VERSION "created by canmatrix"

NS_ :

BS_:

BU_: IBCM ADCU USS SRRL SRRR FRR PBOX DA Meter CCM Sonar BLE ACU CDC None METER Tester

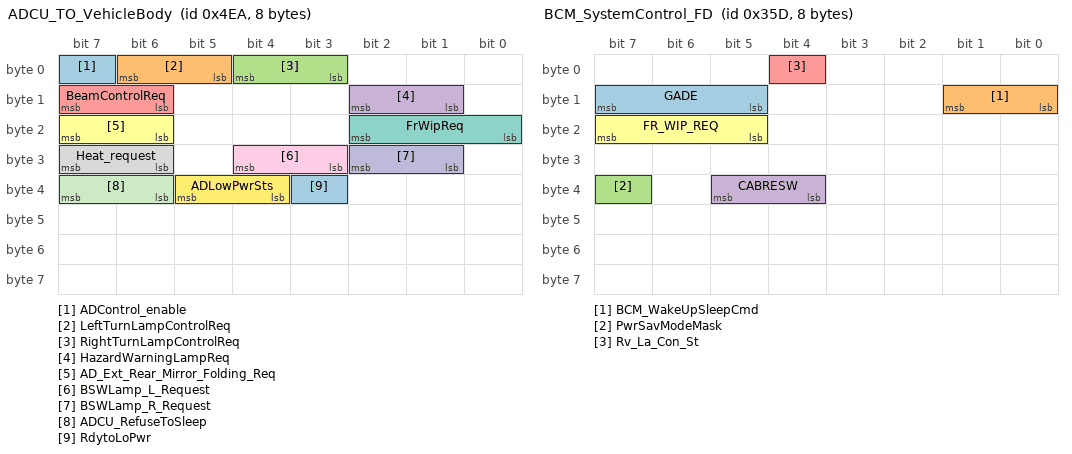
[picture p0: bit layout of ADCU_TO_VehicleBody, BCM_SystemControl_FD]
BO_ 1258 ADCU_TO_VehicleBody: 8 ADCU
 SG_ ADControl_enable : 7|1@0+ (1,0) [0|1] "_" IBCM
 SG_ LeftTurnLampControlReq : 6|2@0+ (1,0) [0|3] "" IBCM
 SG_ RightTurnLampControlReq : 4|2@0+ (1,0) [0|3] "" IBCM
 SG_ HazardWarningLampReq : 10|2@0+ (1,0) [0|3] "" IBCM
 SG_ BeamControlReq : 15|2@0+ (1,0) [0|3] "" IBCM
 SG_ AD_Ext_Rear_Mirror_Folding_Req : 23|2@0+ (1,0) [0|3] "" IBCM
 SG_ FrWipReq : 18|3@0+ (1,0) [0|7] "" IBCM
 SG_ Heat_request : 31|2@0+ (1,0) [0|3] "" IBCM
 SG_ BSWLamp_L_Request : 28|2@0+ (1,0) [0|3] "" IBCM
 SG_ BSWLamp_R_Request : 26|2@0+ (1,0) [0|3] "" IBCM
 SG_ ADCU_RefuseToSleep : 39|2@0+ (1,0) [0|3] "" IBCM
 SG_ ADLowPwrSts : 37|2@0+ (1,0) [0|3] "" IBCM
 SG_ RdytoLoPwr : 35|1@0+ (1,0) [0|1] "" IBCM

BO_ 1293 VCM_HMI_GeneralData1: 8 VCM
 SG_ BAT_RQ : 47|2@0+ (1,0) [0|3] "" ADCU

BO_ 861 BCM_SystemControl_FD: 8 IBCM
 SG_ GADE : 15|3@0+ (1,0) [0|7] "" ADCU,USS,SRRL,SRRR,FRR,PBOX
 SG_ BCM_WakeUpSleepCmd : 9|2@0+ (1,0) [0|3] "" ADCU,USS
 SG_ PwrSavModeMask : 39|1@0+ (1,0) [0|1] "" ADCU
 SG_ CABRESW : 37|2@0+ (1,0) [0|3] "" ADCU
 SG_ Rv_La_Con_St : 4|1@0+ (1,0) [0|1] "" ADCU
 SG_ FR_WIP_REQ : 23|3@0+ (1,0) [0|7] "" ADCU,USS

BO_ 536 PEPS_Message_Sts: 3 IBCM
 SG_ PEPS_POWER_MODE : 7|3@0+ (1,0) [0|7] "" ADCU

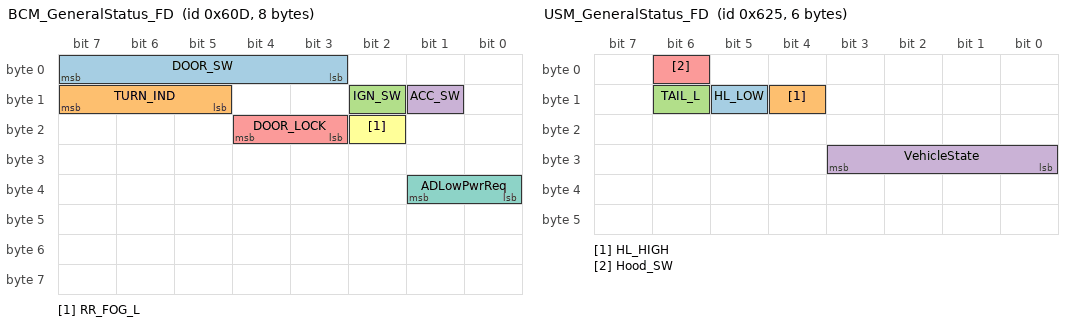
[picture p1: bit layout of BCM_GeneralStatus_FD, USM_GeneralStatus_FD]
BO_ 1549 BCM_GeneralStatus_FD: 8 IBCM_BCM
 SG_ DOOR_SW : 7|5@0+ (1,0) [0|31] "" ADCU,USS
 SG_ TURN_IND : 15|3@0+ (1,0) [0|7] "" ADCU,USS
 SG_ IGN_SW : 10|1@0+ (1,0) [0|1] "" ADCU,USS
 SG_ ACC_SW : 9|1@0+ (1,0) [0|1] "" ADCU,USS
 SG_ DOOR_LOCK : 20|2@0+ (1,0) [0|3] "" ADCU
 SG_ RR_FOG_L : 18|1@0+ (1,0) [0|1] "" ADCU
 SG_ ADLowPwrReq : 33|2@0+ (1,0) [0|3] "" ADCU

BO_ 1573 USM_GeneralStatus_FD: 6 IBCM_USM
 SG_ HL_LOW : 13|1@0+ (1,0) [0|1] "" ADCU,USS
 SG_ HL_HIGH : 12|1@0+ (1,0) [0|1] "" ADCU,USS
 SG_ TAIL_L : 14|1@0+ (1,0) [0|1] "" ADCU,USS
 SG_ VehicleState : 27|4@0+ (1,0) [0|15] "" ADCU,USS
 SG_ Hood_SW : 6|1@0+ (1,0) [0|1] "" ADCU,USS

BO_ 1532 ICOMB_Sw_Msg: 8 COMBI_SW
 SG_ HighLampChangeSWSts : 21|2@0+ (1,0) [0|3] "" ADCU
 SG_ TurnLampSWSts : 31|3@0+ (1,0) [0|7] "" ADCU

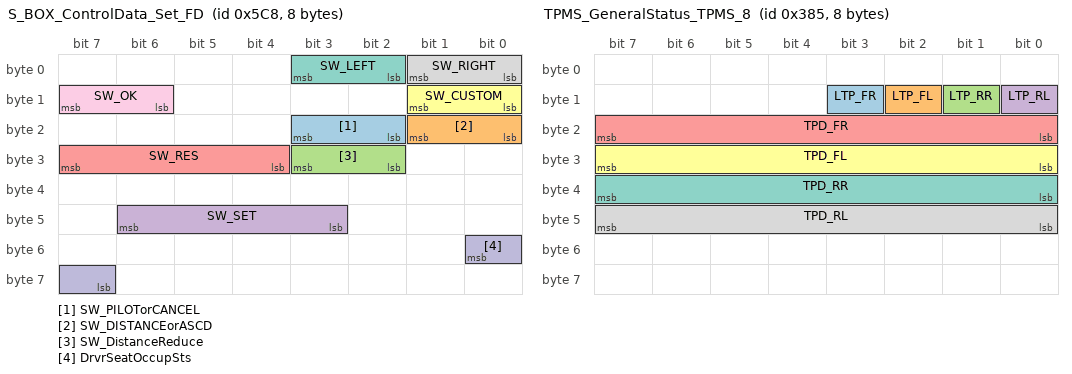
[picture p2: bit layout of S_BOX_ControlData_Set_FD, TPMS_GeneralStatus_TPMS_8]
BO_ 1480 S_BOX_ControlData_Set_FD: 8 IBCM_SBOX
 SG_ SW_PILOTorCANCEL : 19|2@0+ (1,0) [0|3] "" ADCU
 SG_ SW_DISTANCEorASCD : 17|2@0+ (1,0) [0|3] "" ADCU
 SG_ SW_DistanceReduce : 27|2@0+ (1,0) [0|3] "" ADCU
 SG_ SW_SET : 46|4@0+ (1,0) [0|15] "" ADCU
 SG_ SW_RES : 31|4@0+ (1,0) [0|15] "" ADCU
 SG_ SW_CUSTOM : 9|2@0+ (1,0) [0|3] "" ADCU
 SG_ SW_LEFT : 3|2@0+ (1,0) [0|3] "" ADCU,USS
 SG_ SW_RIGHT : 1|2@0+ (1,0) [0|3] "" ADCU,USS
 SG_ SW_OK : 15|2@0+ (1,0) [0|3] "" ADCU,USS
 SG_ DrvrSeatOccupSts : 48|2@0+ (1,0) [0|3] "" ADCU

BO_ 901 TPMS_GeneralStatus_TPMS_8: 8 IBCM_TPMS
 SG_ LTP_FR : 11|1@0+ (1,0) [0|1] "" ADCU,USS
 SG_ LTP_FL : 10|1@0+ (1,0) [0|1] "" ADCU,USS
 SG_ LTP_RR : 9|1@0+ (1,0) [0|1] "" ADCU,USS
 SG_ LTP_RL : 8|1@0+ (1,0) [0|1] "" ADCU,USS
 SG_ TPD_FR : 23|8@0+ (1.7199999999999999733546474089962430298328399658203125,0) [0|438.6] "KPA" ADCU
 SG_ TPD_FL : 31|8@0+ (1.7199999999999999733546474089962430298328399658203125,0) [0|438.6] "KPA" ADCU
 SG_ TPD_RR : 39|8@0+ (1.7199999999999999733546474089962430298328399658203125,0) [0|438.6] "KPA" ADCU
 SG_ TPD_RL : 47|8@0+ (1.7199999999999999733546474089962430298328399658203125,0) [0|438.6] "KPA" ADCU

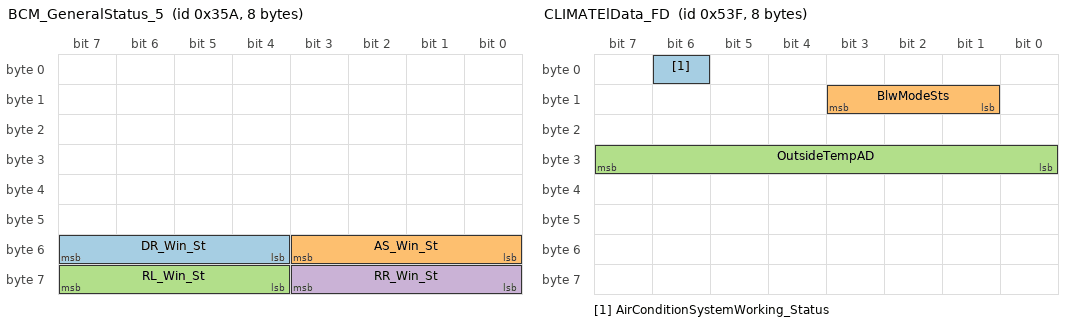
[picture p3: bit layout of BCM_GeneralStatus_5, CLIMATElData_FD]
BO_ 858 BCM_GeneralStatus_5: 8 IBCM_BCM
 SG_ DR_Win_St : 55|4@0+ (1,0) [0|15] "" ADCU
 SG_ AS_Win_St : 51|4@0+ (1,0) [0|15] "" ADCU
 SG_ RL_Win_St : 63|4@0+ (1,0) [0|15] "" ADCU
 SG_ RR_Win_St : 59|4@0+ (1,0) [0|15] "" ADCU

BO_ 1338 FrontRoomLoad_1_FD: 8 IBCM_BCM
 SG_ FrWipSts : 6|2@0+ (1,0) [0|3] "" ADCU,USS
 SG_ LowBatVFb : 15|14@0+ (0.0009765625,3) [3|18] "V" ADCU,SRRL,SRRR

BO_ 1339 LeftBodyLoad_1_FD: 64 IBCM
 SG_ LeftBswLedSts : 18|2@0+ (1,0) [0|3] "" ADCU,SRRL,SRRR
 SG_ RightBswLedSts : 31|2@0+ (1,0) [0|3] "" ADCU,SRRL,SRRR

BO_ 1340 RightBodyLoad_1_FD: 64 IBCM_SBOX
 SG_ PassSeatOccupSts : 23|2@0+ (1,0) [0|3] "" ADCU
 SG_ ExtRMirFldSts : 53|2@0+ (1,0) [0|3] "" ADCU,USS

BO_ 1342 CabinBodyLoad_1: 8 IBCM
 SG_ BcmRainSizeSts : 63|3@0+ (1,0) [0|7] "" ADCU,USS

BO_ 1343 CLIMATElData_FD: 8 IBCM_HVAC
 SG_ AirConditionSystemWorking_Status : 6|1@0+ (1,0) [0|1] "" ADCU
 SG_ BlwModeSts : 11|3@0+ (1,0) [0|7] "" ADCU
 SG_ OutsideTempAD : 31|8@0+ (0.5,-40) [-40|80] "C" ADCU

BO_ 1351 IBCM_HVAC_Info1_FD: 8 IBCM_HVAC
 SG_ Ambient_Temp_Value : 15|8@0+ (0.5,-40) [-40|87] "C" ADCU,USS
 SG_ Inner_Temp_Value : 23|8@0+ (0.5,-40) [-40|87] "C" ADCU

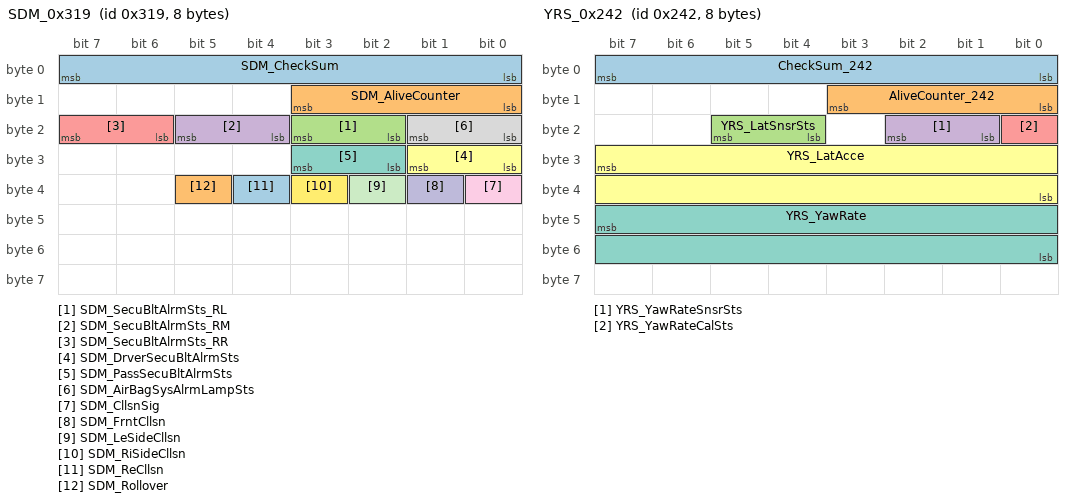
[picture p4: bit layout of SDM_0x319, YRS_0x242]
BO_ 793 SDM_0x319: 8 ACU
 SG_ SDM_CheckSum : 7|8@0+ (1,0) [0|255] "" ADCU,USS
 SG_ SDM_AliveCounter : 11|4@0+ (1,0) [0|15] "" ADCU,USS
 SG_ SDM_SecuBltAlrmSts_RL : 19|2@0+ (1,0) [0|3] "" ADCU,USS
 SG_ SDM_SecuBltAlrmSts_RM : 21|2@0+ (1,0) [0|3] "" ADCU,USS
 SG_ SDM_SecuBltAlrmSts_RR : 23|2@0+ (1,0) [0|3] "" ADCU,USS
 SG_ SDM_DrverSecuBltAlrmSts : 25|2@0+ (1,0) [0|3] "" ADCU,USS
 SG_ SDM_PassSecuBltAlrmSts : 27|2@0+ (1,0) [0|3] "" ADCU,USS
 SG_ SDM_AirBagSysAlrmLampSts : 17|2@0+ (1,0) [0|3] "" ADCU,USS
 SG_ SDM_CllsnSig : 32|1@0+ (1,0) [0|1] "" ADCU,USS
 SG_ SDM_FrntCllsn : 33|1@0+ (1,0) [0|1] "" ADCU,USS
 SG_ SDM_LeSideCllsn : 34|1@0+ (1,0) [0|1] "" ADCU,USS
 SG_ SDM_RiSideCllsn : 35|1@0+ (1,0) [0|1] "" ADCU,USS
 SG_ SDM_ReCllsn : 36|1@0+ (1,0) [0|1] "" ADCU,USS
 SG_ SDM_Rollover : 37|1@0+ (1,0) [0|1] "" ADCU,USS

BO_ 578 YRS_0x242: 8 ACU
 SG_ CheckSum_242 : 7|8@0+ (1,0) [0|255] "" ADCU,USS,SRRL,SRRR,FRR
 SG_ AliveCounter_242 : 11|4@0+ (1,0) [0|15] "" ADCU,USS,SRRL,SRRR,FRR
 SG_ YRS_LatSnsrSts : 21|2@0+ (1,0) [0|3] "" ADCU,USS
 SG_ YRS_YawRateSnsrSts : 18|2@0+ (1,0) [0|3] "" ADCU,USS
 SG_ YRS_YawRateCalSts : 16|1@0+ (1,0) [0|1] "" ADCU,USS
 SG_ YRS_LatAcce : 31|16@0+ (0.001,-2) [-2|2] "g" ADCU,USS,SRRL,SRRR,FRR
 SG_ YRS_YawRate : 47|16@0+ (0.01,-180) [-180|180] "deg_s" ADCU,USS,SRRL,SRRR,FRR

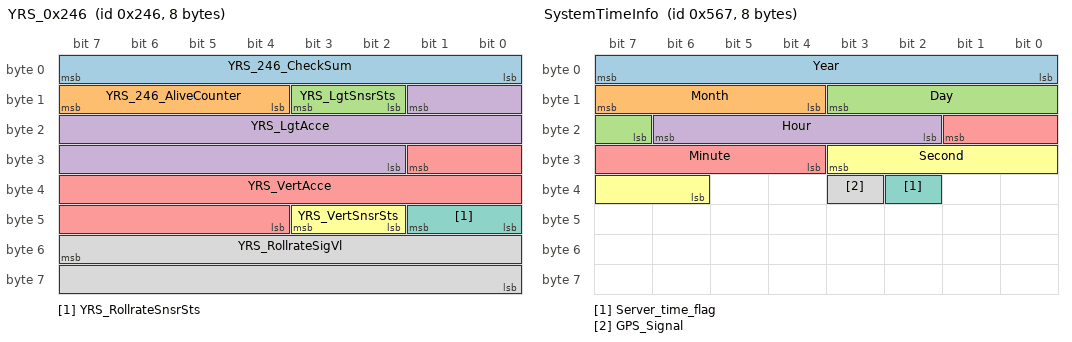
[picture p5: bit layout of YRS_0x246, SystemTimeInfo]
BO_ 582 YRS_0x246: 8 ACU
 SG_ YRS_246_CheckSum : 7|8@0+ (1,0) [0|255] "" ADCU,USS,SRRL,SRRR,FRR
 SG_ YRS_246_AliveCounter : 15|4@0+ (1,0) [0|15] "" ADCU,USS,SRRL,SRRR,FRR
 SG_ YRS_LgtSnsrSts : 11|2@0+ (1,0) [0|3] "" ADCU,USS
 SG_ YRS_LgtAcce : 9|16@0+ (0.001,-2) [-2|2] "g" ADCU,USS,SRRL,SRRR,FRR
 SG_ YRS_VertAcce : 25|14@0+ (0.001,-5) [-5|5] "g" ADCU
 SG_ YRS_VertSnsrSts : 43|2@0+ (1,0) [0|3] "" ADCU
 SG_ YRS_RollrateSnsrSts : 41|2@0+ (1,0) [0|3] "" ADCU
 SG_ YRS_RollrateSigVl : 55|16@0+ (0.01,-300) [-300|300] "deg_s" ADCU

BO_ 1383 SystemTimeInfo: 8 DA
 SG_ Year : 7|8@0+ (1,2000) [2000|2255] "" ADCU,USS
 SG_ Month : 15|4@0+ (1,0) [0|15] "" ADCU,USS
 SG_ Day : 11|5@0+ (1,0) [0|31] "" ADCU,USS
 SG_ Hour : 22|5@0+ (1,0) [0|31] "" ADCU,USS
 SG_ Minute : 17|6@0+ (1,0) [0|63] "" ADCU,USS
 SG_ Second : 27|6@0+ (1,0) [0|63] "" ADCU,USS
 SG_ Server_time_flag : 34|1@0+ (1,0) [0|1] "" ADCU,USS
 SG_ GPS_Signal : 35|1@0+ (1,0) [0|1] "" ADCU,USS

BO_ 1477 CLUSTER_GeneralStatus: 8 Meter
 SG_ DIS_TOTAL : 15|24@0+ (0.1000000000000000055511151231257827021181583404541015625,0) [0|1600000] "km" ADCU,USS

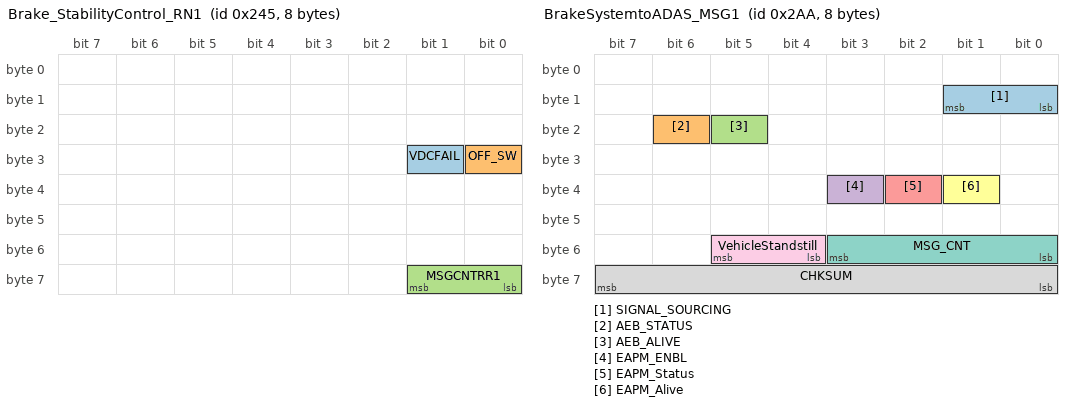
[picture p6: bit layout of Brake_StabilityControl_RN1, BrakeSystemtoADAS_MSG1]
BO_ 581 Brake_StabilityControl_RN1: 8 IBC
 SG_ VDCFAIL : 25|1@0+ (1,0) [0|1] "" USS
 SG_ OFF_SW : 24|1@0+ (1,0) [0|1] "" USS
 SG_ MSGCNTRR1 : 57|2@0+ (1,0) [0|3] "" USS

BO_ 682 BrakeSystemtoADAS_MSG1: 8 IBC
 SG_ SIGNAL_SOURCING : 9|2@0+ (1,0) [0|3] "" USS
 SG_ AEB_STATUS : 22|1@0+ (1,0) [0|1] "" USS
 SG_ AEB_ALIVE : 21|1@0+ (1,0) [0|1] "" USS
 SG_ EAPM_ENBL : 35|1@0+ (1,0) [0|1] "" USS
 SG_ EAPM_Status : 34|1@0+ (1,0) [0|1] "" USS
 SG_ EAPM_Alive : 33|1@0+ (1,0) [0|1] "" USS
 SG_ MSG_CNT : 51|4@0+ (1,0) [0|15] "" USS
 SG_ CHKSUM : 63|8@0+ (1,0) [0|255] "" USS
 SG_ VehicleStandstill : 53|2@0+ (1,0) [0|3] "" USS

BO_ 852 Brake_GeneralData: 8 IBC
 SG_ MSGCNTR : 44|2@0+ (1,0) [0|3] "" USS
 SG_ STPLMSW : 53|2@0+ (1,0) [0|3] "" USS

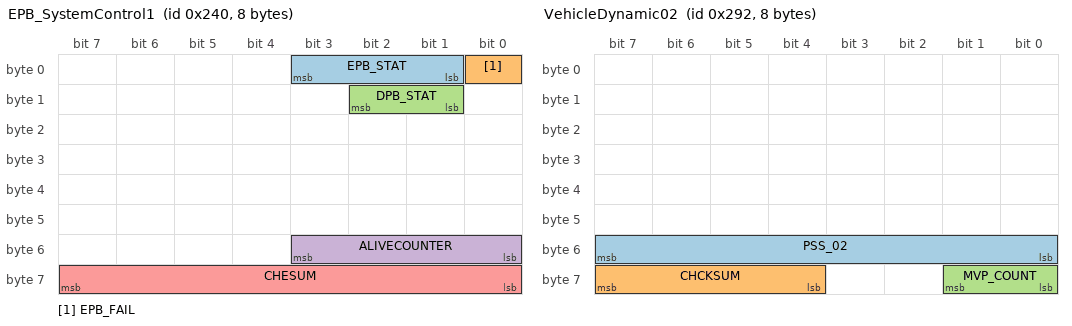
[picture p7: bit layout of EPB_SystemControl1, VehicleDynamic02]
BO_ 576 EPB_SystemControl1: 8 IBC
 SG_ EPB_STAT : 3|3@0+ (1,0) [0|7] "" USS
 SG_ EPB_FAIL : 0|1@0+ (1,0) [0|1] "" USS
 SG_ DPB_STAT : 10|2@0+ (1,0) [0|3] "" USS
 SG_ ALIVECOUNTER : 51|4@0+ (1,0) [0|15] "" USS
 SG_ CHESUM : 63|8@0+ (1,0) [0|255] "" USS

BO_ 658 VehicleDynamic02: 8 IBC
 SG_ PSS_02 : 55|8@0+ (1,0) [0|254] "bar" USS
 SG_ CHCKSUM : 63|4@0+ (1,0) [0|15] "" USS
 SG_ MVP_COUNT : 57|2@0+ (1,0) [0|3] "" USS

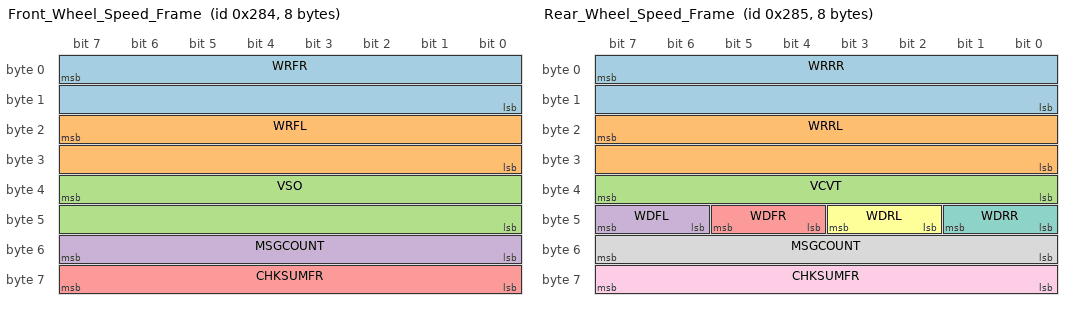
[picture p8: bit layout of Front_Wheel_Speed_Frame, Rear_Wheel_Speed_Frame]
BO_ 644 Front_Wheel_Speed_Frame: 8 IBC
 SG_ WRFR : 7|16@0+ (0.04166666666666669904817155156706576235592365264892578125,0) [0|2730.58333333333] "rpm" USS
 SG_ WRFL : 23|16@0+ (0.04166666666666669904817155156706576235592365264892578125,0) [0|2730.58333333333] "rpm" USS
 SG_ VSO : 39|16@0+ (0.01000000000000000020816681711721685132943093776702880859375,0) [0|655.34] "km_h" USS
 SG_ MSGCOUNT : 55|8@0+ (1,0) [0|255] "" USS
 SG_ CHKSUMFR : 63|8@0+ (1,0) [0|255] "" USS

BO_ 645 Rear_Wheel_Speed_Frame: 8 IBC
 SG_ WRRR : 7|16@0+ (0.04166666666666669904817155156706576235592365264892578125,0) [0|2730.58333333333] "rpm" USS
 SG_ WRRL : 23|16@0+ (0.04166666666666669904817155156706576235592365264892578125,0) [0|2730.58333333333] "rpm" USS
 SG_ VCVT : 39|8@0+ (1,0) [0|255] "km_h" USS
 SG_ WDFL : 47|2@0+ (1,0) [0|3] "" USS
 SG_ WDFR : 45|2@0+ (1,0) [0|3] "" USS
 SG_ WDRL : 43|2@0+ (1,0) [0|3] "" USS
 SG_ WDRR : 41|2@0+ (1,0) [0|3] "" USS
 SG_ MSGCOUNT : 55|8@0+ (1,0) [0|255] "" USS
 SG_ CHKSUMFR : 63|8@0+ (1,0) [0|255] "" USS

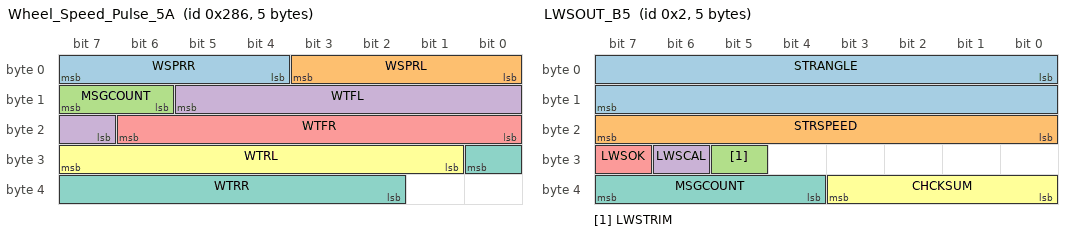
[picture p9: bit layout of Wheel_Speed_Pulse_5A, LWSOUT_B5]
BO_ 646 Wheel_Speed_Pulse_5A: 5 IBC
 SG_ WSPRR : 7|4@0+ (1,0) [0|14] "" USS
 SG_ WSPRL : 3|4@0+ (1,0) [0|14] "" USS
 SG_ MSGCOUNT : 15|2@0+ (1,0) [0|3] "" USS
 SG_ WTFL : 13|7@0+ (1,0) [1|96] "top" USS
 SG_ WTFR : 22|7@0+ (1,0) [1|96] "top" USS
 SG_ WTRL : 31|7@0+ (1,0) [1|96] "top" USS
 SG_ WTRR : 24|7@0+ (1,0) [1|96] "top" USS

BO_ 2 LWSOUT_B5: 5 EPS
 SG_ STRANGLE : 0|16@1- (0.1000000000000000055511151231257827021181583404541015625,0) [-780|780] "deg" USS
 SG_ STRSPEED : 16|8@1+ (4,0) [0|1016] "deg_s" USS
 SG_ LWSTRIM : 29|1@1+ (1,0) [0|1] "" USS
 SG_ LWSCAL : 30|1@1+ (1,0) [0|1] "" USS
 SG_ LWSOK : 31|1@1+ (1,0) [0|1] "" USS
 SG_ CHCKSUM : 32|4@1+ (1,0) [0|15] "" USS
 SG_ MSGCOUNT : 36|4@1+ (1,0) [0|15] "" USS

BO_ 500 VCM_ADCU_01: 8 VCM
 SG_ PT_MotoSpd : 7|16@0- (1,0) [-32768|32767] "rpm" USS
 SG_ PT_MotoSpdV : 41|1@0+ (1,0) [0|1] "" USS

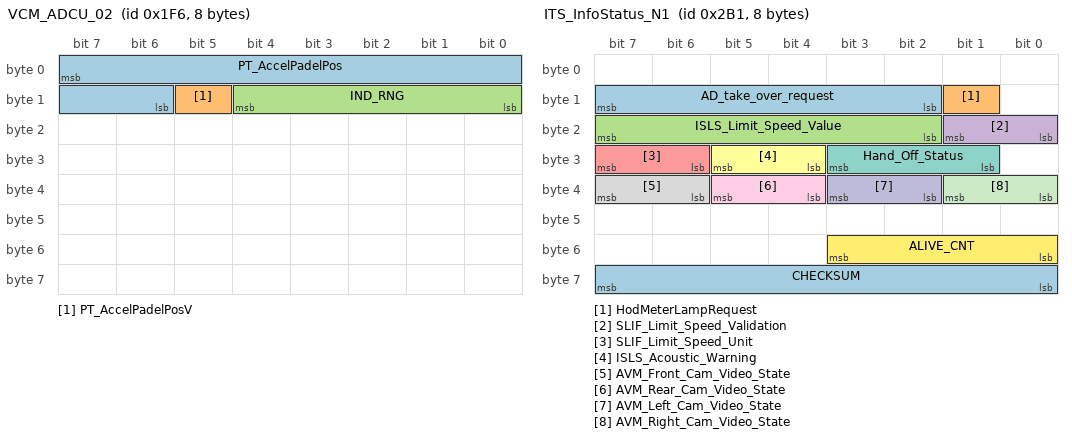
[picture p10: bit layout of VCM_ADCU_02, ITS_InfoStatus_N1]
BO_ 502 VCM_ADCU_02: 8 VCM
 SG_ PT_AccelPadelPos : 7|10@0+ (0.1000000000000000055511151231257827021181583404541015625,0) [0|102.3] "pct" USS
 SG_ PT_AccelPadelPosV : 13|1@0+ (1,0) [0|1] "" USS
 SG_ IND_RNG : 12|5@0+ (1,0) [0|31] "" USS

BO_ 384 ECM_TorqueControl_RN1: 8 VCM
 SG_ P_RUN : 51|4@0+ (1,0) [0|15] "" USS
 SG_ ETCFAIL : 63|3@0+ (1,0) [0|7] "" USS

BO_ 1361 ECM_GeneralStatus: 8 VCM
 SG_ ENG_STA : 41|2@0+ (1,0) [0|3] "" USS

BO_ 1449 VCM_HMI_GeneralData5_Quk: 8 VCM
 SG_ DTE_VCM : 15|13@0+ (0.1000000000000000055511151231257827021181583404541015625,0) [0|819] "km" ADCU

BO_ 689 ITS_InfoStatus_N1: 8 ADCU
 SG_ AD_take_over_request : 15|6@0+ (1,0) [0|63] "" DA,Meter
 SG_ HodMeterLampRequest : 9|1@0+ (1,0) [0|1] "" DA,Meter
 SG_ ISLS_Limit_Speed_Value : 23|6@0+ (1,0) [0|63] "" DA,Meter
 SG_ SLIF_Limit_Speed_Validation : 17|2@0+ (1,0) [0|3] "" DA,Meter
 SG_ SLIF_Limit_Speed_Unit : 31|2@0+ (1,0) [0|3] "" DA,Meter
 SG_ ISLS_Acoustic_Warning : 29|2@0+ (1,0) [0|3] "" DA,Meter
 SG_ Hand_Off_Status : 27|3@0+ (1,0) [0|7] "" DA,Meter,CCM
 SG_ AVM_Front_Cam_Video_State : 39|2@0+ (1,0) [0|3] "" DA,Meter
 SG_ AVM_Rear_Cam_Video_State : 37|2@0+ (1,0) [0|3] "" DA,Meter
 SG_ AVM_Left_Cam_Video_State : 35|2@0+ (1,0) [0|3] "" DA,Meter
 SG_ AVM_Right_Cam_Video_State : 33|2@0+ (1,0) [0|3] "" DA,Meter
 SG_ ALIVE_CNT : 51|4@0+ (1,0) [0|15] "" DA,Meter
 SG_ CHECKSUM : 63|8@0+ (1,0) [0|255] "" DA,Meter

BO_ 695 ITS_InfoStatus_N2: 8 ADCU
 SG_ PCW_PreWarning : 6|1@0+ (1,0) [0|1] "" DA,Meter
 SG_ AEB_Active : 5|1@0+ (1,0) [0|1] "" DA,Meter
 SG_ CDW_Active : 0|1@0+ (1,0) [0|1] "" DA,Meter
 SG_ ESS_Active : 15|2@0+ (1,0) [0|3] "" DA,Meter
 SG_ fcta_left_warning : 13|1@0+ (1,0) [0|1] "" DA,Meter
 SG_ fcta_front_warning : 12|1@0+ (1,0) [0|1] "" DA,Meter
 SG_ fcta_right_warning : 11|1@0+ (1,0) [0|1] "" DA,Meter
 SG_ fctb_left_warning : 23|1@0+ (1,0) [0|1] "" DA,Meter
 SG_ fctb_front_warning : 22|1@0+ (1,0) [0|1] "" DA,Meter
 SG_ fctb_right_warning : 21|1@0+ (1,0) [0|1] "" DA,Meter
 SG_ rctb_left_warning : 20|1@0+ (1,0) [0|1] "" DA,Meter
 SG_ rctb_rear_warning : 19|1@0+ (1,0) [0|1] "" DA,Meter
 SG_ rctb_right_warning : 18|1@0+ (1,0) [0|1] "" DA,Meter
 SG_ ELK_active : 31|3@0+ (1,0) [0|7] "" DA,Meter
 SG_ rcta_left_warning : 10|1@0+ (1,0) [0|1] "" DA,Meter
 SG_ rcta_rear_warning : 9|1@0+ (1,0) [0|1] "" DA,Meter
 SG_ rcta_right_warning : 8|1@0+ (1,0) [0|1] "" DA,Meter
 SG_ rcw_warning : 28|1@0+ (1,0) [0|1] "" DA,Meter
 SG_ left_bsw_warning : 27|2@0+ (1,0) [0|3] "" DA,Meter
 SG_ right_bsw_warning : 25|2@0+ (1,0) [0|3] "" DA,Meter
 SG_ left_dow_warning : 39|2@0+ (1,0) [0|3] "" DA,Meter,CCM
 SG_ right_dow_warning : 37|2@0+ (1,0) [0|3] "" DA,Meter,CCM
 SG_ LDW_Warning : 35|2@0+ (1,0) [0|3] "" DA,Meter
 SG_ LDP_Active : 33|2@0+ (1,0) [0|3] "" DA,Meter
 SG_ STS_D_MEB : 47|3@0+ (1,0) [0|7] "" DA,Meter
 SG_ SET_MEB : 44|2@0+ (1,0) [0|3] "" DA,Meter
 SG_ STS_W_MEB : 42|2@0+ (1,0) [0|3] "" DA,Meter
 SG_ SOUND_MEB : 40|1@0+ (1,0) [0|1] "" DA,Meter
 SG_ ALIVE_CNT : 51|4@0+ (1,0) [0|15] "" DA,Meter
 SG_ CHECKSUM : 63|8@0+ (1,0) [0|255] "" DA,Meter

BO_ 1260 ITS_InfoStatus_N2_2: 64 ADCU
 SG_ ACC_HEADW_SET : 7|3@0+ (1,0) [0|7] "" DA,Meter
 SG_ VDC_NOT_ACTIVATED : 4|1@0+ (1,0) [0|1] "" DA,Meter
 SG_ ACC_DrSeSp : 15|8@0+ (1,0) [0|255] "km_h" DA,Meter
 SG_ ACC_DisToTgt : 23|8@0+ (1,0) [0|255] "m" DA,Meter
 SG_ ACC_TgtDet : 31|1@0+ (1,0) [0|1] "" DA,Meter
 SG_ ACC_GoNoti : 30|1@0+ (1,0) [0|1] "" DA,Meter
 SG_ CP_Status : 29|4@0+ (1,0) [0|15] "" DA,Meter
 SG_ MSG_ILC_Opera : 25|2@0+ (1,0) [0|3] "" DA,Meter
 SG_ CP_PLC_Status : 39|4@0+ (1,0) [0|15] "" DA,Meter
 SG_ CP_PLC_Direction : 35|2@0+ (1,0) [0|3] "" DA,Meter
 SG_ Message_AD_unActive_Reason : 47|4@0+ (1,0) [0|15] "" DA,Meter
 SG_ ACC_Status : 43|4@0+ (1,0) [0|15] "" DA,Meter
 SG_ AD_Notice_Information : 55|8@0+ (1,0) [0|255] "" DA,Meter
 SG_ ISLC_Comfirm_Request : 57|1@0+ (1,0) [0|1] "" DA,Meter
 SG_ STATUS_CHANGE_ALERT : 56|1@0+ (1,0) [0|1] "" DA,Meter
 SG_ HnpLastDistance : 67|4@0+ (1,0) [0|15] "" DA,Meter
 SG_ AD_ICON : 79|5@0+ (1,0) [0|31] "" DA,Meter
 SG_ HNP_Status : 87|6@0+ (1,0) [0|63] "" DA,Meter
 SG_ HNP_Lane_Change_Status : 91|4@0+ (1,0) [0|15] "" DA,Meter
 SG_ Message_AD_Error : 103|1@0+ (1,0) [0|1] "" DA,Meter
 SG_ Message_Inclement_weather : 102|2@0+ (1,0) [0|3] "" DA,Meter
 SG_ Message_FR_Camera_block : 100|1@0+ (1,0) [0|1] "" DA,Meter
 SG_ Message_FR_Radar_block : 99|1@0+ (1,0) [0|1] "" DA,Meter
 SG_ Msg_Side_Fisheye_Camera_block : 98|1@0+ (1,0) [0|1] "" DA,Meter
 SG_ Message_Rear_Camera_block : 97|1@0+ (1,0) [0|1] "" DA,Meter
 SG_ Message_Side_Rear_Radar_block : 96|1@0+ (1,0) [0|1] "" DA,Meter
 SG_ SETTING_LDW_LDP_Status : 111|2@0+ (1,0) [0|3] "" DA,Meter
 SG_ LDW__INFO : 109|3@0+ (1,0) [0|7] "" DA,Meter
 SG_ SET_LDW_SENS_Status : 106|3@0+ (1,0) [0|7] "" DA,Meter
 SG_ AEBS_INFO : 117|3@0+ (1,0) [0|7] "" DA,Meter
 SG_ SET_FCW_SENS_Status : 114|3@0+ (1,0) [0|7] "" DA,Meter
 SG_ SETTING_AEBS_Status : 127|2@0+ (1,0) [0|3] "" DA,Meter
 SG_ LDP_INFO : 123|3@0+ (1,0) [0|7] "" DA,Meter
 SG_ SETTING_ELK_Status : 135|2@0+ (1,0) [0|3] "" DA,Meter
 SG_ ELK_INFO : 133|3@0+ (1,0) [0|7] "" DA,Meter
 SG_ SETTING_ESS_Status : 130|2@0+ (1,0) [0|3] "" DA,Meter
 SG_ ESS_INFO : 143|3@0+ (1,0) [0|7] "" DA,Meter
 SG_ SET_PILOT_STA : 140|3@0+ (1,0) [0|7] "" DA,Meter
 SG_ SET_ILC_STA : 151|2@0+ (1,0) [0|3] "" DA,Meter
 SG_ SET_IHC_STA : 149|2@0+ (1,0) [0|3] "" DA,Meter
 SG_ SET_PLC_STA : 147|2@0+ (1,0) [0|3] "" DA,Meter
 SG_ ISLS_INFO : 157|3@0+ (1,0) [0|7] "" DA,Meter
 SG_ SET_TSR_status : 154|2@0+ (1,0) [0|3] "" DA,Meter
 SG_ TSR_INFO : 167|3@0+ (1,0) [0|7] "" DA,Meter
 SG_ SET_TLA_status : 164|2@0+ (1,0) [0|3] "" DA,Meter
 SG_ SET_TLAS_status : 162|3@0+ (1,0) [0|3] "None" DA
 SG_ TLA__INFO : 175|3@0+ (1,0) [0|7] "" DA,Meter
 SG_ SET_RCTA_RCTB_status : 172|2@0+ (1,0) [0|3] "" DA,Meter
 SG_ RCTA_INFO : 170|3@0+ (1,0) [0|7] "" DA,Meter
 SG_ RCTB_INFO : 181|3@0+ (1,0) [0|7] "" DA,Meter
 SG_ SET_FCTA_FCTB_status : 178|2@0+ (1,0) [0|3] "" DA,Meter
 SG_ FCTA_INFO : 191|3@0+ (1,0) [0|7] "" DA,Meter
 SG_ FCTB_INFO : 186|3@0+ (1,0) [0|7] "" DA,Meter
 SG_ SET_BSW_status : 199|2@0+ (1,0) [0|3] "" DA,Meter
 SG_ BSW_INFO : 197|3@0+ (1,0) [0|7] "" DA,Meter
 SG_ SET_DOW_status : 194|2@0+ (1,0) [0|3] "" DA,Meter
 SG_ DOW_INFO : 207|3@0+ (1,0) [0|7] "" DA,Meter
 SG_ SET_RCW_status : 204|2@0+ (1,0) [0|3] "" DA,Meter
 SG_ RCW_INFO : 202|3@0+ (1,0) [0|7] "" DA,Meter
 SG_ SET_VOL_STA : 213|2@0+ (1,0) [0|3] "" DA,Meter
 SG_ SET_CDW_SENS_Status : 211|3@0+ (1,0) [0|7] "" DA,Meter
 SG_ SET_ISLC_OFT_STA : 223|5@0+ (1,-16) [-16|15] "pct" DA,Meter
 SG_ SETTING_CDW_Status : 218|2@0+ (1,0) [0|3] "" DA,Meter
 SG_ MSG_FR_Camera_H_Temp : 231|1@0+ (1,0) [0|1] "" DA,Meter
 SG_ MSG_RR_Camera_H_Temp : 230|1@0+ (1,0) [0|1] "" DA,Meter
 SG_ MSG_ADCU_H_Temp : 229|1@0+ (1,0) [0|1] "" DA,Meter
 SG_ MSG_fisheye_Camera_H_Temp : 228|1@0+ (1,0) [0|1] "" DA,Meter
 SG_ MSG_VDC_NO_Actived : 227|1@0+ (1,0) [0|1] "" DA,Meter
 SG_ SET_ISLS_STA : 239|3@0+ (1,0) [0|7] "" DA,Meter
 SG_ SALC_INFO : 236|3@0+ (1,0) [0|7] "" DA,Meter
 SG_ HNPDowngradeStatus : 247|3@0+ (1,0) [0|7] "" DA,Meter
 SG_ CPUpgradeStatus : 244|3@0+ (1,0) [0|7] "" DA,Meter
 SG_ HNPLaneChangeStyleStatus : 241|2@0+ (1,0) [0|3] "" DA,Meter
 SG_ HNPLanePreferenceStatus : 255|3@0+ (1,0) [0|7] "" DA,Meter
 SG_ TSR_DISP : 263|5@0+ (1,0) [0|31] "" DA,Meter
 SG_ TLA_Pattern : 258|3@0+ (1,0) [0|7] "" DA,Meter
 SG_ Left_Uturn_Indication : 271|3@0+ (1,0) [0|7] "" DA,Meter
 SG_ Turn_Left_Indication : 268|3@0+ (1,0) [0|7] "" DA,Meter
 SG_ Go_Stright_Indication : 279|3@0+ (1,0) [0|7] "" DA,Meter
 SG_ Trun_Right_Indication : 276|3@0+ (1,0) [0|7] "" DA,Meter
 SG_ TLA_Number : 287|4@0+ (1,0) [0|15] "" DA,Meter
 SG_ ALC_Confirm : 283|2@0+ (1,0) [0|3] "" DA,Meter
 SG_ DVR_InfoStatus : 281|2@0+ (1,0) [0|3] "" DA,Meter
 SG_ MESSAGE_DVR_WARN : 295|1@0+ (1,0) [0|1] "" DA,Meter
 SG_ CDW_INFO : 294|3@0+ (1,0) [0|7] "" DA,Meter
 SG_ AD_Safety_Event : 335|8@0+ (1,0) [0|1] "None" CCM
 SG_ CFDI_ALL_Sts : 495|2@0+ (1,0) [0|3] "" DA
 SG_ CFDI_DeletePDDATA_Sts : 493|2@0+ (1,0) [0|3] "" DA
 SG_ AliveCounter : 499|4@0+ (1,0) [0|15] "" DA,Meter
 SG_ CHECKSUM : 511|8@0+ (1,0) [0|255] "" DA,Meter

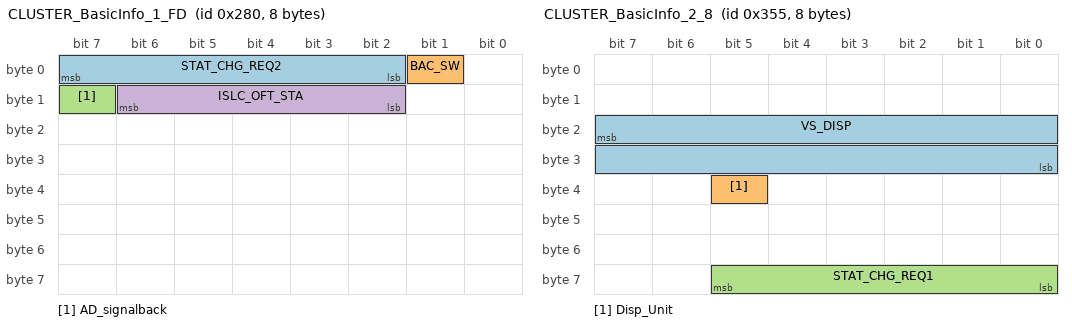
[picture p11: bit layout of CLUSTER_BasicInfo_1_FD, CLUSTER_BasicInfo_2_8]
BO_ 640 CLUSTER_BasicInfo_1_FD: 8 Meter
 SG_ STAT_CHG_REQ2 : 7|6@0+ (1,0) [0|63] "" ADCU
 SG_ BAC_SW : 1|1@0+ (1,0) [0|1] "" ADCU
 SG_ AD_signalback : 15|1@0+ (1,0) [0|1] "" ADCU
 SG_ ISLC_OFT_STA : 14|5@0+ (1,-16) [-16|15] "pct" ADCU

BO_ 853 CLUSTER_BasicInfo_2_8: 8 Meter
 SG_ VS_DISP : 23|16@0+ (0.01000000000000000020816681711721685132943093776702880859375,0) [0|655.34] "km_h" ADCU,Sonar
 SG_ Disp_Unit : 37|1@0+ (1,0) [0|1] "" ADCU,Sonar
 SG_ STAT_CHG_REQ1 : 61|6@0+ (1,0) [0|63] "" ADCU,Sonar

BO_ 1402 SONAR_GeneralStatus_8: 16 ADCU
 SG_ REQ_DISP_MET : 7|1@0+ (1,0) [0|1] "" Meter,DA
 SG_ REQ_DISP_CEN : 6|1@0+ (1,0) [0|1] "" Meter,DA
 SG_ SONAR_S_REQ : 39|3@0+ (1,0) [0|7] "" Meter,DA
 SG_ STS_SETTING : 3|1@0+ (1,0) [0|1] "" Meter,DA
 SG_ RR_CEN : 15|3@0+ (1,0) [0|7] "" Meter,DA,BLE
 SG_ A_RR_CEN : 12|1@0+ (1,0) [0|1] "" Meter,DA,BLE
 SG_ FR_CEN : 11|3@0+ (1,0) [0|7] "" Meter,DA,BLE
 SG_ A_FR_CEN : 8|1@0+ (1,0) [0|1] "" Meter,DA,BLE
 SG_ RR_L : 23|3@0+ (1,0) [0|7] "" Meter,DA,BLE
 SG_ A_RR_L : 20|1@0+ (1,0) [0|1] "" Meter,DA,BLE
 SG_ RR_R : 19|3@0+ (1,0) [0|7] "" Meter,DA,BLE
 SG_ A_RR_R : 16|1@0+ (1,0) [0|1] "" Meter,DA,BLE
 SG_ FR_L : 31|3@0+ (1,0) [0|7] "" Meter,DA,BLE
 SG_ A_FR_L : 28|1@0+ (1,0) [0|1] "" Meter,DA,BLE
 SG_ FR_R : 27|3@0+ (1,0) [0|7] "" Meter,DA,BLE
 SG_ A_FR_R : 24|1@0+ (1,0) [0|1] "" Meter,DA,BLE
 SG_ STS_DISTANCE : 62|5@0+ (1,0) [0|31] "" Meter,DA,BLE
 SG_ STS_AUTO_DISP : 43|1@0+ (1,0) [0|1] "" Meter,DA
 SG_ STS_SYS_MODE : 42|3@0+ (1,0) [0|7] "" Meter,DA
 SG_ SOUND_ZONE : 50|3@0+ (1,0) [0|7] "" Meter,DA
 SG_ SOUND_CONT : 63|1@0+ (1,0) [0|1] "" Meter,DA
 SG_ SOUND_LEVEL : 55|3@0+ (1,0) [0|7] "" Meter,DA
 SG_ SONAR_Detect_Distance_F : 108|5@0+ (1,0) [0|31] "" Meter,DA,BLE
 SG_ RangeStatus_RR_Right_side : 127|3@0+ (1,0) [0|7] "" Meter,DA,BLE
 SG_ Availavility_RR_CornerRight_side : 124|1@0+ (1,0) [0|1] "" Meter,DA,BLE
 SG_ RangeStatus_RR_left_side : 123|3@0+ (1,0) [0|7] "" Meter,DA,BLE
 SG_ Availavility_RR_Cornerleft_side : 120|1@0+ (1,0) [0|1] "" Meter,DA,BLE
 SG_ RangeStatus_FR_Right_side : 119|3@0+ (1,0) [0|7] "" Meter,DA,BLE
 SG_ Availavility_FR_CornerRight_side : 116|1@0+ (1,0) [0|1] "" Meter,DA,BLE
 SG_ RangeStatus_FR_Left_side : 115|3@0+ (1,0) [0|7] "" Meter,DA,BLE
 SG_ Availavility_FR_CornerLeft_side : 112|1@0+ (1,0) [0|1] "" Meter,DA,BLE
 SG_ SoundObstacleZone_Request : 111|3@0+ (1,0) [0|7] "" Meter,DA

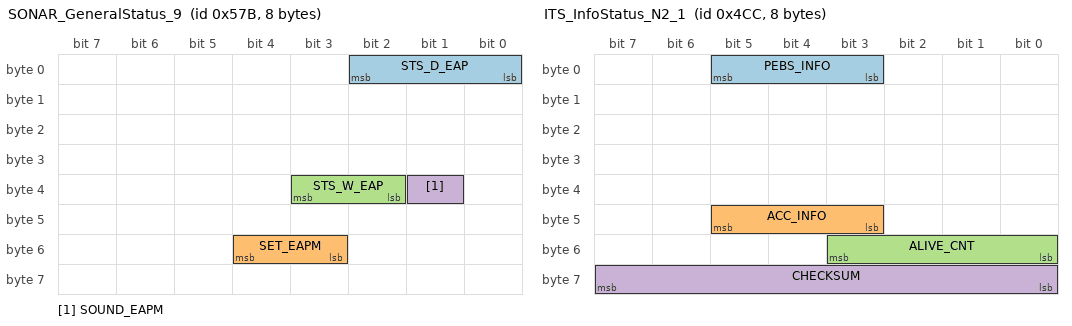
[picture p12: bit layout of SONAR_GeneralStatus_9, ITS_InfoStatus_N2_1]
BO_ 1403 SONAR_GeneralStatus_9: 8 ADCU
 SG_ STS_D_EAP : 2|3@0+ (1,0) [0|7] "" Meter,DA
 SG_ SET_EAPM : 52|2@0+ (1,0) [0|3] "" Meter,DA
 SG_ STS_W_EAP : 35|2@0+ (1,0) [0|3] "" Meter,DA
 SG_ SOUND_EAPM : 33|1@0+ (1,0) [0|1] "" Meter,DA

BO_ 1405 AP_HMI_System: 64 ADCU
 SG_ APA_Function_Status : 7|3@0+ (1,0) [0|7] "" DA,BLE,Meter,USS
 SG_ APA_Park_Mode : 4|2@0+ (1,0) [0|3] "" DA,BLE,Meter
 SG_ APA_Control_Mode : 2|2@0+ (1,0) [0|3] "" DA,BLE,IBCM,Meter
 SG_ APA_Page_Type : 15|4@0+ (1,0) [0|15] "" DA,Meter
 SG_ HPA_Try_Guidance : 23|3@0+ (1,0) [0|7] "" DA,Meter
 SG_ HPA_Function_Status : 20|4@0+ (1,0) [0|15] "" DA,Meter,USS
 SG_ APA_Enter_Switch_Status : 31|2@0+ (1,0) [0|3] "" DA,Meter
 SG_ APA_Exit_Switch_Status : 29|2@0+ (1,0) [0|3] "" DA,Meter
 SG_ APA_Button0_Status : 27|2@0+ (1,0) [0|3] "" DA,Meter
 SG_ APA_Button1_Status : 25|2@0+ (1,0) [0|3] "" DA,Meter
 SG_ APA_Button2_Status : 39|3@0+ (1,0) [0|7] "" DA,Meter
 SG_ APA_Button3_Status : 36|2@0+ (1,0) [0|3] "" DA,Meter
 SG_ APA_Button4_Status : 34|2@0+ (1,0) [0|3] "" DA,Meter
 SG_ APA_Button5_Status : 47|2@0+ (1,0) [0|3] "" DA,Meter
 SG_ APA_Button6_Status : 45|2@0+ (1,0) [0|3] "" DA,Meter
 SG_ HPA_Button1_Status : 43|2@0+ (1,0) [0|3] "" DA,Meter
 SG_ HPA_Button2_Status : 41|2@0+ (1,0) [0|3] "" DA,Meter
 SG_ APA_PrakOut_Form : 55|4@0+ (1,0) [0|15] "" DA,BLE,Meter
 SG_ APA_parkinDir_SelectStatus : 51|1@0+ (1,0) [0|1] "" DA,Meter
 SG_ APA_parkinDir_Select_Result : 50|2@0+ (1,0) [0|3] "" DA,BLE,Meter
 SG_ APA_parkoutDir_FLStatus : 63|2@0+ (1,0) [0|3] "" DA,BLE,Meter
 SG_ APA_parkoutDir_FCStatus : 61|2@0+ (1,0) [0|3] "" DA,BLE,Meter
 SG_ APA_parkoutDir_FRStatus : 59|2@0+ (1,0) [0|3] "" DA,BLE,Meter
 SG_ APA_parkoutDir_RLStatus : 57|2@0+ (1,0) [0|3] "" DA,BLE,Meter
 SG_ APA_parkoutDir_RCStatus : 71|2@0+ (1,0) [0|3] "" DA,BLE,Meter
 SG_ APA_parkoutDir_RRStatus : 69|2@0+ (1,0) [0|3] "" DA,BLE,Meter
 SG_ APA_SuggestOnOff_Status : 67|2@0+ (1,0) [0|3] "" DA,Meter
 SG_ APA_USSDispOnOff_Status : 65|2@0+ (1,0) [0|3] "" DA,Meter
 SG_ APA_SpeedSet_Status : 79|2@0+ (1,0) [0|3] "" DA,Meter
 SG_ APA_TTSOnOff_Status : 77|2@0+ (1,0) [0|3] "" DA,Meter
 SG_ RPA_OnOff_Status : 75|2@0+ (1,0) [0|3] "" BLE,DA,Meter
 SG_ HPA_OnOff_Status : 73|2@0+ (1,0) [0|3] "" DA,Meter
 SG_ HPA_SuggestOnOff_Status : 87|2@0+ (1,0) [0|3] "" DA,Meter
 SG_ HPA_SpeedSet_Status : 85|2@0+ (1,0) [0|3] "" DA,Meter
 SG_ HPA_Route1_Status : 83|1@0+ (1,0) [0|1] "" DA,Meter
 SG_ HPA_Route2_Status : 82|1@0+ (1,0) [0|1] "" DA,Meter
 SG_ HPA_Route3_Status : 81|1@0+ (1,0) [0|1] "" DA,Meter
 SG_ HPA_Route4_Status : 80|1@0+ (1,0) [0|1] "" DA,Meter
 SG_ HPA_Route5_Status : 95|1@0+ (1,0) [0|1] "" DA,Meter
 SG_ HPA_Route6_Status : 94|1@0+ (1,0) [0|1] "" DA,Meter
 SG_ HPA_Route7_Status : 93|1@0+ (1,0) [0|1] "" DA,Meter
 SG_ HPA_Route8_Status : 92|1@0+ (1,0) [0|1] "" DA,Meter
 SG_ HPA_Route9_Status : 91|1@0+ (1,0) [0|1] "" DA,Meter
 SG_ HPA_Route10_Status : 90|1@0+ (1,0) [0|1] "" DA,Meter
 SG_ HPA_Route11_Status : 89|1@0+ (1,0) [0|1] "" DA,Meter
 SG_ HPA_Route12_Status : 88|1@0+ (1,0) [0|1] "" DA,Meter
 SG_ HPA_Route13_Status : 103|1@0+ (1,0) [0|1] "" DA,Meter
 SG_ HPA_Route14_Status : 102|1@0+ (1,0) [0|1] "" DA,Meter
 SG_ HPA_Route15_Status : 101|1@0+ (1,0) [0|1] "" DA,Meter
 SG_ HPA_Route16_Status : 100|1@0+ (1,0) [0|1] "" DA,Meter
 SG_ HPA_Route17_Status : 99|1@0+ (1,0) [0|1] "" DA,Meter
 SG_ HPA_Route18_Status : 98|1@0+ (1,0) [0|1] "" DA,Meter
 SG_ HPA_Route19_Status : 97|1@0+ (1,0) [0|1] "" DA,Meter
 SG_ HPA_Route20_Status : 96|1@0+ (1,0) [0|1] "" DA,Meter
 SG_ HPA_Route_DeleteResp : 111|2@0+ (1,0) [0|3] "" DA,Meter
 SG_ APA_TextGuidance : 109|6@0+ (1,0) [0|63] "" DA,BLE,Meter
 SG_ APA_Spot_Distance : 119|7@0+ (0.1000000000000000055511151231257827021181583404541015625,0) [0|10] "m" DA,BLE,Meter
 SG_ APA_AutoSuggest_Request : 127|2@0+ (1,0) [0|3] "" DA,Meter
 SG_ APA_EnterFail_Notify : 125|5@0+ (1,0) [0|31] "" DA,Meter
 SG_ APA_Park_Pause_Notify : 151|6@0+ (1,0) [0|63] "" DA,BLE,Meter
 SG_ APA_Park_Quit_Notify : 159|6@0+ (1,0) [0|63] "" DA,BLE,Meter
 SG_ RPA_Start_Notify : 167|6@0+ (1,0) [0|63] "" BLE
 SG_ HPA_Learn_StartFail_Notify : 175|6@0+ (1,0) [0|63] "" DA,Meter
 SG_ HPA_Learn_Pause_Notify : 183|6@0+ (1,0) [0|63] "" DA,Meter
 SG_ HPA_Learn_Quit_Notify : 191|6@0+ (1,0) [0|63] "" DA,Meter
 SG_ HPA_Cuise_StartFail_Notify : 199|6@0+ (1,0) [0|63] "" DA,Meter
 SG_ HPA_Cuise_Pause_Notify : 207|6@0+ (1,0) [0|63] "" DA,Meter
 SG_ HPA_Cuise_Quit_Notify : 215|6@0+ (1,0) [0|63] "" DA,Meter
 SG_ RPA_Enter_Switch_Status : 223|2@0+ (1,0) [0|3] "" BLE
 SG_ RPA_Exit_Switch_Status : 221|2@0+ (1,0) [0|3] "" BLE
 SG_ RPA_Button1_Status : 219|2@0+ (1,0) [0|3] "" BLE
 SG_ RPA_Button2_Status : 231|3@0+ (1,0) [0|7] "" BLE
 SG_ RPA_Button3_Status : 228|2@0+ (1,0) [0|3] "" BLE
 SG_ RPA_Park_StartFail_Notify : 239|6@0+ (1,0) [0|63] "" BLE
 SG_ RPA_Park_Pause_Notify : 247|6@0+ (1,0) [0|63] "" BLE
 SG_ RPA_Park_Quit_Notify : 255|6@0+ (1,0) [0|63] "" BLE,IBCM
 SG_ RPA_ModeValid : 263|1@0+ (1,0) [0|1] "" BLE,IBCM
 SG_ RPA_BLEfeedbackReq : 262|2@0+ (1,0) [0|3] "" BLE
 SG_ RPAparkinSelectResult : 260|4@0+ (1,0) [0|15] "" BLE
 SG_ Counter_ADCU_RPA : 479|4@0+ (1,0) [0|15] "" BLE
 SG_ CRC_ADCU_RPA : 487|32@0+ (1,0) [0|4294967295] "" BLE

BO_ 1445 APA_OperationCommand: 64 DA
 SG_ APASwitchReq : 7|2@0+ (1,0) [0|3] "" ADCU
 SG_ APAButtonReq : 5|5@0+ (1,0) [0|31] "" ADCU
 SG_ APA_ParkSpot_Select : 15|8@0+ (1,0) [0|255] "" ADCU
 SG_ APA_ParkinDir_Select : 23|2@0+ (1,0) [0|3] "" ADCU
 SG_ APA_parkoutDir_Select : 21|4@0+ (1,0) [0|15] "" ADCU
 SG_ APA_Setting_Request : 31|5@0+ (1,0) [0|31] "" ADCU
 SG_ APA_PopUp_Response : 26|2@0+ (1,0) [0|3] "" ADCU
 SG_ HPA_Route_Select : 39|5@0+ (1,0) [0|31] "" ADCU
 SG_ HPA_Route_Delete : 34|1@0+ (1,0) [0|1] "" ADCU
 SG_ CFDI_ALL_SW : 471|2@0+ (1,0) [0|3] "" ADCU
 SG_ CFDI_PD_SW : 469|2@0+ (1,0) [0|3] "" ADCU
 SG_ Counter_CDC_APA : 479|4@0+ (1,0) [0|15] "" ADCU
 SG_ CRC_CDC_APA : 487|32@0+ (1,0) [0|4294967295] "" ADCU

BO_ 1393 RPA_OperationCommand: 64 BLE
 SG_ RPA_Switch_Request : 7|2@0+ (1,0) [0|3] "" ADCU
 SG_ RPA_Button_Request : 5|4@0+ (1,0) [0|15] "" ADCU
 SG_ RPA_ControlButton_Valid : 1|1@0+ (1,0) [0|1] "" ADCU
 SG_ RPA_parkoutDir_Select : 15|4@0+ (1,0) [0|15] "" ADCU
 SG_ RPA_PopUP_Response : 11|2@0+ (1,0) [0|3] "" ADCU
 SG_ RPA_BLE_Status : 9|1@0+ (1,0) [0|1] "" ADCU
 SG_ RPA_BLE_Connect_Status : 23|2@0+ (1,0) [0|3] "" ADCU
 SG_ RPA_BLE_Control_Active : 21|1@0+ (1,0) [0|1] "" ADCU
 SG_ RPA_BLE_Mode_Valid : 20|1@0+ (1,0) [0|1] "" ADCU
 SG_ RPA_BLE_Control_Request : 19|2@0+ (1,0) [0|3] "" ADCU
 SG_ Counter_BLE_RPA : 479|4@0+ (1,0) [0|15] "" ADCU
 SG_ CRC_BLE_RPA : 487|32@0+ (1,0) [0|4294967295] "" ADCU

BO_ 1228 ITS_InfoStatus_N2_1: 8 ADCU
 SG_ PEBS_INFO : 5|3@0+ (1,0) [0|7] "" ACU
 SG_ ACC_INFO : 45|3@0+ (1,0) [0|7] "" ACU
 SG_ ALIVE_CNT : 51|4@0+ (1,0) [0|15] "" ACU
 SG_ CHECKSUM : 63|8@0+ (1,0) [0|255] "" ACU

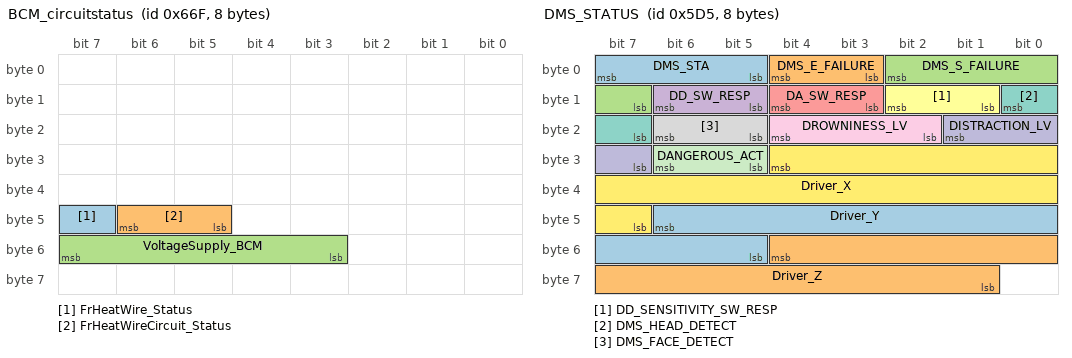
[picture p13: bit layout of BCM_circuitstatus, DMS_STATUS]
BO_ 1647 BCM_circuitstatus: 8 IBCM
 SG_ FrHeatWire_Status : 47|1@0+ (1,0) [0|1] "" ADCU
 SG_ FrHeatWireCircuit_Status : 46|2@0+ (1,0) [0|3] "" ADCU
 SG_ VoltageSupply_BCM : 55|5@0+ (1,0) [0|30] "" ADCU

BO_ 1031 GNSS_GSV: 64 PBOX
 SG_ GNSS_GSV_total_len : 7|16@0+ (1,0) [0|65535] "Bytes" ADCU
 SG_ GNSS_GSV_pack_total_num : 23|8@0+ (1,0) [0|255] "" ADCU
 SG_ GNSS_GSV_pack_id : 31|8@0+ (1,0) [0|255] "" ADCU
 SG_ GNSS_GSV_frame_len : 39|8@0+ (1,0) [0|255] "" ADCU
 SG_ GNSS_GSV_num : 47|8@0+ (1,0) [0|255] "" ADCU
 SG_ GNSS_GSV_type_1 : 55|4@0+ (1,0) [0|15] "" ADCU
 SG_ GNSS_GSV_id_1 : 51|4@0+ (1,0) [0|15] "" ADCU
 SG_ GNSS_GSV_prn_1 : 63|8@0+ (1,0) [0|255] "" ADCU
 SG_ GNSS_GSV_elv_1 : 71|8@0+ (1,0) [0|255] "deg" ADCU
 SG_ GNSS_GSV_CNR_1 : 79|8@0+ (1,0) [0|255] "dB" ADCU
 SG_ GNSS_GSV_az_1 : 87|16@0+ (1,0) [0|65535] "deg" ADCU
 SG_ GNSS_GSV_type_2 : 103|4@0+ (1,0) [0|15] "" ADCU
 SG_ GNSS_GSV_id_2 : 99|4@0+ (1,0) [0|15] "" ADCU
 SG_ GNSS_GSV_prn_2 : 111|8@0+ (1,0) [0|255] "" ADCU
 SG_ GNSS_GSV_elv_2 : 119|8@0+ (1,0) [0|255] "deg" ADCU
 SG_ GNSS_GSV_CNR_2 : 127|8@0+ (1,0) [0|255] "dB" ADCU
 SG_ GNSS_GSV_az_2 : 135|16@0+ (1,0) [0|65535] "deg" ADCU
 SG_ GNSS_GSV_type_3 : 151|4@0+ (1,0) [0|15] "" ADCU
 SG_ GNSS_GSV_id_3 : 147|4@0+ (1,0) [0|15] "" ADCU
 SG_ GNSS_GSV_prn_3 : 159|8@0+ (1,0) [0|255] "" ADCU
 SG_ GNSS_GSV_elv_3 : 167|8@0+ (1,0) [0|255] "deg" ADCU
 SG_ GNSS_GSV_CNR_3 : 175|8@0+ (1,0) [0|255] "dB" ADCU
 SG_ GNSS_GSV_az_3 : 183|16@0+ (1,0) [0|65535] "deg" ADCU
 SG_ GNSS_GSV_type_4 : 199|4@0+ (1,0) [0|15] "" ADCU
 SG_ GNSS_GSV_id_4 : 195|4@0+ (1,0) [0|15] "" ADCU
 SG_ GNSS_GSV_prn_4 : 207|8@0+ (1,0) [0|255] "" ADCU
 SG_ GNSS_GSV_elv_4 : 215|8@0+ (1,0) [0|255] "deg" ADCU
 SG_ GNSS_GSV_CNR_4 : 223|8@0+ (1,0) [0|255] "dB" ADCU
 SG_ GNSS_GSV_az_4 : 231|16@0+ (1,0) [0|65535] "deg" ADCU
 SG_ GNSS_GSV_type_5 : 247|4@0+ (1,0) [0|15] "" ADCU
 SG_ GNSS_GSV_id_5 : 243|4@0+ (1,0) [0|15] "" ADCU
 SG_ GNSS_GSV_prn_5 : 255|8@0+ (1,0) [0|255] "" ADCU
 SG_ GNSS_GSV_elv_5 : 263|8@0+ (1,0) [0|255] "deg" ADCU
 SG_ GNSS_GSV_CNR_5 : 271|8@0+ (1,0) [0|255] "dB" ADCU
 SG_ GNSS_GSV_az_5 : 279|16@0+ (1,0) [0|65535] "deg" ADCU
 SG_ GNSS_GSV_type_6 : 295|4@0+ (1,0) [0|15] "" ADCU
 SG_ GNSS_GSV_id_6 : 291|4@0+ (1,0) [0|15] "" ADCU
 SG_ GNSS_GSV_prn_6 : 303|8@0+ (1,0) [0|255] "" ADCU
 SG_ GNSS_GSV_elv_6 : 311|8@0+ (1,0) [0|255] "deg" ADCU
 SG_ GNSS_GSV_CNR_6 : 319|8@0+ (1,0) [0|255] "dB" ADCU
 SG_ GNSS_GSV_az_6 : 327|16@0+ (1,0) [0|65535] "deg" ADCU
 SG_ GNSS_GSV_type_7 : 343|4@0+ (1,0) [0|15] "" ADCU
 SG_ GNSS_GSV_id_7 : 339|4@0+ (1,0) [0|15] "" ADCU
 SG_ GNSS_GSV_prn_7 : 351|8@0+ (1,0) [0|255] "" ADCU
 SG_ GNSS_GSV_elv_7 : 359|8@0+ (1,0) [0|255] "deg" ADCU
 SG_ GNSS_GSV_CNR_7 : 367|8@0+ (1,0) [0|255] "dB" ADCU
 SG_ GNSS_GSV_az_7 : 375|16@0+ (1,0) [0|65535] "deg" ADCU
 SG_ GNSS_GSV_type_8 : 391|4@0+ (1,0) [0|15] "" ADCU
 SG_ GNSS_GSV_id_8 : 387|4@0+ (1,0) [0|15] "" ADCU
 SG_ GNSS_GSV_prn_8 : 399|8@0+ (1,0) [0|255] "" ADCU
 SG_ GNSS_GSV_elv_8 : 407|8@0+ (1,0) [0|255] "deg" ADCU
 SG_ GNSS_GSV_CNR_8 : 415|8@0+ (1,0) [0|255] "dB" ADCU
 SG_ GNSS_GSV_az_8 : 423|16@0+ (1,0) [0|65535] "deg" ADCU
 SG_ GNSS_GSV_type_9 : 439|4@0+ (1,0) [0|15] "" ADCU
 SG_ GNSS_GSV_id_9 : 435|4@0+ (1,0) [0|15] "" ADCU
 SG_ GNSS_GSV_prn_9 : 447|8@0+ (1,0) [0|255] "" ADCU
 SG_ GNSS_GSV_elv_9 : 455|8@0+ (1,0) [0|255] "deg" ADCU
 SG_ GNSS_GSV_CNR_9 : 463|8@0+ (1,0) [0|255] "dB" ADCU
 SG_ GNSS_GSV_az_9 : 471|16@0+ (1,0) [0|65535] "deg" ADCU

BO_ 1032 GNSS_SOL_RESULT: 64 ADCU
 SG_ GNSS_utc_time : 7|64@0+ (0.001000000000000000020816681711721685132943093776702880859375,0) [0|1.844674407370955E+016] "sec" CDC
 SG_ GNSS_timestamp_us : 71|64@0+ (1,0) [0|1.8446744073709552E+019] "" None
 SG_ GNSS_Seq : 135|32@0+ (1,0) [0|4294967295] "" None
 SG_ GNSS_latitude : 167|32@0+ (9.99999999999999954748111825886258685613938723690807819366455078125E-008,-90) [-90|90] "deg" None
 SG_ GNSS_longitude : 199|32@0+ (9.99999999999999954748111825886258685613938723690807819366455078125E-008,-180) [-180|180] "deg" None
 SG_ GNSS_altitude : 231|32@0+ (0.01000000000000000020816681711721685132943093776702880859375,-10000) [-10000|10000] "m" None
 SG_ GNSS_status : 263|8@0+ (1,0) [0|255] "" None
 SG_ GNSS_numSats : 271|8@0+ (1,0) [0|255] "" None
 SG_ GNSS_numSatsUsed : 279|8@0+ (1,0) [0|255] "" None
 SG_ GNSS_azi_track : 287|16@0+ (0.01000000000000000020816681711721685132943093776702880859375,-180) [0|360] "deg" None
 SG_ GNSS_position_type : 303|4@0+ (1,0) [0|15] "" None
 SG_ GNSS_hdop : 311|16@0+ (0.01000000000000000020816681711721685132943093776702880859375,-327) [-327|327] "" None
 SG_ GNSS_pdop : 327|16@0+ (0.01000000000000000020816681711721685132943093776702880859375,-327) [-327|327] "" None
 SG_ GNSS_vdop : 343|16@0+ (0.01000000000000000020816681711721685132943093776702880859375,-327) [-327|327] "" None
 SG_ GNSS_gpsSow : 359|32@0+ (1,0) [0|604800000] "ms" None
 SG_ GNSS_gpsWeek : 391|16@0+ (1,0) [0|65535] "" None
 SG_ GNSS_tSync_status : 407|8@0+ (1,0) [0|255] "" None
 SG_ GNSS_longitude_std : 415|16@0+ (0.01000000000000000020816681711721685132943093776702880859375,0) [0|655.35] "m" None
 SG_ GNSS_latitude_std : 431|16@0+ (0.01000000000000000020816681711721685132943093776702880859375,0) [0|655.35] "m" None
 SG_ GNSS_altitude_std : 447|16@0+ (0.01000000000000000020816681711721685132943093776702880859375,0) [0|655.35] "m" None
 SG_ counter : 503|8@0+ (1,0) [0|255] "" None
 SG_ checksum : 511|8@0+ (1,0) [0|255] "" None

BO_ 1033 GNSS_SOL_RESULT_2: 64 ADCU
 SG_ GNSS_utc_time : 7|64@0+ (0.001000000000000000020816681711721685132943093776702880859375,0) [0|1.844674407370955E+016] "sec" CDC
 SG_ GNSS_timestamp_us : 71|64@0+ (1,0) [0|1.8446744073709552E+019] "" None
 SG_ GNSS_Seq : 135|32@0+ (1,0) [0|4294967295] "" None
 SG_ GNSS_vel_e : 167|24@0+ (0.001000000000000000020816681711721685132943093776702880859375,-8388.6080000000001746229827404022216796875) [-8388.608|8388.607] "m_s" None
 SG_ GNSS_vel_n : 191|24@0+ (0.001000000000000000020816681711721685132943093776702880859375,-8388.6080000000001746229827404022216796875) [-8388.608|8388.607] "m_s" None
 SG_ GNSS_vel_u : 215|24@0+ (0.001000000000000000020816681711721685132943093776702880859375,-8388.6080000000001746229827404022216796875) [-8388.608|8388.607] "m_s" None
 SG_ GNSS_speed : 239|24@0+ (0.001000000000000000020816681711721685132943093776702880859375,0) [0|16777.215] "m_s" None
 SG_ GNSS_speed_std : 263|16@0+ (0.01000000000000000020816681711721685132943093776702880859375,0) [0|655.35] "" None
 SG_ GNSS_velocity_type : 279|4@0+ (1,0) [0|15] "" None
 SG_ GNSS_gpsSow : 287|32@0+ (1,0) [0|604800000] "ms" None
 SG_ GNSS_gpsWeek : 319|16@0+ (1,0) [0|65535] "" None
 SG_ counter : 503|8@0+ (1,0) [0|255] "" None
 SG_ checksum : 511|8@0+ (1,0) [0|255] "" None

BO_ 1493 DMS_STATUS: 8 ADCU
 SG_ DMS_STA : 7|3@0+ (1,0) [0|7] "" METER,DA
 SG_ DMS_E_FAILURE : 4|2@0+ (1,0) [0|3] "" METER,DA
 SG_ DMS_S_FAILURE : 2|4@0+ (1,0) [0|15] "" METER,DA
 SG_ DD_SW_RESP : 14|2@0+ (1,0) [0|3] "" DA
 SG_ DA_SW_RESP : 12|2@0+ (1,0) [0|3] "" DA
 SG_ DD_SENSITIVITY_SW_RESP : 10|2@0+ (1,0) [0|3] "" DA
 SG_ DMS_HEAD_DETECT : 8|2@0+ (1,0) [0|3] "" METER,DA
 SG_ DMS_FACE_DETECT : 22|2@0+ (1,0) [0|3] "" METER,DA
 SG_ DROWNINESS_LV : 20|3@0+ (1,0) [0|7] "" METER,DA
 SG_ DISTRACTION_LV : 17|3@0+ (1,0) [0|7] "" METER,DA
 SG_ DANGEROUS_ACT : 30|2@0+ (1,0) [0|3] "" METER,DA
 SG_ Driver_X : 28|14@0+ (1,0) [0|4850] "mm" METER
 SG_ Driver_Y : 46|10@0+ (1,0) [0|1000] "mm" METER
 SG_ Driver_Z : 52|12@0+ (1,0) [0|1680] "mm" METER

BO_ 2563508093 ADCU_Rem_Diag_Tx: 8 ADCU
 SG_ ADCU_Rem_Diag_Tx : 7|64@0+ (1,0) [0|18446744073709551615] "" Tester

BO_ 1885 ADCU_Diag_Rx: 8 Tester
 SG_ ADCU_Diag_Rx : 7|64@0+ (1,0) [0|18446744073709551615] "" ADCU

BO_ 1917 ADCU_Diag_Tx: 8 ADCU
 SG_ ADCU_Diag_Tx : 7|64@0+ (1,0) [0|18446744073709551615] "" Tester

BO_ 2564687694 Sonar_FOTA_Rx: 64 Tester
 SG_ Sonar_FOTA_Rx : 7|512@0+ (1,0) [0|3.402823669209384634633746074E+038] "" USS

BO_ 2564687726 Sonar_FOTA_Tx: 64 USS
 SG_ Sonar_FOTA_Tx : 7|512@0+ (1,0) [0|3.402823669209384634633746074E+038] "" Tester

BO_ 2563508078 Sonar_Rem_Diag_Tx: 8 USS
 SG_ Sonar_Rem_Diag_Tx : 7|64@0+ (1,0) [0|18446744073709551615] "" Tester

BO_ 1870 Sonar_Diag_Rx: 8 Tester
 SG_ Sonar_Diag_Rx : 7|64@0+ (1,0) [0|18446744073709551615] "" USS

BO_ 1902 Sonar_Diag_Tx: 8 USS
 SG_ Sonar_Diag_Tx : 7|64@0+ (1,0) [0|18446744073709551615] "" Tester

BO_ 2564687651 FR_RADAR_FOTA_Rx: 64 Tester
 SG_ FR_RADAR_FOTA_Rx : 7|512@0+ (1,0) [0|3.402823669209384634633746074E+038] "" ADCU

BO_ 2564687669 FR_RADAR_FOTA_Tx: 64 ADCU
 SG_ FR_RADAR_FOTA_Tx : 7|512@0+ (1,0) [0|3.402823669209384634633746074E+038] "" Tester

BO_ 2563508021 FR_RADAR_Rem_Diag_Tx: 8 ADCU
 SG_ FR_RADAR_Rem_Diag_Tx : 7|64@0+ (1,0) [0|18446744073709551615] "" Tester

BO_ 1827 FR_RADAR_Diag_Rx: 8 Tester
 SG_ FR_RADAR_Diag_Rx : 7|64@0+ (1,0) [0|18446744073709551615] "" ADCU

BO_ 1845 FR_RADAR_Diag_Tx: 8 ADCU
 SG_ FR_RADAR_Diag_Tx : 7|64@0+ (1,0) [0|18446744073709551615] "" Tester

BO_ 2564687677 SRR_L_FOTA_Rx: 64 Tester
 SG_ SRR_L_FOTA_Rx : 7|512@0+ (1,0) [0|3.402823669209384634633746074E+038] "" ADCU

BO_ 2564687678 SRR_L_FOTA_Tx: 64 ADCU
 SG_ SRR_L_FOTA_Tx : 7|512@0+ (1,0) [0|3.402823669209384634633746074E+038] "" Tester

BO_ 2563508030 SRR_L_Rem_Diag_Tx: 8 ADCU
 SG_ SRR_L_Rem_Diag_Tx : 7|64@0+ (1,0) [0|18446744073709551615] "" Tester

BO_ 1853 SRR_L_Diag_Rx: 8 Tester
 SG_ SRR_L_Diag_Rx : 7|64@0+ (1,0) [0|18446744073709551615] "" ADCU

BO_ 1854 SRR_L_Diag_Tx: 8 ADCU
 SG_ SRR_L_Diag_Tx : 7|64@0+ (1,0) [0|18446744073709551615] "" Tester

BO_ 2564687828 SRR_R_FOTA_Rx: 64 Tester
 SG_ SRR_R_FOTA_Rx : 7|512@0+ (1,0) [0|3.402823669209384634633746074E+038] "" ADCU

BO_ 2564687829 SRR_R_FOTA_Tx: 64 ADCU
 SG_ SRR_R_FOTA_Tx : 7|512@0+ (1,0) [0|3.402823669209384634633746074E+038] "" Tester

BO_ 2563508181 SRR_R_Rem_Diag_Tx: 8 ADCU
 SG_ SRR_R_Rem_Diag_Tx : 7|64@0+ (1,0) [0|18446744073709551615] "" Tester

BO_ 2004 SRR_R_Diag_Rx: 8 Tester
 SG_ SRR_R_Diag_Rx : 7|64@0+ (1,0) [0|18446744073709551615] "" ADCU

BO_ 2005 SRR_R_Diag_Tx: 8 ADCU
 SG_ SRR_R_Diag_Tx : 7|64@0+ (1,0) [0|18446744073709551615] "" Tester

BO_ 2564687728 PBOX_FOTA_Rx: 64 Tester
 SG_ PBOX_FOTA_Rx : 7|512@0+ (1,0) [0|3.402823669209384634633746074E+038] "" ADCU

BO_ 2564687738 PBOX_FOTA_Tx: 64 ADCU
 SG_ PBOX_FOTA_Tx : 7|512@0+ (1,0) [0|3.402823669209384634633746074E+038] "" Tester

BO_ 2563508090 PBOX_Rem_Diag_Tx: 8 ADCU
 SG_ PBOX_Rem_Diag_Tx : 7|64@0+ (1,0) [0|18446744073709551615] "" Tester

BO_ 1904 PBOX_Diag_Rx: 8 Tester
 SG_ PBOX_Diag_Rx : 7|64@0+ (1,0) [0|18446744073709551615] "" ADCU

BO_ 1914 PBOX_Diag_Tx: 8 ADCU
 SG_ PBOX_Diag_Tx : 7|64@0+ (1,0) [0|18446744073709551615] "" Tester

CM_ SG_ 1258 ADControl_enable "None";
CM_ SG_ 1258 LeftTurnLampControlReq "None";
CM_ SG_ 1258 RightTurnLampControlReq "None";
CM_ SG_ 1258 HazardWarningLampReq "None";
CM_ SG_ 1258 BeamControlReq "None";
CM_ SG_ 1258 AD_Ext_Rear_Mirror_Folding_Req "None";
CM_ SG_ 1258 FrWipReq "None";
CM_ SG_ 1258 Heat_request "None";
CM_ SG_ 1258 BSWLamp_L_Request "None";
CM_ SG_ 1258 BSWLamp_R_Request "None";
CM_ SG_ 1258 ADCU_RefuseToSleep "None";
CM_ SG_ 1258 ADLowPwrSts "None";
CM_ SG_ 1258 RdytoLoPwr "None";
CM_ SG_ 1293 BAT_RQ "None";
CM_ SG_ 861 GADE "None";
CM_ SG_ 861 BCM_WakeUpSleepCmd "None";
CM_ SG_ 861 PwrSavModeMask "None";
CM_ SG_ 861 CABRESW "None";
CM_ SG_ 861 Rv_La_Con_St "None";
CM_ SG_ 861 FR_WIP_REQ "None";
CM_ SG_ 536 PEPS_POWER_MODE "None";
CM_ SG_ 1549 DOOR_SW "None";
CM_ SG_ 1549 TURN_IND "None";
CM_ SG_ 1549 IGN_SW "None";
CM_ SG_ 1549 ACC_SW "None";
CM_ SG_ 1549 DOOR_LOCK "None";
CM_ SG_ 1549 RR_FOG_L "None";
CM_ SG_ 1549 ADLowPwrReq "None";
CM_ SG_ 1573 HL_LOW "None";
CM_ SG_ 1573 HL_HIGH "None";
CM_ SG_ 1573 TAIL_L "None";
CM_ SG_ 1573 VehicleState "None";
CM_ SG_ 1573 Hood_SW "None";
CM_ SG_ 1532 HighLampChangeSWSts "None";
CM_ SG_ 1532 TurnLampSWSts "None";
CM_ SG_ 1480 SW_PILOTorCANCEL "None";
CM_ SG_ 1480 SW_DISTANCEorASCD "None";
CM_ SG_ 1480 SW_DistanceReduce "None";
CM_ SG_ 1480 SW_SET "None";
CM_ SG_ 1480 SW_RES "None";
CM_ SG_ 1480 SW_CUSTOM "None";
CM_ SG_ 1480 SW_LEFT "None";
CM_ SG_ 1480 SW_RIGHT "None";
CM_ SG_ 1480 SW_OK "None";
CM_ SG_ 1480 DrvrSeatOccupSts "None";
CM_ SG_ 901 LTP_FR "None";
CM_ SG_ 901 LTP_FL "None";
CM_ SG_ 901 LTP_RR "None";
CM_ SG_ 901 LTP_RL "None";
CM_ SG_ 901 TPD_FR "None";
CM_ SG_ 901 TPD_FL "None";
CM_ SG_ 901 TPD_RR "None";
CM_ SG_ 901 TPD_RL "None";
CM_ SG_ 858 DR_Win_St "None";
CM_ SG_ 858 AS_Win_St "None";
CM_ SG_ 858 RL_Win_St "None";
CM_ SG_ 858 RR_Win_St "None";
CM_ SG_ 1338 FrWipSts "None";
CM_ SG_ 1338 LowBatVFb "None";
CM_ SG_ 1339 LeftBswLedSts "None";
CM_ SG_ 1339 RightBswLedSts "None";
CM_ SG_ 1340 PassSeatOccupSts "None";
CM_ SG_ 1340 ExtRMirFldSts "None";
CM_ SG_ 1342 BcmRainSizeSts "None";
CM_ SG_ 1343 AirConditionSystemWorking_Status "None";
CM_ SG_ 1343 BlwModeSts "None";
CM_ SG_ 1343 OutsideTempAD "None";
CM_ SG_ 1351 Ambient_Temp_Value "None";
CM_ SG_ 1351 Inner_Temp_Value "None";
CM_ SG_ 793 SDM_CheckSum "None";
CM_ SG_ 793 SDM_AliveCounter "None";
CM_ SG_ 793 SDM_SecuBltAlrmSts_RL "None";
CM_ SG_ 793 SDM_SecuBltAlrmSts_RM "None";
CM_ SG_ 793 SDM_SecuBltAlrmSts_RR "None";
CM_ SG_ 793 SDM_DrverSecuBltAlrmSts "None";
CM_ SG_ 793 SDM_PassSecuBltAlrmSts "None";
CM_ SG_ 793 SDM_AirBagSysAlrmLampSts "None";
CM_ SG_ 793 SDM_CllsnSig "None";
CM_ SG_ 793 SDM_FrntCllsn "None";
CM_ SG_ 793 SDM_LeSideCllsn "None";
CM_ SG_ 793 SDM_RiSideCllsn "None";
CM_ SG_ 793 SDM_ReCllsn "None";
CM_ SG_ 793 SDM_Rollover "None";
CM_ SG_ 578 CheckSum_242 "None";
CM_ SG_ 578 AliveCounter_242 "None";
CM_ SG_ 578 YRS_LatSnsrSts "None";
CM_ SG_ 578 YRS_YawRateSnsrSts "None";
CM_ SG_ 578 YRS_YawRateCalSts "None";
CM_ SG_ 578 YRS_LatAcce "None";
CM_ SG_ 578 YRS_YawRate "None";
CM_ SG_ 582 YRS_246_CheckSum "None";
CM_ SG_ 582 YRS_246_AliveCounter "None";
CM_ SG_ 582 YRS_LgtSnsrSts "None";
CM_ SG_ 582 YRS_LgtAcce "None";
CM_ SG_ 582 YRS_VertAcce "None";
CM_ SG_ 582 YRS_VertSnsrSts "None";
CM_ SG_ 582 YRS_RollrateSnsrSts "None";
CM_ SG_ 582 YRS_RollrateSigVl "None";
CM_ SG_ 1383 Year "None";
CM_ SG_ 1383 Month "None";
CM_ SG_ 1383 Day "None";
CM_ SG_ 1383 Hour "None";
CM_ SG_ 1383 Minute "None";
CM_ SG_ 1383 Second "None";
CM_ SG_ 1383 Server_time_flag "None";
CM_ SG_ 1383 GPS_Signal "None";
CM_ SG_ 1477 DIS_TOTAL "None";
CM_ SG_ 581 VDCFAIL "None";
CM_ SG_ 581 OFF_SW "None";
CM_ SG_ 581 MSGCNTRR1 "None";
CM_ SG_ 682 SIGNAL_SOURCING "None";
CM_ SG_ 682 AEB_STATUS "None";
CM_ SG_ 682 AEB_ALIVE "None";
CM_ SG_ 682 EAPM_ENBL "None";
CM_ SG_ 682 EAPM_Status "None";
CM_ SG_ 682 EAPM_Alive "None";
CM_ SG_ 682 MSG_CNT "None";
CM_ SG_ 682 CHKSUM "None";
CM_ SG_ 682 VehicleStandstill "None";
CM_ SG_ 852 MSGCNTR "None";
CM_ SG_ 852 STPLMSW "None";
CM_ SG_ 576 EPB_STAT "None";
CM_ SG_ 576 EPB_FAIL "None";
CM_ SG_ 576 DPB_STAT "None";
CM_ SG_ 576 ALIVECOUNTER "None";
CM_ SG_ 576 CHESUM "None";
CM_ SG_ 658 PSS_02 "None";
CM_ SG_ 658 CHCKSUM "None";
CM_ SG_ 658 MVP_COUNT "None";
CM_ SG_ 644 WRFR "None";
CM_ SG_ 644 WRFL "None";
CM_ SG_ 644 VSO "None";
CM_ SG_ 644 MSGCOUNT "None";
CM_ SG_ 644 CHKSUMFR "None";
CM_ SG_ 645 WRRR "None";
CM_ SG_ 645 WRRL "None";
CM_ SG_ 645 VCVT "None";
CM_ SG_ 645 WDFL "None";
CM_ SG_ 645 WDFR "None";
CM_ SG_ 645 WDRL "None";
CM_ SG_ 645 WDRR "None";
CM_ SG_ 645 MSGCOUNT "None";
CM_ SG_ 645 CHKSUMFR "None";
CM_ SG_ 646 WSPRR "None";
CM_ SG_ 646 WSPRL "None";
CM_ SG_ 646 MSGCOUNT "None";
CM_ SG_ 646 WTFL "None";
CM_ SG_ 646 WTFR "None";
CM_ SG_ 646 WTRL "None";
CM_ SG_ 646 WTRR "None";
CM_ SG_ 2 STRANGLE "None";
CM_ SG_ 2 STRSPEED "None";
CM_ SG_ 2 LWSTRIM "None";
CM_ SG_ 2 LWSCAL "None";
CM_ SG_ 2 LWSOK "None";
CM_ SG_ 2 CHCKSUM "None";
CM_ SG_ 2 MSGCOUNT "None";
CM_ SG_ 500 PT_MotoSpd "None";
CM_ SG_ 500 PT_MotoSpdV "None";
CM_ SG_ 502 PT_AccelPadelPos "None";
CM_ SG_ 502 PT_AccelPadelPosV "None";
CM_ SG_ 502 IND_RNG "None";
CM_ SG_ 384 P_RUN "None";
CM_ SG_ 384 ETCFAIL "None";
CM_ SG_ 1361 ENG_STA "None";
CM_ SG_ 1449 DTE_VCM "None";
CM_ SG_ 689 AD_take_over_request "AD 接管请求";
CM_ SG_ 689 HodMeterLampRequest "DA屏闪请求";
CM_ SG_ 689 ISLS_Limit_Speed_Value "ISLS限速值";
CM_ SG_ 689 SLIF_Limit_Speed_Validation "SLIF限速有效性";
CM_ SG_ 689 SLIF_Limit_Speed_Unit "SLIF限速单位";
CM_ SG_ 689 ISLS_Acoustic_Warning "ISLS限速报警";
CM_ SG_ 689 Hand_Off_Status "脱手报警信号";
CM_ SG_ 689 AVM_Front_Cam_Video_State "AVM前摄像头视频流状态：
0b00=无视频流输出
0b01=视频流正常输出（有视频流输出，且帧率正常）
0b10=视频流异常输出（有视频流，但帧率异常）
0b11=留用";
CM_ SG_ 689 AVM_Rear_Cam_Video_State "AVM后摄像头视频流状态：
0b00=无视频流输出
0b01=视频流正常输出（有视频流输出，且帧率正常）
0b10=视频流异常输出（有视频流，但帧率异常）
0b11=留用";
CM_ SG_ 689 AVM_Left_Cam_Video_State "AVM左摄像头视频流状态：
0b00=无视频流输出
0b01=视频流正常输出（有视频流输出，且帧率正常）
0b10=视频流异常输出（有视频流，但帧率异常）
0b11=留用";
CM_ SG_ 689 AVM_Right_Cam_Video_State "AVM右摄像头视频流状态：
0b00=无视频流输出
0b01=视频流正常输出（有视频流输出，且帧率正常）
0b10=视频流异常输出（有视频流，但帧率异常）
0b11=留用";
CM_ SG_ 689 ALIVE_CNT "None";
CM_ SG_ 689 CHECKSUM "None";
CM_ SG_ 695 PCW_PreWarning "None";
CM_ SG_ 695 AEB_Active "AEB介入";
CM_ SG_ 695 CDW_Active "CDW 激活";
CM_ SG_ 695 ESS_Active "ESS 激活";
CM_ SG_ 695 fcta_left_warning "FCTA 左侧横穿目标报警";
CM_ SG_ 695 fcta_front_warning "FCTA 前方横穿目标报警";
CM_ SG_ 695 fcta_right_warning "FCTA 右侧横穿目标报警";
CM_ SG_ 695 fctb_left_warning "FCTB 左侧横穿目标报警";
CM_ SG_ 695 fctb_front_warning "FCTB 前方横穿目标报警";
CM_ SG_ 695 fctb_right_warning "FCTB 右侧横穿目标报警";
CM_ SG_ 695 rctb_left_warning "RCTB 左侧横穿目标报警";
CM_ SG_ 695 rctb_rear_warning "RCTB 前方横穿目标报警";
CM_ SG_ 695 rctb_right_warning "RCTB 右侧横穿目标报警";
CM_ SG_ 695 ELK_active "ELK 激活";
CM_ SG_ 695 rcta_left_warning "RCTA 左侧横穿目标报警";
CM_ SG_ 695 rcta_rear_warning "RCTA 前方横穿目标报警";
CM_ SG_ 695 rcta_right_warning "RCTA 右侧横穿目标报警";
CM_ SG_ 695 rcw_warning "RCW 激活";
CM_ SG_ 695 left_bsw_warning "左侧BSW 激活";
CM_ SG_ 695 right_bsw_warning "右侧BSW激活";
CM_ SG_ 695 left_dow_warning "左侧DOW报警";
CM_ SG_ 695 right_dow_warning "右侧DOW报警";
CM_ SG_ 695 LDW_Warning "LDW 报警";
CM_ SG_ 695 LDP_Active "LDP报警";
CM_ SG_ 695 STS_D_MEB "None";
CM_ SG_ 695 SET_MEB "None";
CM_ SG_ 695 STS_W_MEB "None";
CM_ SG_ 695 SOUND_MEB "None";
CM_ SG_ 695 ALIVE_CNT "None";
CM_ SG_ 695 CHECKSUM "None";
CM_ SG_ 1260 ACC_HEADW_SET "ACC时距";
CM_ SG_ 1260 VDC_NOT_ACTIVATED "AEBS专用显示icon的VDC信号,
VDC是否关闭，如果关闭，需要一直发送";
CM_ SG_ 1260 ACC_DrSeSp "ACC SETSPEED";
CM_ SG_ 1260 ACC_DisToTgt "ACC目标距离";
CM_ SG_ 1260 ACC_TgtDet "ACC目标检测";
CM_ SG_ 1260 ACC_GoNoti "ACC起步提醒";
CM_ SG_ 1260 CP_Status "CP状态";
CM_ SG_ 1260 MSG_ILC_Opera "ILC介入弹窗报警
（0x0：功能不作动；0x1：表示车辆向左偏（大车在右侧）；0x2：表示车辆向右偏（大车在左侧））";
CM_ SG_ 1260 CP_PLC_Status "CP拨杆变道状态";
CM_ SG_ 1260 CP_PLC_Direction "CP变道方向";
CM_ SG_ 1260 Message_AD_unActive_Reason "AD 无法激活原因";
CM_ SG_ 1260 ACC_Status "ACC的状态";
CM_ SG_ 1260 AD_Notice_Information "AD 提示信息";
CM_ SG_ 1260 ISLC_Comfirm_Request "限速辅助提醒";
CM_ SG_ 1260 STATUS_CHANGE_ALERT "CP 降级ACC 提醒";
CM_ SG_ 1260 HnpLastDistance "HNP 距离提示";
CM_ SG_ 1260 AD_ICON "AD ICON显示图标";
CM_ SG_ 1260 HNP_Status "HNP 状态机";
CM_ SG_ 1260 HNP_Lane_Change_Status "HNP变道状态";
CM_ SG_ 1260 Message_AD_Error "AD 故障位（包含信号异常，ADCU异常，执行异常）";
CM_ SG_ 1260 Message_Inclement_weather "恶劣天气报警";
CM_ SG_ 1260 Message_FR_Camera_block "前摄像头遮挡报警";
CM_ SG_ 1260 Message_FR_Radar_block "前雷达遮挡报警";
CM_ SG_ 1260 Msg_Side_Fisheye_Camera_block "侧鱼眼摄像头遮挡报警";
CM_ SG_ 1260 Message_Rear_Camera_block "后视摄像头遮挡报警";
CM_ SG_ 1260 Message_Side_Rear_Radar_block "后角雷达遮挡报警";
CM_ SG_ 1260 SETTING_LDW_LDP_Status "LDW开关状态回馈";
CM_ SG_ 1260 LDW__INFO "LDW状态";
CM_ SG_ 1260 SET_LDW_SENS_Status "LDW敏感度反馈";
CM_ SG_ 1260 AEBS_INFO "AEBS状态";
CM_ SG_ 1260 SET_FCW_SENS_Status "FCW 灵敏度反馈";
CM_ SG_ 1260 SETTING_AEBS_Status "AEBS 开关";
CM_ SG_ 1260 LDP_INFO "LDP状态";
CM_ SG_ 1260 SETTING_ELK_Status "ELK开关状态回馈";
CM_ SG_ 1260 ELK_INFO "ELK_状态";
CM_ SG_ 1260 SETTING_ESS_Status "ESS 开关反馈";
CM_ SG_ 1260 ESS_INFO "ESS 状态";
CM_ SG_ 1260 SET_PILOT_STA "PILOT 模式状态反馈";
CM_ SG_ 1260 SET_ILC_STA "ILC开关状态反馈";
CM_ SG_ 1260 SET_IHC_STA "IHC开关状态反馈";
CM_ SG_ 1260 SET_PLC_STA "拨杆变道开关状态";
CM_ SG_ 1260 ISLS_INFO "SLIF 状态";
CM_ SG_ 1260 SET_TSR_status "TSR开关状态回馈";
CM_ SG_ 1260 TSR_INFO "TSR状态";
CM_ SG_ 1260 SET_TLA_status "TLA开关状态回馈";
CM_ SG_ 1260 SET_TLAS_status "TLA控车开关状态回馈";
CM_ SG_ 1260 TLA__INFO "TLA状态";
CM_ SG_ 1260 SET_RCTA_RCTB_status "RCTA 开关状态";
CM_ SG_ 1260 RCTA_INFO "RCTA 状态";
CM_ SG_ 1260 RCTB_INFO "None";
CM_ SG_ 1260 SET_FCTA_FCTB_status "FCTA,FCTB开关状态响应";
CM_ SG_ 1260 FCTA_INFO "None";
CM_ SG_ 1260 FCTB_INFO "None";
CM_ SG_ 1260 SET_BSW_status "None";
CM_ SG_ 1260 BSW_INFO "None";
CM_ SG_ 1260 SET_DOW_status "None";
CM_ SG_ 1260 DOW_INFO "None";
CM_ SG_ 1260 SET_RCW_status "None";
CM_ SG_ 1260 RCW_INFO "None";
CM_ SG_ 1260 SET_VOL_STA "HNP 语音播报开关";
CM_ SG_ 1260 SET_CDW_SENS_Status "CDW 灵敏度开关状态反馈";
CM_ SG_ 1260 SET_ISLC_OFT_STA "驾驶员设定车速偏置值";
CM_ SG_ 1260 SETTING_CDW_Status "None";
CM_ SG_ 1260 MSG_FR_Camera_H_Temp "前摄像头过热";
CM_ SG_ 1260 MSG_RR_Camera_H_Temp "后摄像头过热";
CM_ SG_ 1260 MSG_ADCU_H_Temp "ADCU过热";
CM_ SG_ 1260 MSG_fisheye_Camera_H_Temp "鱼眼摄像头过热";
CM_ SG_ 1260 MSG_VDC_NO_Actived "故障文言使用，VDC关闭，发Ns（与其他弹窗时间保持一致）";
CM_ SG_ 1260 SET_ISLS_STA "ISLS开关状态反馈";
CM_ SG_ 1260 SALC_INFO "拨杆变道状态机信号（ICON用）";
CM_ SG_ 1260 HNPDowngradeStatus "ADCU通知CDC，当前是否可以从HNP降级为CP";
CM_ SG_ 1260 CPUpgradeStatus "ADCU通知CDC，当前是否可以从CP升级为HNP";
CM_ SG_ 1260 HNPLaneChangeStyleStatus "变道模式状态";
CM_ SG_ 1260 HNPLanePreferenceStatus "偏好车道设置状态";
CM_ SG_ 1260 TSR_DISP "None";
CM_ SG_ 1260 TLA_Pattern "TLA信号灯类型显示";
CM_ SG_ 1260 Left_Uturn_Indication "TLA掉头信号灯状态显示";
CM_ SG_ 1260 Turn_Left_Indication "TLA左转信号灯状态显示";
CM_ SG_ 1260 Go_Stright_Indication "TLA直行信号灯状态显示";
CM_ SG_ 1260 Trun_Right_Indication "TLA右转信号灯状态显示";
CM_ SG_ 1260 TLA_Number "TLA信号灯数量";
CM_ SG_ 1260 ALC_Confirm "HNP变道确认开关";
CM_ SG_ 1260 DVR_InfoStatus "None";
CM_ SG_ 1260 MESSAGE_DVR_WARN "None";
CM_ SG_ 1260 CDW_INFO "CDW状态机信号";
CM_ SG_ 1260 AD_Safety_Event "CDW状态机信号";
CM_ SG_ 1260 CFDI_ALL_Sts "None";
CM_ SG_ 1260 CFDI_DeletePDDATA_Sts "None";
CM_ SG_ 1260 AliveCounter "None";
CM_ SG_ 1260 CHECKSUM "None";
CM_ SG_ 640 STAT_CHG_REQ2 "None";
CM_ SG_ 640 BAC_SW "None";
CM_ SG_ 640 AD_signalback "None";
CM_ SG_ 640 ISLC_OFT_STA "驾驶员设定车速偏置值";
CM_ SG_ 853 VS_DISP "None";
CM_ SG_ 853 Disp_Unit "None";
CM_ SG_ 853 STAT_CHG_REQ1 "None";
CM_ SG_ 1402 REQ_DISP_MET "None";
CM_ SG_ 1402 REQ_DISP_CEN "None";
CM_ SG_ 1402 SONAR_S_REQ "None";
CM_ SG_ 1402 STS_SETTING "None";
CM_ SG_ 1402 RR_CEN "None";
CM_ SG_ 1402 A_RR_CEN "None";
CM_ SG_ 1402 FR_CEN "None";
CM_ SG_ 1402 A_FR_CEN "None";
CM_ SG_ 1402 RR_L "None";
CM_ SG_ 1402 A_RR_L "None";
CM_ SG_ 1402 RR_R "None";
CM_ SG_ 1402 A_RR_R "None";
CM_ SG_ 1402 FR_L "None";
CM_ SG_ 1402 A_FR_L "None";
CM_ SG_ 1402 FR_R "None";
CM_ SG_ 1402 A_FR_R "None";
CM_ SG_ 1402 STS_DISTANCE "None";
CM_ SG_ 1402 STS_AUTO_DISP "None";
CM_ SG_ 1402 STS_SYS_MODE "None";
CM_ SG_ 1402 SOUND_ZONE "None";
CM_ SG_ 1402 SOUND_CONT "None";
CM_ SG_ 1402 SOUND_LEVEL "None";
CM_ SG_ 1402 SONAR_Detect_Distance_F "None";
CM_ SG_ 1402 RangeStatus_RR_Right_side "None";
CM_ SG_ 1402 Availavility_RR_CornerRight_side "None";
CM_ SG_ 1402 RangeStatus_RR_left_side "None";
CM_ SG_ 1402 Availavility_RR_Cornerleft_side "None";
CM_ SG_ 1402 RangeStatus_FR_Right_side "None";
CM_ SG_ 1402 Availavility_FR_CornerRight_side "None";
CM_ SG_ 1402 RangeStatus_FR_Left_side "None";
CM_ SG_ 1402 Availavility_FR_CornerLeft_side "None";
CM_ SG_ 1402 SoundObstacleZone_Request "None";
CM_ SG_ 1403 STS_D_EAP "None";
CM_ SG_ 1403 SET_EAPM "None";
CM_ SG_ 1403 STS_W_EAP "None";
CM_ SG_ 1403 SOUND_EAPM "None";
CM_ SG_ 1405 APA_Function_Status "APA功能状态：
000b = Passive 泊车初始化状态
001b = Standby 泊车等待状态
010b = Searching in/out 泊入模式车位搜索/泊出模式泊出方向搜索状态
011b = Parking in/out 自动驾驶状态，泊车中
100b = Paused 泊车暂停状态
101b = Failure 泊车失败&故障状态
110b = Complete 泊车完成状态
111b = Reserve 保留";
CM_ SG_ 1405 APA_Park_Mode "APA模式:泊入/泊出区分/遥控直行";
CM_ SG_ 1405 APA_Control_Mode "APA遥控还是非遥控区分";
CM_ SG_ 1405 APA_Page_Type "页面种类：SR不同的显示视角";
CM_ SG_ 1405 HPA_Function_Status "HPA功能状态：不可用/可用/寻库中/学习中/巡航中/最小风险失效状态";
CM_ SG_ 1405 APA_Enter_Switch_Status "SR等界面“切到泊车”按钮状态：
00b=Hidden 隐藏（默认）
01b=Available 显示可点
10b=HightLight 高亮可点
11b=Invalid 无效值";
CM_ SG_ 1405 APA_Exit_Switch_Status "“切回行车”按钮可用性：
00b=Hidden 隐藏（默认）
01b=Unavailable 置灰不可点
10b=Available 显示可点
11b=Invalid 无效值";
CM_ SG_ 1405 APA_Button0_Status "（遥控泊入）返回车上泊入按键状态：
00b=Hiden 隐藏（默认）
01b=Unavailable 置灰不可点
10b=Available 显示可点
11b=Invalid 无效值";
CM_ SG_ 1405 APA_Button1_Status "开始自动（泊车/巡航）按键状态：
00b=Hiden 隐藏（默认）
01b=Unavailable 置灰不可点
10b=Available 显示可点
11b=Invalid 无效值";
CM_ SG_ 1405 APA_Button2_Status "暂停或恢复自动（泊车/巡航）按键状态：
000b=No display (hidden) 不显示（隐藏）
001b=Pause Available 暂停按键显示
010b=Pause Unavailable 暂停按键不显示
011b=Resume available 恢复泊车按键显示
100b=Resume unavailable 恢复泊车按键不显示
101b=Reserve 保留
110b=Reserve 保留
111b=Invalid 无效值";
CM_ SG_ 1405 APA_Button3_Status "（暂停后触发的）退出自动（泊车/巡航)按键状态：
00b=Hiden 隐藏（默认）
01b=Unavailable 置灰不可点
10b=Available 高亮显示可点
11b=Invalid 无效值";
CM_ SG_ 1405 APA_Button4_Status "（车机）遥控泊入按键状态：隐藏/不可用(置灰不可点)/可用（可点）/无效值
00b=Hiden 隐藏（默认）
01b=Unavailable 置灰不可点
10b=Available 显示可点
11b=Invalid 无效值";
CM_ SG_ 1405 APA_Button5_Status "用于自定义车位入口（TBD）：
00b=Hiden 隐藏（默认）
01b=Unavailable 置灰不可点
10b=Available 显示可点
11b=Invalid 无效值";
CM_ SG_ 1405 APA_Button6_Status "设置按钮按键状态：
00b=Hiden 隐藏（默认）
01b=Unavailable 置灰不可点
10b=Available 显示可点
11b=Invalid 无效值";
CM_ SG_ 1405 APA_PrakOut_Form "泊出方式：水平泊出还是垂直泊出";
CM_ SG_ 1405 APA_parkinDir_SelectStatus "泊入方向可用性（用户选中车位后才显示）：默认不可切换/可以切换";
CM_ SG_ 1405 APA_parkinDir_Select_Result "泊入方向选择结果：默认值/车头泊入/车尾泊入/保留";
CM_ SG_ 1405 APA_parkoutDir_FLStatus "泊出方向可用性(前左)：
00b=Hidden 隐藏（默认）
01b=Available 显示可点（未选中）
10b=HightLight 高亮可点（选中）
11b=Invalid 无效值";
CM_ SG_ 1405 APA_parkoutDir_FCStatus "泊出方向可用性(前中)：
00b=Hidden 隐藏（默认）
01b=Available 显示可点（未选中）
10b=HightLight 高亮可点（选中）
11b=Invalid 无效值";
CM_ SG_ 1405 APA_parkoutDir_FRStatus "泊出方向可用性(前右)：
00b=Hidden 隐藏（默认）
01b=Available 显示可点（未选中）
10b=HightLight 高亮可点（选中）
11b=Invalid 无效值";
CM_ SG_ 1405 APA_parkoutDir_RLStatus "泊出方向可用性(后左)：
00b=Hidden 隐藏（默认）
01b=Available 显示可点（未选中）
10b=HightLight 高亮可点（选中）
11b=Invalid 无效值";
CM_ SG_ 1405 APA_parkoutDir_RCStatus "泊出方向可用性(后中)：
00b=Hidden 隐藏（默认）
01b=Available 显示可点（未选中）
10b=HightLight 高亮可点（选中）
11b=Invalid 无效值";
CM_ SG_ 1405 APA_parkoutDir_RRStatus "泊出方向可用性(后右)：
00b=Hidden 隐藏（默认）
01b=Available 显示可点（未选中）
10b=HightLight 高亮可点（选中）
11b=Invalid 无效值";
CM_ SG_ 1405 APA_SuggestOnOff_Status "自动推荐功能开关设置状态：默认值/推荐/不推荐/保留";
CM_ SG_ 1405 APA_USSDispOnOff_Status "雷达墙显示功能开关设置状态：默认值/打开/关闭/保留";
CM_ SG_ 1405 APA_SpeedSet_Status "泊车/巡航的速度慢/中/快 设置状态：默认值/慢/中/快";
CM_ SG_ 1405 APA_TTSOnOff_Status "TTS播报开/关 设置状态：默认值/打开/关闭/保留";
CM_ SG_ 1405 RPA_OnOff_Status "RPA 功能ON/OFF状态";
CM_ SG_ 1405 APA_TextGuidance "文言提示内容：
000000b=无请求
000001b=APA刚进入泊入模式，提示 请前行搜索车位
000010b=APA找到车位（有效车位），但车辆不静止，提示 搜索到车位，请停车
000011b=APA搜索车位时速度太高（D档时大于25km/h）,提示速度过高，请减速
000100b=APA搜索车位时速度太高（R档时大于5km/h）,提示速度过高，请减速
000101b=APA找到车位（有效车位），且车辆静止，提示 请选择泊入方式
000110b=APA/RPA已处于泊入或者泊出模式，且车辆自动D档前进，提示 继续前行xxx 米
000111b=RPA已处于遥控直入或遥控直出模式，且车辆受控，提示 可直行xxx 米
001000b=APA泊车过程中，刹车被踩下，提示请松开刹车
001001b=APA泊车过程中暂停按钮被按下，提示泊车暂停
001010b=APA泊车失败，与notify弹窗同频显示，暂时保留
001011b=APA泊车结束，与notify弹窗同频显示，暂时保留
001100b=APA刚进入泊出模式，提示可选择泊出方向
001101b=APA/RPA已处于泊入或者泊出模式，且车辆自动R档前进，提示继续后退xxx 米
101111b=请挂P档（RPA）
110000b=请下车用手机进行泊入（RPA）
110001b=遥控泊车中（RPA）
110010b=请长按方向键开始直行(RPA)
110011b=请点击继续按钮恢复泊车
110100b=主驾车门开启
110101b=非主驾车门开启
110110b=前舱盖打开
110111b=后背厢打开
111000b=外后视镜折叠
111001b=充电枪未断开
111010b=蓝牙未连接
111011b=请挂D/R挡上Ready";
CM_ SG_ 1405 APA_Spot_Distance "规划轨迹单步剩余距离";
CM_ SG_ 1405 APA_AutoSuggest_Request "行车界面显示我要泊车按键：
00b=默认，不请求
01b=按钮置蓝（满足车速条件，且找到可泊车位/ 满足记忆泊车巡航条件/满足记忆泊车学习条件）
10b=按键置灰(满足车速条件，但找到可泊车位/ 满足记忆泊车巡航条件/满足记忆泊车学习条件)
11b=按键隐藏（超车速条件）";
CM_ SG_ 1405 APA_EnterFail_Notify "APA应用无法进入时的提示：
00000b=无故障
00001b=前广角摄像头故障
00010b=AVM 前摄像头故障
00011b=AVM 左摄像头故障
00100b=AVM 右摄像头故障
00101b=AVM 后摄像头故障
00110b=超声波雷达控制器故障
00111b=前 超声波雷达故障
01000b=侧边 超声波雷达故障
01001b=后 超声波雷达故障
01010b=ADCU 软件系统故障
01011b=ADCU 硬件系统故障
01100b=IBC故障
01101b=VCM故障
01110b=EPS故障
01111b=P-box故障
10000b=ABS故障
10001b=ESC故障
10010b=速度过高，提示速度过高，禁止使用泊车功能
10011b=遥控泊车进行中，提示遥控泊车进行中，请勿操作
10100b=整车开启超级省电模式，无法进入
10101b=电源状态不正确（如ACC）无法激活";
CM_ SG_ 1405 APA_Park_Pause_Notify "泊车暂停弹窗提示：
000000b = No Request // 无请求
000001b = DRIVER_DOOR_OPEN // 驾驶员车门打开
000010b = SEATBELT_OPEN // 安全带未系
000011b = DETECTION_NOT_DRIVER // 检测到非驾驶员
000100b = PASSENGER_DOOR_OPEN // 乘客车门打开
000101b = FRONT_HOOD_OPEN // 前引擎盖打开
000110b = BACK_TRUNK_OPEN // 后备箱打开
000111b = REARVIEW_MIRROR_FOLDER // 后视镜折叠
001000b = BLUETOOTH_CONNECTION_FAIL // 蓝牙连接失败
001001b = OBSTACLE_ONPATH // 路径上有障碍物";
CM_ SG_ 1405 APA_Park_Quit_Notify "APA退出原因报文：RPA_Park_Quit_Notify
000000b=No Request // 初始值
000001b=CHARGING_GUN_CONNECT // 提示请拔下充电枪 000010b=TIER_PRESSURE_FAILURE // 提示轮胎压力报警 000011b=RAIN_SENSOR_FAILURE // 提示雨刷传感器故障 000100b=BLUETOOTH_CONNECTION_FAIL // 提示蓝牙连接失败 000101b=FRONT_AVM_FAILURE // 提示AVM前方故障
000110b=REAR_AVM_FAILURE // 提示AVM后方故障
000111b=LEFT_AVM_FAILURE // 提示AVM左侧故障
001000b=RIGHT_AVM_FAILURE // 提示AVM右侧故障 001001b=SONAR_CONT_FAILURE // 提示超声波雷达控制器故障 001010b=FRONT_SONAR_FAILURE // 提示前方超声波雷达故障 001011b=SIDE_SONAR_FAILURE // 提示侧方超声波雷达故障 001100b=REAR_SONAR_FAILURE // 提示后方超声波雷达故障 001101b=ADCU_SW_FAILURE // 提示ADCU软件系统故障 001110b=ADCU_HW_FAILURE // 提示ADCU硬件系统故障
001111b=VCM_FAILURE // 提示VCM故障
010000b=IBC_FAILURE // 提示IBC故障
010001b=EPS_FAILURE // 提示EPS故障
010010b=IMU_FAILURE // 提示IMU故障
010011b=ABS_FAILURE // 提示ABS故障
010100b=ESC_FAILURE // 提示ESC故障
010101b=BLE_FAILURE // 提示蓝牙故障
010110b=ABS_ACTIVE // 显示ABS被激活
010111b=ESC_ACTIVE // 显示ESC被激活
011000b=OTHER_AD_ACTIVE // 显示其它AD功能被激活
011001b=MEB_ACTIVE // 提示MEB被激活
011010b=AEB_ACTIVE // 提示AEB被激活
011011b=RCTB_ACTIVE // 提示RCTB被激活
011100b=FCTB_ACTIVE // 提示FCTB被激活
011101b=ACU_ACTIVE // 提示ACU被激活
011110b=ODD_NOT_SATISFIED // 提示ODD条件不满足
011111b=SLOPE_TOO_HIGH // 提示坡度太大
100000b=SPEED_TOO_HIGH // 显示速度太高
100001b=THROTTLE_TAKEOVER // 提示油门干涉，请接管 100010b=STEERING_TAKEOVER // 提示方向盘干涉，请接管 100011b=GEAR_TAKEOVER // 提示挡位干涉
100100b=EPB_ACTIVE // 显示EPB被激活
100101b=TARGET_SLOT_NOT_ACTIVE // 车位不可泊 100110b=PARKING_TIMER_OVERTHRESHOLD // 提示泊车时长超过限制 100111b=PAUSE_COUNT_OVERTHRESHOLD // 提示暂停次数超过限制 101000b=PAUSE_TIME_OVERTHRESHOLD // 提示单次暂停时间超过限制 101001b=SLOT_TOO_NARROW // 提示车位过窄，无法泊入 101010b=PLANNING_TIME_OVERTHRESHOLD // 提示规划时间超过限制 101011b=HANDSHAKE FAIL /泊车握手失败
101100b=EXIT_BUTTON_PRESSED //按下泊车界面“退出”按键101101b=NAVIGATION_EXIT //用户点击底部导航栏其他应用退出101110b=APA_RETURN //RPA信号，用户点击“返回自动泊车101111b=SCREEN_SLIDE_EXIT //用户在中控屏进行一次屏幕侧滑返回信号
110000b==PARKING FAIL //泊车失败
110001b=PARKING SUCCESS //泊车完成
110010b=RPA MOVE OVER 10 Times// 遥控直行按钮超过10次
110011b=EPKB_FAILURE // EPKB故障
110100b~111111b=reserve";
CM_ SG_ 1405 RPA_Enter_Switch_Status "泊车应用进入RPA状态可用性：默认值/可进入/不可进入";
CM_ SG_ 1405 RPA_Exit_Switch_Status "泊车应用退出状态可用性：默认值/可退出/不可退出";
CM_ SG_ 1405 RPA_Button1_Status "开始自动（泊车/巡航）按键状态：默认值/显示(高亮置蓝)/不显示(置灰)/隐藏";
CM_ SG_ 1405 RPA_Button2_Status "中止自动（泊车/巡航)按键状态：默认值/显示(高亮置蓝)/不显示(置灰)/隐藏";
CM_ SG_ 1405 RPA_Park_Pause_Notify "RPA暂停原因报文：
000000b = No Request // 无请求
000001b = DRIVER_DOOR_OPEN // 驾驶员车门打开
000010b = MoveDsitanceExceedLimit // 移动距离超过限制
000011b = Reserve // 预留
000100b = PASSENGER_DOOR_OPEN // 乘客车门打开
000101b = FRONT_HOOD_OPEN // 前引擎盖打开
000110b = BACK_TRUNK_OPEN // 后备箱打开
000111b = REARVIEW_MIRROR_FOLDER // 后视镜折叠
001000b = BLUETOOTH_CONNECTION_FAIL // 蓝牙连接失败
001001b = BRAKE_TAKEOVER // 刹车接管
001010b = OBSTACLE_ONPATH // 路径上有障碍物";
CM_ SG_ 1405 RPA_Park_Quit_Notify "RPA退出原因报文：RPA_Park_Quit_Notify
000000b=No Request // 初始值
000001b=CHARGING_GUN_CONNECT // 提示请拔下充电枪 000010b=TIER_PRESSURE_FAILURE // 提示轮胎压力报警 000011b=RAIN_SENSOR_FAILURE // 提示雨刷传感器故障 000100b=BLUETOOTH_CONNECTION_FAIL // 提示蓝牙连接失败 000101b=FRONT_AVM_FAILURE // 提示AVM前方故障
000110b=REAR_AVM_FAILURE // 提示AVM后方故障
000111b=LEFT_AVM_FAILURE // 提示AVM左侧故障
001000b=RIGHT_AVM_FAILURE // 提示AVM右侧故障 001001b=SONAR_CONT_FAILURE // 提示超声波雷达控制器故障 001010b=FRONT_SONAR_FAILURE // 提示前方超声波雷达故障 001011b=SIDE_SONAR_FAILURE // 提示侧方超声波雷达故障 001100b=REAR_SONAR_FAILURE // 提示后方超声波雷达故障 001101b=ADCU_SW_FAILURE // 提示ADCU软件系统故障 001110b=ADCU_HW_FAILURE // 提示ADCU硬件系统故障
001111b=VCM_FAILURE // 提示VCM故障
010000b=IBC_FAILURE // 提示IBC故障
010001b=EPS_FAILURE // 提示EPS故障
010010b=IMU_FAILURE // 提示IMU故障
010011b=ABS_FAILURE // 提示ABS故障
010100b=ESC_FAILURE // 提示ESC故障
010101b=BLE_FAILURE // 提示蓝牙故障
010110b=ABS_ACTIVE // 显示ABS被激活
010111b=ESC_ACTIVE // 显示ESC被激活
011000b=OTHER_AD_ACTIVE // 显示其它AD功能被激活
011001b=MEB_ACTIVE // 提示MEB被激活
011010b=AEB_ACTIVE // 提示AEB被激活
011011b=RCTB_ACTIVE // 提示RCTB被激活
011100b=FCTB_ACTIVE // 提示FCTB被激活
011101b=ACU_ACTIVE // 提示ACU被激活
011110b=ODD_NOT_SATISFIED // 提示ODD条件不满足
011111b=SLOPE_TOO_HIGH // 提示坡度太大
100000b=SPEED_TOO_HIGH // 显示速度太高
100001b=THROTTLE_TAKEOVER // 提示油门干涉，请接管 100010b=STEERING_TAKEOVER // 提示方向盘干涉，请接管 100011b=GEAR_TAKEOVER // 提示挡位干涉
100100b=EPB_ACTIVE // 显示EPB被激活
100101b=TARGET_SLOT_NOT_ACTIVE // 车位不可泊 100110b=PARKING_TIMER_OVERTHRESHOLD // 提示泊车时长超过限制 100111b=PAUSE_COUNT_OVERTHRESHOLD // 提示暂停次数超过限制 101000b=PAUSE_TIME_OVERTHRESHOLD // 提示单次暂停时间超过限制 101001b=SLOT_TOO_NARROW // 提示车位过窄，无法泊入 101010b=PLANNING_TIME_OVERTHRESHOLD // 提示规划时间超过限制 101011b=HANDSHAKE FAIL /泊车握手失败
101100b=EXIT_BUTTON_PRESSED //按下泊车界面“退出”按键101101b=NAVIGATION_EXIT //用户点击底部导航栏其他应用退出101110b=APA_RETURN //RPA信号，用户点击“返回自动泊车101111b=SCREEN_SLIDE_EXIT //用户在中控屏进行一次屏幕侧滑返回信号
110000b==PARKING FAIL //泊车失败
110001b=PARKING SUCCESS //泊车完成
110010b=RPA MOVE OVER 10 Times// 遥控直行按钮超过10次
110011b=EPKB_FAILURE // EPKB故障
110100b~111111b=reserve";
CM_ SG_ 1405 RPA_BLEfeedbackReq "握手控制状态反馈";
CM_ SG_ 1405 RPAparkinSelectResult "0000b=Invalid 无效值
0001b=Vertical_ Left  //左侧垂直车位
0010b=Vertical_ Right //右侧垂直车位
0011b=Vertical_ Front //前侧垂直车位
0100b=Vertical_ Rear  //后侧垂直车位
0101b=Horizontal_Left  //左侧水平车位
0110b=Horizontal_Right  //右侧水平车位";
CM_ SG_ 1445 APASwitchReq "【发三帧】按键请求（泊车应用将进入/退出）：不请求/进入/退出/保留";
CM_ SG_ 1445 APAButtonReq "【发三帧】按键请求集合：无请求/开始泊车请求/泊车暂停请求/泊车恢复请求/泊车结束请求/遥控泊车开始请求/
遥控泊车结束请求/记忆泊车开始学习请求/记忆泊车学习结束请求/记忆泊车巡航开始请求/记忆泊车巡航暂停请求/记忆泊车恢复巡航请求/记忆泊车巡航结束请求";
CM_ SG_ 1445 APA_ParkSpot_Select "【发三帧】车位选择请求：默认无选择/选择的车位ID";
CM_ SG_ 1445 APA_ParkinDir_Select "【发三帧】泊入方向选择：点击车位进行切换，车头泊入或车尾泊入";
CM_ SG_ 1445 APA_parkoutDir_Select "【发三帧】泊出方向选择：6个方向";
CM_ SG_ 1445 APA_Setting_Request "【发三帧】功能设置：HPA on/off/HPA自动推荐开/关/APA自动推荐开/关/雷达墙显示开/关/泊车速度慢/中/快/TTS播报开关";
CM_ SG_ 1445 APA_PopUp_Response "【发三帧】弹窗响应（我要泊车按键）：退出Exit/Cancel，暂时保留；点击按键进入泊车功能对应Confirm";
CM_ SG_ 1445 HPA_Route_Select "【发三帧】";
CM_ SG_ 1445 HPA_Route_Delete "【发三帧】";
CM_ SG_ 1445 CFDI_ALL_SW "None";
CM_ SG_ 1445 CFDI_PD_SW "None";
CM_ SG_ 1393 RPA_Switch_Request "按键请求（泊车应用将进入/退出）：不请求/进入/退出/保留";
CM_ SG_ 1393 RPA_Button_Request "0000b = no button request // 无按钮请求
0001b = parkin start // 开始泊车入库
0010b = parkin pause // 暂停泊车入库
0011b = parkin resume // 恢复泊车入库
0100b = parkin stop // 停止泊车入库
0101b = parkout start // 开始泊车出库
0110b = parkout pause // 暂停泊车出库
0111b = parkout resume // 恢复泊车出库
1000b = parkout stop // 停止泊车出库
1001b = RPA Ahead // 遥控直行向前
1010b = RPA Back // 遥控直行向后
1011b = Parkin/out Entrance // （用户）点击进入遥控泊车
1100b = Straight Entrance // （用户）点击进入遥控直行";
CM_ SG_ 1393 RPA_BLE_Status "蓝牙故障信号";
CM_ SG_ 1393 RPA_BLE_Connect_Status "APP与BLE蓝牙连接状态";
CM_ SG_ 1393 RPA_BLE_Control_Active "RPA握手心跳信号";
CM_ SG_ 1393 RPA_BLE_Mode_Valid "遥控泊车模式有效标志";
CM_ SG_ 1393 RPA_BLE_Control_Request "遥控泊车开启请求（握手信号之一）";
CM_ SG_ 1393 Counter_BLE_RPA "None";
CM_ SG_ 1393 CRC_BLE_RPA "None";
CM_ SG_ 1228 PEBS_INFO "None";
CM_ SG_ 1228 ACC_INFO "None";
CM_ SG_ 1228 ALIVE_CNT "None";
CM_ SG_ 1228 CHECKSUM "None";
CM_ SG_ 1647 FrHeatWire_Status "None";
CM_ SG_ 1647 FrHeatWireCircuit_Status "None";
CM_ SG_ 1647 VoltageSupply_BCM "None";
CM_ SG_ 1031 GNSS_GSV_total_len "None";
CM_ SG_ 1031 GNSS_GSV_pack_total_num "None";
CM_ SG_ 1031 GNSS_GSV_pack_id "None";
CM_ SG_ 1031 GNSS_GSV_frame_len "None";
CM_ SG_ 1031 GNSS_GSV_num "None";
CM_ SG_ 1031 GNSS_GSV_type_1 "None";
CM_ SG_ 1031 GNSS_GSV_id_1 "None";
CM_ SG_ 1031 GNSS_GSV_prn_1 "None";
CM_ SG_ 1031 GNSS_GSV_elv_1 "None";
CM_ SG_ 1031 GNSS_GSV_CNR_1 "None";
CM_ SG_ 1031 GNSS_GSV_az_1 "None";
CM_ SG_ 1031 GNSS_GSV_type_2 "None";
CM_ SG_ 1031 GNSS_GSV_id_2 "None";
CM_ SG_ 1031 GNSS_GSV_prn_2 "None";
CM_ SG_ 1031 GNSS_GSV_elv_2 "None";
CM_ SG_ 1031 GNSS_GSV_CNR_2 "None";
CM_ SG_ 1031 GNSS_GSV_az_2 "None";
CM_ SG_ 1031 GNSS_GSV_type_3 "None";
CM_ SG_ 1031 GNSS_GSV_id_3 "None";
CM_ SG_ 1031 GNSS_GSV_prn_3 "None";
CM_ SG_ 1031 GNSS_GSV_elv_3 "None";
CM_ SG_ 1031 GNSS_GSV_CNR_3 "None";
CM_ SG_ 1031 GNSS_GSV_az_3 "None";
CM_ SG_ 1031 GNSS_GSV_type_4 "None";
CM_ SG_ 1031 GNSS_GSV_id_4 "None";
CM_ SG_ 1031 GNSS_GSV_prn_4 "None";
CM_ SG_ 1031 GNSS_GSV_elv_4 "None";
CM_ SG_ 1031 GNSS_GSV_CNR_4 "None";
CM_ SG_ 1031 GNSS_GSV_az_4 "None";
CM_ SG_ 1031 GNSS_GSV_type_5 "None";
CM_ SG_ 1031 GNSS_GSV_id_5 "None";
CM_ SG_ 1031 GNSS_GSV_prn_5 "None";
CM_ SG_ 1031 GNSS_GSV_elv_5 "None";
CM_ SG_ 1031 GNSS_GSV_CNR_5 "None";
CM_ SG_ 1031 GNSS_GSV_az_5 "None";
CM_ SG_ 1031 GNSS_GSV_type_6 "None";
CM_ SG_ 1031 GNSS_GSV_id_6 "None";
CM_ SG_ 1031 GNSS_GSV_prn_6 "None";
CM_ SG_ 1031 GNSS_GSV_elv_6 "None";
CM_ SG_ 1031 GNSS_GSV_CNR_6 "None";
CM_ SG_ 1031 GNSS_GSV_az_6 "None";
CM_ SG_ 1031 GNSS_GSV_type_7 "None";
CM_ SG_ 1031 GNSS_GSV_id_7 "None";
CM_ SG_ 1031 GNSS_GSV_prn_7 "None";
CM_ SG_ 1031 GNSS_GSV_elv_7 "None";
CM_ SG_ 1031 GNSS_GSV_CNR_7 "None";
CM_ SG_ 1031 GNSS_GSV_az_7 "None";
CM_ SG_ 1031 GNSS_GSV_type_8 "None";
CM_ SG_ 1031 GNSS_GSV_id_8 "None";
CM_ SG_ 1031 GNSS_GSV_prn_8 "None";
CM_ SG_ 1031 GNSS_GSV_elv_8 "None";
CM_ SG_ 1031 GNSS_GSV_CNR_8 "None";
CM_ SG_ 1031 GNSS_GSV_az_8 "None";
CM_ SG_ 1031 GNSS_GSV_type_9 "None";
CM_ SG_ 1031 GNSS_GSV_id_9 "None";
CM_ SG_ 1031 GNSS_GSV_prn_9 "None";
CM_ SG_ 1031 GNSS_GSV_elv_9 "None";
CM_ SG_ 1031 GNSS_GSV_CNR_9 "None";
CM_ SG_ 1031 GNSS_GSV_az_9 "None";
CM_ SG_ 1032 GNSS_utc_time "None";
CM_ SG_ 1032 GNSS_timestamp_us "None";
CM_ SG_ 1032 GNSS_Seq "None";
CM_ SG_ 1032 GNSS_latitude "None";
CM_ SG_ 1032 GNSS_longitude "None";
CM_ SG_ 1032 GNSS_altitude "None";
CM_ SG_ 1032 GNSS_status "None";
CM_ SG_ 1032 GNSS_numSats "None";
CM_ SG_ 1032 GNSS_numSatsUsed "None";
CM_ SG_ 1032 GNSS_azi_track "None";
CM_ SG_ 1032 GNSS_position_type "None";
CM_ SG_ 1032 GNSS_hdop "None";
CM_ SG_ 1032 GNSS_pdop "None";
CM_ SG_ 1032 GNSS_vdop "None";
CM_ SG_ 1032 GNSS_gpsSow "None";
CM_ SG_ 1032 GNSS_gpsWeek "None";
CM_ SG_ 1032 GNSS_tSync_status "None";
CM_ SG_ 1032 GNSS_longitude_std "None";
CM_ SG_ 1032 GNSS_latitude_std "None";
CM_ SG_ 1032 GNSS_altitude_std "None";
CM_ SG_ 1032 counter "None";
CM_ SG_ 1032 checksum "None";
CM_ SG_ 1033 GNSS_utc_time "None";
CM_ SG_ 1033 GNSS_timestamp_us "None";
CM_ SG_ 1033 GNSS_Seq "None";
CM_ SG_ 1033 GNSS_vel_e "None";
CM_ SG_ 1033 GNSS_vel_n "None";
CM_ SG_ 1033 GNSS_vel_u "None";
CM_ SG_ 1033 GNSS_speed "None";
CM_ SG_ 1033 GNSS_speed_std "None";
CM_ SG_ 1033 GNSS_velocity_type "None";
CM_ SG_ 1033 GNSS_gpsSow "None";
CM_ SG_ 1033 GNSS_gpsWeek "None";
CM_ SG_ 1033 counter "None";
CM_ SG_ 1033 checksum "None";
CM_ SG_ 1493 DMS_STA "状态机(该信号不使用，预留）";
CM_ SG_ 1493 DMS_E_FAILURE "非方向盘原因的相机遮挡
方向盘导致的相机遮挡(不报failure）
未遮挡";
CM_ SG_ 1493 DMS_S_FAILURE "图像过曝
图像过暗
帧冻结
帧撕裂
动态标定失败
相机硬件故障
CAN通信故障（不使用）
VCM传感器故障（不使用）
BCM传感器故障（不使用）
无故障";
CM_ SG_ 1493 DD_SW_RESP "DMS疲劳/分心功能开关";
CM_ SG_ 1493 DA_SW_RESP "DMS危险行为功能开关";
CM_ SG_ 1493 DD_SENSITIVITY_SW_RESP "DMS疲劳/分心灵敏度调节（低高）";
CM_ SG_ 1493 DMS_HEAD_DETECT "驾驶员人头检测";
CM_ SG_ 1493 DMS_FACE_DETECT "驾驶员面部可见性检测";
CM_ SG_ 1493 DROWNINESS_LV "疲劳
00b:清醒
001b：轻度疲劳
010b：重度疲劳
011b：驾驶员无反应
100b：OTA改成NOA Driver unresponsive
101b-110b：未使用
111b：算法初始化时输出无效值";
CM_ SG_ 1493 DISTRACTION_LV "分心
00b:专注
001b：轻度分心
010b：重度分心
011b：驾驶员无反应
100b：OTA改成NOA Driver unresponsive
101b-110b：未使用
111b：算法初始化时输出无效值";
CM_ SG_ 1493 DANGEROUS_ACT "危险行为
00：无危险行为
01：抽烟
10：打电话
11:算法初始化时输出无效值";
CM_ SG_ 1493 Driver_X "整车坐标系原点：后轴中心点对地的投影点
整车坐标系XY平面：平行于地面
整车坐标系X轴：定义为整车坐标系原点指向车头方向
整车坐标系Y轴：定义为整车坐标系原点指向左后轮位置
整车坐标系Z轴：垂直于XY平面
K1B尺寸：4850*1910*1680
当信号发出FirstFrameValue列的值时，应视为此信号发出无效值。";
CM_ SG_ 1493 Driver_Y "None";
CM_ SG_ 1493 Driver_Z "None";
CM_ SG_ 2563508093 ADCU_Rem_Diag_Tx "None";
CM_ SG_ 1885 ADCU_Diag_Rx "None";
CM_ SG_ 1917 ADCU_Diag_Tx "None";
CM_ SG_ 2564687694 Sonar_FOTA_Rx "None";
CM_ SG_ 2564687726 Sonar_FOTA_Tx "None";
CM_ SG_ 2563508078 Sonar_Rem_Diag_Tx "None";
CM_ SG_ 1870 Sonar_Diag_Rx "None";
CM_ SG_ 1902 Sonar_Diag_Tx "None";
CM_ SG_ 2564687651 FR_RADAR_FOTA_Rx "None";
CM_ SG_ 2564687669 FR_RADAR_FOTA_Tx "None";
CM_ SG_ 2563508021 FR_RADAR_Rem_Diag_Tx "None";
CM_ SG_ 1827 FR_RADAR_Diag_Rx "None";
CM_ SG_ 1845 FR_RADAR_Diag_Tx "None";
CM_ SG_ 2564687677 SRR_L_FOTA_Rx "None";
CM_ SG_ 2564687678 SRR_L_FOTA_Tx "None";
CM_ SG_ 2563508030 SRR_L_Rem_Diag_Tx "None";
CM_ SG_ 1853 SRR_L_Diag_Rx "None";
CM_ SG_ 1854 SRR_L_Diag_Tx "None";
CM_ SG_ 2564687828 SRR_R_FOTA_Rx "None";
CM_ SG_ 2564687829 SRR_R_FOTA_Tx "None";
CM_ SG_ 2563508181 SRR_R_Rem_Diag_Tx "None";
CM_ SG_ 2004 SRR_R_Diag_Rx "None";
CM_ SG_ 2005 SRR_R_Diag_Tx "None";
CM_ SG_ 2564687728 PBOX_FOTA_Rx "None";
CM_ SG_ 2564687738 PBOX_FOTA_Tx "None";
CM_ SG_ 2563508090 PBOX_Rem_Diag_Tx "None";
CM_ SG_ 1904 PBOX_Diag_Rx "None";
CM_ SG_ 1914 PBOX_Diag_Tx "None";

BA_DEF_ BO_ "DiagConnection" STRING;
BA_DEF_ BO_ "DiagFdOnly" ENUM "Yes", "No";
BA_DEF_ BO_ "DiagRequest" ENUM "Yes", "No";
BA_DEF_ BO_ "DiagResponse" ENUM "Yes", "No";
BA_DEF_ BO_ "GenMsgCycleTime" INT 0 65535;
BA_DEF_ BO_ "GenMsgCycleTimeFast" INT 0 65535;
BA_DEF_ BO_ "GenMsgILSupport" ENUM "Yes", "No";
BA_DEF_ BO_ "GenMsgNrOfRepetition" INT 0 65535;
BA_DEF_ BO_ "GenMsgSendType" ENUM "NoSigSendType", "Cyclic", "Event";
BA_DEF_ BO_ "GenSigSendType" ENUM "Cyclic", "OnWrite", "OnWriteWithRepetition", "OnChange", "OnChangeWithRepetition", "IfActive", "IfActiveWithRepeition","NoSigSendType";
BA_DEF_ BO_ "VFrameFormat" ENUM  "StandardCAN","ExtendedCAN","reserved","reserved","reserved","reserved","reserved","reserved","reserved","reserved","reserved","reserved","reserved","reserved","StandardCAN_FD","ExtendedCAN_FD";
BA_DEF_  "BusType" STRING;
BA_DEF_DEF_ "BusType" "CAN";
BA_DEF_DEF_ "DiagConnection" "0x0";
BA_DEF_DEF_ "DiagFdOnly" "No";
BA_DEF_DEF_ "DiagRequest" "No";
BA_DEF_DEF_ "DiagResponse" "No";
BA_DEF_DEF_ "GenMsgCycleTime" 0;
BA_DEF_DEF_ "GenMsgCycleTimeFast" 0;
BA_DEF_DEF_ "GenMsgILSupport" "Yes";
BA_DEF_DEF_ "GenMsgNrOfRepetition" 0;
BA_DEF_DEF_ "GenMsgSendType" "NoSigSendType";
BA_DEF_DEF_ "GenSigSendType" "NoSigSendType";

BA_ "BusType"   "CAN FD";

BA_ "GenMsgCycleTime" BO_ 1258 100;
BA_ "GenMsgSendType" BO_ 1258 1;
BA_ "GenSigSendType" BO_ 1258 0;
BA_ "VFrameFormat" BO_ 1258 14;
BA_ "GenMsgCycleTime" BO_ 1293 100;
BA_ "GenMsgSendType" BO_ 1293 1;
BA_ "GenSigSendType" BO_ 1293 0;
BA_ "VFrameFormat" BO_ 1293 14;
BA_ "GenMsgCycleTime" BO_ 861 100;
BA_ "GenMsgSendType" BO_ 861 1;
BA_ "GenSigSendType" BO_ 861 1;
BA_ "VFrameFormat" BO_ 861 14;
BA_ "GenMsgCycleTime" BO_ 536 20;
BA_ "GenMsgSendType" BO_ 536 1;
BA_ "GenSigSendType" BO_ 536 0;
BA_ "VFrameFormat" BO_ 536 14;
BA_ "GenMsgCycleTime" BO_ 1549 100;
BA_ "GenMsgSendType" BO_ 1549 1;
BA_ "GenSigSendType" BO_ 1549 1;
BA_ "VFrameFormat" BO_ 1549 14;
BA_ "GenMsgCycleTime" BO_ 1573 100;
BA_ "GenMsgSendType" BO_ 1573 1;
BA_ "GenSigSendType" BO_ 1573 1;
BA_ "VFrameFormat" BO_ 1573 14;
BA_ "GenMsgCycleTime" BO_ 1532 100;
BA_ "GenMsgSendType" BO_ 1532 1;
BA_ "GenSigSendType" BO_ 1532 1;
BA_ "VFrameFormat" BO_ 1532 14;
BA_ "GenMsgCycleTime" BO_ 1480 50;
BA_ "GenMsgSendType" BO_ 1480 1;
BA_ "GenSigSendType" BO_ 1480 0;
BA_ "VFrameFormat" BO_ 1480 14;
BA_ "GenMsgCycleTime" BO_ 901 100;
BA_ "GenMsgSendType" BO_ 901 1;
BA_ "GenSigSendType" BO_ 901 0;
BA_ "VFrameFormat" BO_ 901 14;
BA_ "GenMsgCycleTime" BO_ 858 100;
BA_ "GenMsgSendType" BO_ 858 1;
BA_ "GenSigSendType" BO_ 858 1;
BA_ "VFrameFormat" BO_ 858 14;
BA_ "GenMsgCycleTime" BO_ 1338 100;
BA_ "GenMsgSendType" BO_ 1338 1;
BA_ "GenSigSendType" BO_ 1338 0;
BA_ "VFrameFormat" BO_ 1338 14;
BA_ "GenMsgCycleTime" BO_ 1339 100;
BA_ "GenMsgSendType" BO_ 1339 1;
BA_ "GenSigSendType" BO_ 1339 0;
BA_ "VFrameFormat" BO_ 1339 14;
BA_ "GenMsgCycleTime" BO_ 1340 100;
BA_ "GenMsgSendType" BO_ 1340 1;
BA_ "GenSigSendType" BO_ 1340 0;
BA_ "VFrameFormat" BO_ 1340 14;
BA_ "GenMsgCycleTime" BO_ 1342 100;
BA_ "GenMsgSendType" BO_ 1342 1;
BA_ "GenSigSendType" BO_ 1342 0;
BA_ "VFrameFormat" BO_ 1342 14;
BA_ "GenMsgCycleTime" BO_ 1343 100;
BA_ "GenMsgSendType" BO_ 1343 1;
BA_ "GenSigSendType" BO_ 1343 1;
BA_ "VFrameFormat" BO_ 1343 14;
BA_ "GenMsgCycleTime" BO_ 1351 100;
BA_ "GenMsgSendType" BO_ 1351 1;
BA_ "GenSigSendType" BO_ 1351 0;
BA_ "VFrameFormat" BO_ 1351 14;
BA_ "GenMsgCycleTime" BO_ 793 50;
BA_ "GenMsgSendType" BO_ 793 1;
BA_ "GenSigSendType" BO_ 793 0;
BA_ "VFrameFormat" BO_ 793 14;
BA_ "GenMsgCycleTime" BO_ 578 10;
BA_ "GenMsgSendType" BO_ 578 1;
BA_ "GenSigSendType" BO_ 578 0;
BA_ "VFrameFormat" BO_ 578 14;
BA_ "GenMsgCycleTime" BO_ 582 10;
BA_ "GenMsgSendType" BO_ 582 1;
BA_ "GenSigSendType" BO_ 582 0;
BA_ "VFrameFormat" BO_ 582 14;
BA_ "GenMsgCycleTime" BO_ 1383 500;
BA_ "GenMsgSendType" BO_ 1383 1;
BA_ "GenSigSendType" BO_ 1383 0;
BA_ "VFrameFormat" BO_ 1383 14;
BA_ "GenMsgCycleTime" BO_ 1477 100;
BA_ "GenMsgSendType" BO_ 1477 1;
BA_ "GenSigSendType" BO_ 1477 0;
BA_ "VFrameFormat" BO_ 1477 14;
BA_ "GenMsgCycleTime" BO_ 581 20;
BA_ "GenMsgSendType" BO_ 581 1;
BA_ "GenSigSendType" BO_ 581 0;
BA_ "VFrameFormat" BO_ 581 14;
BA_ "GenMsgCycleTime" BO_ 682 20;
BA_ "GenMsgSendType" BO_ 682 1;
BA_ "GenSigSendType" BO_ 682 0;
BA_ "VFrameFormat" BO_ 682 14;
BA_ "GenMsgCycleTime" BO_ 852 40;
BA_ "GenMsgSendType" BO_ 852 1;
BA_ "GenSigSendType" BO_ 852 0;
BA_ "VFrameFormat" BO_ 852 14;
BA_ "GenMsgCycleTime" BO_ 576 20;
BA_ "GenMsgSendType" BO_ 576 1;
BA_ "GenSigSendType" BO_ 576 0;
BA_ "VFrameFormat" BO_ 576 14;
BA_ "GenMsgCycleTime" BO_ 658 20;
BA_ "GenMsgSendType" BO_ 658 1;
BA_ "GenSigSendType" BO_ 658 0;
BA_ "VFrameFormat" BO_ 658 14;
BA_ "GenMsgCycleTime" BO_ 644 20;
BA_ "GenMsgSendType" BO_ 644 1;
BA_ "GenSigSendType" BO_ 644 0;
BA_ "VFrameFormat" BO_ 644 14;
BA_ "GenMsgCycleTime" BO_ 645 20;
BA_ "GenMsgSendType" BO_ 645 1;
BA_ "GenSigSendType" BO_ 645 0;
BA_ "VFrameFormat" BO_ 645 14;
BA_ "GenMsgCycleTime" BO_ 646 20;
BA_ "GenMsgSendType" BO_ 646 1;
BA_ "GenSigSendType" BO_ 646 0;
BA_ "VFrameFormat" BO_ 646 14;
BA_ "GenMsgCycleTime" BO_ 2 10;
BA_ "GenMsgSendType" BO_ 2 1;
BA_ "GenSigSendType" BO_ 2 0;
BA_ "VFrameFormat" BO_ 2 14;
BA_ "GenMsgCycleTime" BO_ 500 10;
BA_ "GenMsgSendType" BO_ 500 1;
BA_ "GenSigSendType" BO_ 500 0;
BA_ "VFrameFormat" BO_ 500 14;
BA_ "GenMsgCycleTime" BO_ 502 10;
BA_ "GenMsgSendType" BO_ 502 1;
BA_ "GenSigSendType" BO_ 502 0;
BA_ "VFrameFormat" BO_ 502 14;
BA_ "GenMsgCycleTime" BO_ 384 10;
BA_ "GenMsgSendType" BO_ 384 1;
BA_ "GenSigSendType" BO_ 384 0;
BA_ "VFrameFormat" BO_ 384 14;
BA_ "GenMsgCycleTime" BO_ 1361 100;
BA_ "GenMsgSendType" BO_ 1361 1;
BA_ "GenSigSendType" BO_ 1361 0;
BA_ "VFrameFormat" BO_ 1361 14;
BA_ "GenMsgCycleTime" BO_ 1449 100;
BA_ "GenMsgSendType" BO_ 1449 1;
BA_ "GenSigSendType" BO_ 1449 0;
BA_ "VFrameFormat" BO_ 1449 14;
BA_ "GenMsgCycleTime" BO_ 689 20;
BA_ "GenMsgSendType" BO_ 689 1;
BA_ "GenSigSendType" BO_ 689 0;
BA_ "VFrameFormat" BO_ 689 14;
BA_ "GenMsgCycleTime" BO_ 695 20;
BA_ "GenMsgSendType" BO_ 695 1;
BA_ "GenSigSendType" BO_ 695 0;
BA_ "VFrameFormat" BO_ 695 14;
BA_ "GenMsgCycleTime" BO_ 1260 100;
BA_ "GenMsgSendType" BO_ 1260 1;
BA_ "GenSigSendType" BO_ 1260 0;
BA_ "VFrameFormat" BO_ 1260 14;
BA_ "GenMsgCycleTime" BO_ 640 20;
BA_ "GenMsgSendType" BO_ 640 1;
BA_ "GenSigSendType" BO_ 640 0;
BA_ "VFrameFormat" BO_ 640 14;
BA_ "GenMsgCycleTime" BO_ 853 40;
BA_ "GenMsgSendType" BO_ 853 1;
BA_ "GenSigSendType" BO_ 853 0;
BA_ "VFrameFormat" BO_ 853 14;
BA_ "GenMsgCycleTime" BO_ 1402 100;
BA_ "GenMsgSendType" BO_ 1402 1;
BA_ "GenSigSendType" BO_ 1402 0;
BA_ "VFrameFormat" BO_ 1402 14;
BA_ "GenMsgCycleTime" BO_ 1403 100;
BA_ "GenMsgSendType" BO_ 1403 1;
BA_ "GenSigSendType" BO_ 1403 1;
BA_ "VFrameFormat" BO_ 1403 14;
BA_ "GenMsgCycleTime" BO_ 1405 100;
BA_ "GenMsgSendType" BO_ 1405 1;
BA_ "GenSigSendType" BO_ 1405 0;
BA_ "VFrameFormat" BO_ 1405 14;
BA_ "GenMsgCycleTime" BO_ 1445 100;
BA_ "GenMsgSendType" BO_ 1445 1;
BA_ "GenSigSendType" BO_ 1445 1;
BA_ "VFrameFormat" BO_ 1445 14;
BA_ "GenMsgCycleTime" BO_ 1393 50;
BA_ "GenMsgSendType" BO_ 1393 1;
BA_ "GenSigSendType" BO_ 1393 1;
BA_ "VFrameFormat" BO_ 1393 14;
BA_ "GenMsgCycleTime" BO_ 1228 100;
BA_ "GenMsgSendType" BO_ 1228 1;
BA_ "GenSigSendType" BO_ 1228 0;
BA_ "VFrameFormat" BO_ 1228 14;
BA_ "GenMsgCycleTime" BO_ 1647 100;
BA_ "GenMsgSendType" BO_ 1647 1;
BA_ "GenSigSendType" BO_ 1647 0;
BA_ "VFrameFormat" BO_ 1647 14;
BA_ "GenMsgCycleTime" BO_ 1031 1000;
BA_ "GenMsgSendType" BO_ 1031 1;
BA_ "GenSigSendType" BO_ 1031 0;
BA_ "VFrameFormat" BO_ 1031 14;
BA_ "GenMsgCycleTime" BO_ 1032 1000;
BA_ "GenMsgSendType" BO_ 1032 1;
BA_ "GenSigSendType" BO_ 1032 0;
BA_ "VFrameFormat" BO_ 1032 14;
BA_ "GenMsgCycleTime" BO_ 1033 1000;
BA_ "GenMsgSendType" BO_ 1033 1;
BA_ "GenSigSendType" BO_ 1033 0;
BA_ "VFrameFormat" BO_ 1033 14;
BA_ "GenMsgCycleTime" BO_ 1493 100;
BA_ "GenMsgSendType" BO_ 1493 1;
BA_ "GenSigSendType" BO_ 1493 1;
BA_ "VFrameFormat" BO_ 1493 14;
BA_ "GenMsgCycleTimeFast" BO_ 2563508093 2;
BA_ "GenMsgNrOfRepetition" BO_ 2563508093 2;
BA_ "GenMsgSendType" BO_ 2563508093 2;
BA_ "GenSigSendType" BO_ 2563508093 3;
BA_ "VFrameFormat" BO_ 2563508093 15;
BA_ "DiagFdOnly" BO_ 1885 0;
BA_ "DiagRequest" BO_ 1885 0;
BA_ "GenMsgILSupport" BO_ 1885 1;
BA_ "GenMsgSendType" BO_ 1885 2;
BA_ "GenSigSendType" BO_ 1885 3;
BA_ "VFrameFormat" BO_ 1885 14;
BA_ "DiagFdOnly" BO_ 1917 0;
BA_ "DiagResponse" BO_ 1917 0;
BA_ "GenMsgILSupport" BO_ 1917 1;
BA_ "GenMsgSendType" BO_ 1917 2;
BA_ "GenSigSendType" BO_ 1917 3;
BA_ "VFrameFormat" BO_ 1917 14;
BA_ "GenMsgILSupport" BO_ 2564687694 1;
BA_ "GenMsgSendType" BO_ 2564687694 2;
BA_ "GenSigSendType" BO_ 2564687694 3;
BA_ "VFrameFormat" BO_ 2564687694 15;
BA_ "GenMsgILSupport" BO_ 2564687726 1;
BA_ "GenMsgSendType" BO_ 2564687726 2;
BA_ "GenSigSendType" BO_ 2564687726 3;
BA_ "VFrameFormat" BO_ 2564687726 15;
BA_ "GenMsgCycleTimeFast" BO_ 2563508078 2;
BA_ "GenMsgNrOfRepetition" BO_ 2563508078 2;
BA_ "GenMsgSendType" BO_ 2563508078 2;
BA_ "GenSigSendType" BO_ 2563508078 3;
BA_ "VFrameFormat" BO_ 2563508078 15;
BA_ "GenMsgILSupport" BO_ 1870 1;
BA_ "GenMsgSendType" BO_ 1870 2;
BA_ "GenSigSendType" BO_ 1870 3;
BA_ "VFrameFormat" BO_ 1870 14;
BA_ "GenMsgILSupport" BO_ 1902 1;
BA_ "GenMsgSendType" BO_ 1902 2;
BA_ "GenSigSendType" BO_ 1902 3;
BA_ "VFrameFormat" BO_ 1902 14;
BA_ "GenMsgILSupport" BO_ 2564687651 1;
BA_ "GenMsgSendType" BO_ 2564687651 2;
BA_ "GenSigSendType" BO_ 2564687651 3;
BA_ "VFrameFormat" BO_ 2564687651 15;
BA_ "GenMsgILSupport" BO_ 2564687669 1;
BA_ "GenMsgSendType" BO_ 2564687669 2;
BA_ "GenSigSendType" BO_ 2564687669 3;
BA_ "VFrameFormat" BO_ 2564687669 15;
BA_ "GenMsgCycleTimeFast" BO_ 2563508021 2;
BA_ "GenMsgNrOfRepetition" BO_ 2563508021 2;
BA_ "GenMsgSendType" BO_ 2563508021 2;
BA_ "GenSigSendType" BO_ 2563508021 3;
BA_ "VFrameFormat" BO_ 2563508021 15;
BA_ "GenMsgILSupport" BO_ 1827 1;
BA_ "GenMsgSendType" BO_ 1827 2;
BA_ "GenSigSendType" BO_ 1827 3;
BA_ "VFrameFormat" BO_ 1827 14;
BA_ "GenMsgILSupport" BO_ 1845 1;
BA_ "GenMsgSendType" BO_ 1845 2;
BA_ "GenSigSendType" BO_ 1845 3;
BA_ "VFrameFormat" BO_ 1845 14;
BA_ "GenMsgILSupport" BO_ 2564687677 1;
BA_ "GenMsgSendType" BO_ 2564687677 2;
BA_ "GenSigSendType" BO_ 2564687677 3;
BA_ "VFrameFormat" BO_ 2564687677 15;
BA_ "GenMsgILSupport" BO_ 2564687678 1;
BA_ "GenMsgSendType" BO_ 2564687678 2;
BA_ "GenSigSendType" BO_ 2564687678 3;
BA_ "VFrameFormat" BO_ 2564687678 15;
BA_ "GenMsgCycleTimeFast" BO_ 2563508030 2;
BA_ "GenMsgNrOfRepetition" BO_ 2563508030 2;
BA_ "GenMsgSendType" BO_ 2563508030 2;
BA_ "GenSigSendType" BO_ 2563508030 3;
BA_ "VFrameFormat" BO_ 2563508030 15;
BA_ "GenMsgILSupport" BO_ 1853 1;
BA_ "GenMsgSendType" BO_ 1853 2;
BA_ "GenSigSendType" BO_ 1853 3;
BA_ "VFrameFormat" BO_ 1853 14;
BA_ "GenMsgILSupport" BO_ 1854 1;
BA_ "GenMsgSendType" BO_ 1854 2;
BA_ "GenSigSendType" BO_ 1854 3;
BA_ "VFrameFormat" BO_ 1854 14;
BA_ "GenMsgILSupport" BO_ 2564687828 1;
BA_ "GenMsgSendType" BO_ 2564687828 2;
BA_ "GenSigSendType" BO_ 2564687828 3;
BA_ "VFrameFormat" BO_ 2564687828 15;
BA_ "GenMsgILSupport" BO_ 2564687829 1;
BA_ "GenMsgSendType" BO_ 2564687829 2;
BA_ "GenSigSendType" BO_ 2564687829 3;
BA_ "VFrameFormat" BO_ 2564687829 15;
BA_ "GenMsgCycleTimeFast" BO_ 2563508181 2;
BA_ "GenMsgNrOfRepetition" BO_ 2563508181 2;
BA_ "GenMsgSendType" BO_ 2563508181 2;
BA_ "GenSigSendType" BO_ 2563508181 3;
BA_ "VFrameFormat" BO_ 2563508181 15;
BA_ "GenMsgILSupport" BO_ 2004 1;
BA_ "GenMsgSendType" BO_ 2004 2;
BA_ "GenSigSendType" BO_ 2004 3;
BA_ "VFrameFormat" BO_ 2004 14;
BA_ "GenMsgILSupport" BO_ 2005 1;
BA_ "GenMsgSendType" BO_ 2005 2;
BA_ "GenSigSendType" BO_ 2005 3;
BA_ "VFrameFormat" BO_ 2005 14;
BA_ "GenMsgILSupport" BO_ 2564687728 1;
BA_ "GenMsgSendType" BO_ 2564687728 2;
BA_ "GenSigSendType" BO_ 2564687728 3;
BA_ "VFrameFormat" BO_ 2564687728 15;
BA_ "GenMsgILSupport" BO_ 2564687738 1;
BA_ "GenMsgSendType" BO_ 2564687738 2;
BA_ "GenSigSendType" BO_ 2564687738 3;
BA_ "VFrameFormat" BO_ 2564687738 15;
BA_ "GenMsgCycleTimeFast" BO_ 2563508090 2;
BA_ "GenMsgNrOfRepetition" BO_ 2563508090 2;
BA_ "GenMsgSendType" BO_ 2563508090 2;
BA_ "GenSigSendType" BO_ 2563508090 3;
BA_ "VFrameFormat" BO_ 2563508090 15;
BA_ "GenMsgILSupport" BO_ 1904 1;
BA_ "GenMsgSendType" BO_ 1904 2;
BA_ "GenSigSendType" BO_ 1904 3;
BA_ "VFrameFormat" BO_ 1904 14;
BA_ "GenMsgILSupport" BO_ 1914 1;
BA_ "GenMsgSendType" BO_ 1914 2;
BA_ "GenSigSendType" BO_ 1914 3;
BA_ "VFrameFormat" BO_ 1914 14;

VAL_ 1258 ADControl_enable 0 "No Request" 1 "Request";
VAL_ 1258 LeftTurnLampControlReq 0 "No Request" 1 "LeftTurnLamp On" 2 "LeftTurnLamp Off" 3 "Reserved";
VAL_ 1258 RightTurnLampControlReq 0 "No Request" 1 "rightTurnLamp On" 2 "rightTurnLamp Off" 3 "Reserved";
VAL_ 1258 HazardWarningLampReq 0 "No Request" 1 "Hazard SW On(RCW, 4Hz)" 2 "Hazard SW On(Normal double flash frequency）" 3 "Reserved";
VAL_ 1258 BeamControlReq 0 "No Request" 1 "LowBeam ON" 2 "HighBeam ON" 3 "failure";
VAL_ 1258 AD_Ext_Rear_Mirror_Folding_Req 0 "No Request" 1 "Request to Fold" 2 "Request to Unfold" 3 "Reserved";
VAL_ 1258 FrWipReq 0 "no request" 1 "off" 2 "auto" 3 "low" 4 "high" 5 "mist" 6 "repair mode" 7 "reserved";
VAL_ 1258 Heat_request 0 "No request" 1 "request" 2 "reserved" 3 "reserved";
VAL_ 1258 BSWLamp_L_Request 0 "HMI LED off" 1 "HMI LED blink" 2 "Not used" 3 "HMI LED continuously on";
VAL_ 1258 BSWLamp_R_Request 0 "HMI LED off" 1 "HMI LED blink" 2 "Not used" 3 "HMI LED continuously on";
VAL_ 1258 ADCU_RefuseToSleep 0 "reserved" 1 "ADCU refuse to sleep" 2 "ADCU ready to sleep" 3 "reserved";
VAL_ 1258 ADLowPwrSts 0 "LowPowerStatus OFF" 1 "LowPowerStatus ON" 2 "power on/off ongoing" 3 "abnormal";
VAL_ 1258 RdytoLoPwr 0 "Ready" 1 "Not Ready";
VAL_ 1293 BAT_RQ 0 "off" 1 "flashing" 2 "on" 3 "off";
VAL_ 861 GADE 0 "Sleep or Crank fault, Disable DiagMuxDTC" 1 "AutoACC fault, Disable DiagMuxDTC" 2 "ALL fault, Disable DiagMuxDTC" 3 "ALL fault, Enable DiagMuxDTC" 4 "FOTA switch fault, Disable DiagMuxDTC" 5 "Not used" 6 "Not used" 7 "Unavailable";
VAL_ 861 BCM_WakeUpSleepCmd 0 "Go to Sleep" 1 "reserved" 2 "reserved" 3 "WakeUp";
VAL_ 861 PwrSavModeMask 0 "NoMASK" 1 "MASK";
VAL_ 861 CABRESW 0 "brake not activated" 1 "brake activated" 2 "Reserved" 3 "invalid";
VAL_ 861 Rv_La_Con_St 0 "Reverse Lamp Off" 1 "Reverse Lamp On";
VAL_ 861 FR_WIP_REQ 0 "front wiper in stop position" 1 "front wiper forced to stop" 2 "one low speed wiping requested" 3 "one high speed wiping requested" 4 "invalid" 5 "invalid" 6 "low speed wiping requested" 7 "high speed wiping requested";
VAL_ 536 PEPS_POWER_MODE 0 "OFF" 1 "ACC" 2 "IGN" 3 "Reserved" 4 "READY" 5 "Reserved" 6 "Reserved";
VAL_ 1549 DOOR_SW 0 "(Boot,RR,RL,FR,FL" 1 "(Boot,RR,RL,FR,FL" 2 "(Boot,RR,RL,FR,FL" 3 "(Boot,RR,RL,FR,FL" 4 "(Boot,RR,RL,FR,FL" 5 "(Boot,RR,RL,FR,FL" 6 "(Boot,RR,RL,FR,FL" 7 "(Boot,RR,RL,FR,FL" 8 "(Boot,RR,RL,FR,FL" 9 "(Boot,RR,RL,FR,FL" 10 "(Boot,RR,RL,FR,FL" 11 "(Boot,RR,RL,FR,FL" 12 "(Boot,RR,RL,FR,FL" 13 "(Boot,RR,RL,FR,FL" 14 "(Boot,RR,RL,FR,FL" 15 "(Boot,RR,RL,FR,FL" 16 "(Boot,RR,RL,FR,FL" 17 "(Boot,RR,RL,FR,FL" 18 "(Boot,RR,RL,FR,FL" 19 "(Boot,RR,RL,FR,FL" 20 "(Boot,RR,RL,FR,FL" 21 "(Boot,RR,RL,FR,FL" 22 "(Boot,RR,RL,FR,FL" 23 "(Boot,RR,RL,FR,FL" 24 "(Boot,RR,RL,FR,FL" 25 "(Boot,RR,RL,FR,FL" 26 "(Boot,RR,RL,FR,FL" 27 "(Boot,RR,RL,FR,FL" 28 "(Boot,RR,RL,FR,FL" 29 "(Boot,RR,RL,FR,FL" 30 "(Boot,RR,RL,FR,FL" 31 "(Boot,RR,RL,FR,FL";
VAL_ 1549 TURN_IND 0 "left and right flashing indicators OFF" 1 "left flashing indicator ON and right flashing indicator OFF" 2 "left flashing indicator OFF and right flashing indicator ON" 3 "left flashing indicator ON and right flashing indicator ON" 4 "invalid value" 5 "invalid value" 6 "invalid value" 7 "invalid value";
VAL_ 1549 IGN_SW 0 "Primary ignition supply off" 1 "Primary ignition supply on";
VAL_ 1549 ACC_SW 0 "accessory supply off" 1 "accessory supply on";
VAL_ 1549 DOOR_LOCK 0 "(Doors,Boot" 1 "(Doors,Boot" 2 "(Doors,Boot" 3 "(Doors,Boot";
VAL_ 1549 RR_FOG_L 0 "rear fog light off" 1 "rear fog light on";
VAL_ 1549 ADLowPwrReq 0 "NoRequest" 1 "RequestToShutDown" 2 "RequestToStartUp" 3 "abnormal";
VAL_ 1573 HL_LOW 0 "low beam off" 1 "low beam on";
VAL_ 1573 HL_HIGH 0 "high beam off" 1 "high beam on";
VAL_ 1573 TAIL_L 0 "position lights off" 1 "position lights on";
VAL_ 1573 VehicleState 0 "Sleeping(ACC OFF)" 1 "Not used" 2 "CutoffPending(ACC OFF)" 3 "AutoACC  - BatTempoLevel" 4 "Not used" 5 "IgnitionLevel(IGN ON)" 6 "StartingInProgress" 7 "PowertrainRunning(ready)" 8 "AutoStart" 9 "EngineSystemStop" 10 "Not used" 11 "Not used" 12 "Not used" 13 "Not used" 14 "Not used" 15 "Unavailable";
VAL_ 1573 Hood_SW 0 "hood SW off" 1 "hood SW on";
VAL_ 1532 HighLampChangeSWSts 0 "not pressed" 1 "pressed" 2 "reserved" 3 "Invalid";
VAL_ 1532 TurnLampSWSts 0 "not pressed" 1 "TurnChangeLeft" 2 "TurnChangeRight" 3 "TurnAroundLeft" 4 "TurnAroundRight" 5 "Not used" 6 "Not used" 7 "Invalid";
VAL_ 1480 SW_PILOTorCANCEL 0 "Released" 1 "Pressed" 2 "Error (Stuck)" 3 "Error (Switch I/O)";
VAL_ 1480 SW_DISTANCEorASCD 0 "Released" 1 "Pressed" 2 "Error (Stuck)" 3 "Error (Switch I/O)";
VAL_ 1480 SW_DistanceReduce 0 "Released" 1 "Pressed" 2 "Error (Stuck)" 3 "Error (Switch I/O)";
VAL_ 1480 SW_SET 0 "not move" 1 "down move,1 gears." 2 "down move,2 gears." 3 "down move,3 gears." 4 "down move,4 gears." 5 "down move,5 gears." 6 "down move,6 gears." 7 "down move,7 gears." 8 "down move,8 gears." 9 "down move,9 gears." 10 "down move,10 gears." 11 "down move,11 gears." 12 "down move,12 gears." 13 "down move,13 gears." 14 "down move,14 gears." 15 "down move,15 gears.";
VAL_ 1480 SW_RES 0 "not move" 1 "up move,1 gears." 2 "up move,2 gears." 3 "up move,3 gears." 4 "up move,4 gears." 5 "up move,5 gears." 6 "up move,6 gears." 7 "up move,7 gears." 8 "up move,8 gears." 9 "up move,9 gears." 10 "up move,10 gears." 11 "up move,11 gears." 12 "up move,12 gears." 13 "up move,13 gears." 14 "up move,14 gears." 15 "up move,15 gears.";
VAL_ 1480 SW_CUSTOM 0 "Released" 1 "Pressed" 2 "Error (Stuck)" 3 "Error (Switch I/O)";
VAL_ 1480 SW_LEFT 0 "Released" 1 "Pressed" 2 "Error (Stuck)" 3 "Error (Switch I/O)";
VAL_ 1480 SW_RIGHT 0 "Released" 1 "Pressed" 2 "Error (Stuck)" 3 "Error (Switch I/O)";
VAL_ 1480 SW_OK 0 "Released" 1 "Pressed" 2 "Error (Stuck)" 3 "Error (Switch I/O)";
VAL_ 1480 DrvrSeatOccupSts 0 "Not Occupant" 1 "Occupant" 2 "Broken circuit" 3 "Short circuit";
VAL_ 901 LTP_FR 0 "Normal" 1 "Low tire pressure";
VAL_ 901 LTP_FL 0 "Normal" 1 "Low tire pressure";
VAL_ 901 LTP_RR 0 "Normal" 1 "Low tire pressure";
VAL_ 901 LTP_RL 0 "Normal" 1 "Low tire pressure";
VAL_ 858 DR_Win_St 0 "window position at lv. 1 full open" 1 "window position at lv. 2" 2 "window position at lv. 3" 3 "window position at lv. 4" 4 "window position at lv. 5" 5 "window position at lv. 6" 6 "window position at lv. 7" 7 "window position at lv. 8" 8 "window position at lv. 9" 9 "window position at lv. 10" 10 "window position at lv. 11 full close" 11 "invalid" 12 "invalid" 13 "invalid" 14 "invalid" 15 "unknown position";
VAL_ 858 AS_Win_St 0 "window position at lv. 1 full open" 1 "window position at lv. 2" 2 "window position at lv. 3" 3 "window position at lv. 4" 4 "window position at lv. 5" 5 "window position at lv. 6" 6 "window position at lv. 7" 7 "window position at lv. 8" 8 "window position at lv. 9" 9 "window position at lv. 10" 10 "window position at lv. 11 full close" 11 "invalid" 12 "invalid" 13 "invalid" 14 "invalid" 15 "unknown position";
VAL_ 858 RL_Win_St 0 "window position at lv. 1 full open" 1 "window position at lv. 2" 2 "window position at lv. 3" 3 "window position at lv. 4" 4 "window position at lv. 5" 5 "window position at lv. 6" 6 "window position at lv. 7" 7 "window position at lv. 8" 8 "window position at lv. 9" 9 "window position at lv. 10" 10 "window position at lv. 11 full close" 11 "invalid" 12 "invalid" 13 "invalid" 14 "invalid" 15 "unknown position";
VAL_ 858 RR_Win_St 0 "window position at lv. 1 full open" 1 "window position at lv. 2" 2 "window position at lv. 3" 3 "window position at lv. 4" 4 "window position at lv. 5" 5 "window position at lv. 6" 6 "window position at lv. 7" 7 "window position at lv. 8" 8 "window position at lv. 9" 9 "window position at lv. 10" 10 "window position at lv. 11 full close" 11 "invalid" 12 "invalid" 13 "invalid" 14 "invalid" 15 "unknown position";
VAL_ 1338 FrWipSts 0 "front wiper stopped" 1 "low speed active" 2 "high speed active" 3 "invalid";
VAL_ 1339 LeftBswLedSts 0 "Invalid" 1 "normal" 2 "short-circuit" 3 "open-circuit";
VAL_ 1339 RightBswLedSts 0 "Invalid" 1 "normal" 2 "short-circuit" 3 "open-circuit";
VAL_ 1340 PassSeatOccupSts 0 "Not Occupant" 1 "Occupant" 2 "Broken circuit" 3 "Short circuit";
VAL_ 1340 ExtRMirFldSts 0 "Fold" 1 "Unfold" 2 "reserved" 3 "Invalid";
VAL_ 1342 BcmRainSizeSts 0 "No Rain" 1 "Dizzle Rain" 2 "Small Rain" 3 "Mid Rain" 4 "High Rain" 5 "Reserved" 6 "Reserved";
VAL_ 1343 AirConditionSystemWorking_Status 0 "highlight display ACSysWrkSts OFF" 1 "highlight display ACSysWrkSts ON";
VAL_ 1343 BlwModeSts 0 "Invaild" 1 "Face" 2 "FaceFoot" 3 "Foot" 4 "FootDefrost" 5 "Defrost" 6 "reserved" 7 "reserved";
VAL_ 793 SDM_SecuBltAlrmSts_RL 0 "Lamp Off(Safety Belt Tied)" 1 "Fault(Reserved)" 2 "Lamp On(Safety Belt Not Tied)" 3 "Reserved";
VAL_ 793 SDM_SecuBltAlrmSts_RM 0 "Lamp Off(Safety Belt Tied)" 1 "Fault(Reserved)" 2 "Lamp On(Safety Belt Not Tied)" 3 "Reserved";
VAL_ 793 SDM_SecuBltAlrmSts_RR 0 "Lamp Off(Safety Belt Tied)" 1 "Fault(Reserved)" 2 "Lamp On(Safety Belt Not Tied)" 3 "Reserved";
VAL_ 793 SDM_DrverSecuBltAlrmSts 0 "Lamp Off(Safety Belt Tied)" 1 "Fault(Reserved)" 2 "Lamp On(Safety Belt Not Tied)" 3 "Reserved";
VAL_ 793 SDM_PassSecuBltAlrmSts 0 "Lamp Off(Safety Belt Tied)" 1 "Fault(Reserved)" 2 "Lamp On(Safety Belt Not Tied)" 3 "Reserved";
VAL_ 793 SDM_AirBagSysAlrmLampSts 0 "Lamp Off" 1 "Lamp Flash" 2 "Lamp On" 3 "Reserved";
VAL_ 793 SDM_CllsnSig 0 "No Crash" 1 "Crash";
VAL_ 793 SDM_FrntCllsn 0 "未发生正面碰撞" 1 "发生正面碰撞";
VAL_ 793 SDM_LeSideCllsn 0 "未发生左侧面碰撞" 1 "发生左侧面碰撞";
VAL_ 793 SDM_RiSideCllsn 0 "未发生右侧面碰撞" 1 "发生右侧面碰撞";
VAL_ 793 SDM_ReCllsn 0 "未发生后面碰撞" 1 "发生后面碰撞";
VAL_ 793 SDM_Rollover 0 "未发生翻滚" 1 "发生翻滚";
VAL_ 578 YRS_LatSnsrSts 0 "Initializing" 1 "Valid" 2 "Invalid" 3 "Reserved";
VAL_ 578 YRS_YawRateSnsrSts 0 "Initializing" 1 "Valid" 2 "Invalid" 3 "Reserved";
VAL_ 578 YRS_YawRateCalSts 0 "Sensor Not Calibrated" 1 "Sensor Calibrated";
VAL_ 582 YRS_LgtSnsrSts 0 "Initializing" 1 "Valid" 2 "Invalid" 3 "Reserved";
VAL_ 582 YRS_VertSnsrSts 0 "Initializing" 1 "Valid" 2 "Invalid" 3 "Reserved";
VAL_ 582 YRS_RollrateSnsrSts 0 "Initializing" 1 "Valid" 2 "Invalid" 3 "Reserved";
VAL_ 1383 Year 0 "<value>Year" 1 "<value>Year" 2 "<value>Year" 3 "<value>Year" 4 "<value>Year" 5 "<value>Year" 6 "<value>Year" 7 "<value>Year" 8 "<value>Year" 9 "<value>Year" 10 "<value>Year" 11 "<value>Year" 12 "<value>Year" 13 "<value>Year" 14 "<value>Year" 15 "<value>Year" 16 "<value>Year" 17 "<value>Year" 18 "<value>Year" 19 "<value>Year" 20 "<value>Year" 21 "<value>Year" 22 "<value>Year" 23 "<value>Year" 24 "<value>Year" 25 "<value>Year" 26 "<value>Year" 27 "<value>Year" 28 "<value>Year" 29 "<value>Year" 30 "<value>Year" 31 "<value>Year" 32 "<value>Year" 33 "<value>Year" 34 "<value>Year" 35 "<value>Year" 36 "<value>Year" 37 "<value>Year" 38 "<value>Year" 39 "<value>Year" 40 "<value>Year" 41 "<value>Year" 42 "<value>Year" 43 "<value>Year" 44 "<value>Year" 45 "<value>Year" 46 "<value>Year" 47 "<value>Year" 48 "<value>Year" 49 "<value>Year" 50 "<value>Year" 51 "<value>Year" 52 "<value>Year" 53 "<value>Year" 54 "<value>Year" 55 "<value>Year" 56 "<value>Year" 57 "<value>Year" 58 "<value>Year" 59 "<value>Year" 60 "<value>Year" 61 "<value>Year" 62 "<value>Year" 63 "<value>Year" 64 "<value>Year" 65 "<value>Year" 66 "<value>Year" 67 "<value>Year" 68 "<value>Year" 69 "<value>Year" 70 "<value>Year" 71 "<value>Year" 72 "<value>Year" 73 "<value>Year" 74 "<value>Year" 75 "<value>Year" 76 "<value>Year" 77 "<value>Year" 78 "<value>Year" 79 "<value>Year" 80 "<value>Year" 81 "<value>Year" 82 "<value>Year" 83 "<value>Year" 84 "<value>Year" 85 "<value>Year" 86 "<value>Year" 87 "<value>Year" 88 "<value>Year" 89 "<value>Year" 90 "<value>Year" 91 "<value>Year" 92 "<value>Year" 93 "<value>Year" 94 "<value>Year" 95 "<value>Year" 96 "<value>Year" 97 "<value>Year" 98 "<value>Year" 99 "<value>Year" 100 "<value>Year" 101 "<value>Year" 102 "<value>Year" 103 "<value>Year" 104 "<value>Year" 105 "<value>Year" 106 "<value>Year" 107 "<value>Year" 108 "<value>Year" 109 "<value>Year" 110 "<value>Year" 111 "<value>Year" 112 "<value>Year" 113 "<value>Year" 114 "<value>Year" 115 "<value>Year" 116 "<value>Year" 117 "<value>Year" 118 "<value>Year" 119 "<value>Year" 120 "<value>Year" 121 "<value>Year" 122 "<value>Year" 123 "<value>Year" 124 "<value>Year" 125 "<value>Year" 126 "<value>Year" 127 "<value>Year" 128 "<value>Year" 129 "<value>Year" 130 "<value>Year" 131 "<value>Year" 132 "<value>Year" 133 "<value>Year" 134 "<value>Year" 135 "<value>Year" 136 "<value>Year" 137 "<value>Year" 138 "<value>Year" 139 "<value>Year" 140 "<value>Year" 141 "<value>Year" 142 "<value>Year" 143 "<value>Year" 144 "<value>Year" 145 "<value>Year" 146 "<value>Year" 147 "<value>Year" 148 "<value>Year" 149 "<value>Year" 150 "<value>Year" 151 "<value>Year" 152 "<value>Year" 153 "<value>Year" 154 "<value>Year" 155 "<value>Year" 156 "<value>Year" 157 "<value>Year" 158 "<value>Year" 159 "<value>Year" 160 "<value>Year" 161 "<value>Year" 162 "<value>Year" 163 "<value>Year" 164 "<value>Year" 165 "<value>Year" 166 "<value>Year" 167 "<value>Year" 168 "<value>Year" 169 "<value>Year" 170 "<value>Year" 171 "<value>Year" 172 "<value>Year" 173 "<value>Year" 174 "<value>Year" 175 "<value>Year" 176 "<value>Year" 177 "<value>Year" 178 "<value>Year" 179 "<value>Year" 180 "<value>Year" 181 "<value>Year" 182 "<value>Year" 183 "<value>Year" 184 "<value>Year" 185 "<value>Year" 186 "<value>Year" 187 "<value>Year" 188 "<value>Year" 189 "<value>Year" 190 "<value>Year" 191 "<value>Year" 192 "<value>Year" 193 "<value>Year" 194 "<value>Year" 195 "<value>Year" 196 "<value>Year" 197 "<value>Year" 198 "<value>Year" 199 "<value>Year" 200 "<value>Year" 201 "<value>Year" 202 "<value>Year" 203 "<value>Year" 204 "<value>Year" 205 "<value>Year" 206 "<value>Year" 207 "<value>Year" 208 "<value>Year" 209 "<value>Year" 210 "<value>Year" 211 "<value>Year" 212 "<value>Year" 213 "<value>Year" 214 "<value>Year" 215 "<value>Year" 216 "<value>Year" 217 "<value>Year" 218 "<value>Year" 219 "<value>Year" 220 "<value>Year" 221 "<value>Year" 222 "<value>Year" 223 "<value>Year" 224 "<value>Year" 225 "<value>Year" 226 "<value>Year" 227 "<value>Year" 228 "<value>Year" 229 "<value>Year" 230 "<value>Year" 231 "<value>Year" 232 "<value>Year" 233 "<value>Year" 234 "<value>Year" 235 "<value>Year" 236 "<value>Year" 237 "<value>Year" 238 "<value>Year" 239 "<value>Year" 240 "<value>Year" 241 "<value>Year" 242 "<value>Year" 243 "<value>Year" 244 "<value>Year" 245 "<value>Year" 246 "<value>Year" 247 "<value>Year" 248 "<value>Year" 249 "<value>Year" 250 "<value>Year" 251 "<value>Year" 252 "<value>Year" 253 "<value>Year" 254 "<value>Year";
VAL_ 1383 Month 0 "Invalid" 1 "<value>Month" 2 "<value>Month" 3 "<value>Month" 4 "<value>Month" 5 "<value>Month" 6 "<value>Month" 7 "<value>Month" 8 "<value>Month" 9 "<value>Month" 10 "<value>Month" 11 "<value>Month" 13 "Reserved" 14 "Reserved";
VAL_ 1383 Day 0 "Invalid" 1 "<value>Day" 2 "<value>Day" 3 "<value>Day" 4 "<value>Day" 5 "<value>Day" 6 "<value>Day" 7 "<value>Day" 8 "<value>Day" 9 "<value>Day" 10 "<value>Day" 11 "<value>Day" 12 "<value>Day" 13 "<value>Day" 14 "<value>Day" 15 "<value>Day" 16 "<value>Day" 17 "<value>Day" 18 "<value>Day" 19 "<value>Day" 20 "<value>Day" 21 "<value>Day" 22 "<value>Day" 23 "<value>Day" 24 "<value>Day" 25 "<value>Day" 26 "<value>Day" 27 "<value>Day" 28 "<value>Day" 29 "<value>Day" 30 "<value>Day";
VAL_ 1383 Hour 0 "<value>Hour" 1 "<value>Hour" 2 "<value>Hour" 3 "<value>Hour" 4 "<value>Hour" 5 "<value>Hour" 6 "<value>Hour" 7 "<value>Hour" 8 "<value>Hour" 9 "<value>Hour" 10 "<value>Hour" 11 "<value>Hour" 12 "<value>Hour" 13 "<value>Hour" 14 "<value>Hour" 15 "<value>Hour" 16 "<value>Hour" 17 "<value>Hour" 18 "<value>Hour" 19 "<value>Hour" 20 "<value>Hour" 21 "<value>Hour" 22 "<value>Hour" 24 "Invalid" 25 "Invalid" 26 "Invalid" 27 "Invalid" 28 "Invalid" 29 "Invalid" 30 "Invalid";
VAL_ 1383 Minute 0 "<value>Minute" 1 "<value>Minute" 2 "<value>Minute" 3 "<value>Minute" 4 "<value>Minute" 5 "<value>Minute" 6 "<value>Minute" 7 "<value>Minute" 8 "<value>Minute" 9 "<value>Minute" 10 "<value>Minute" 11 "<value>Minute" 12 "<value>Minute" 13 "<value>Minute" 14 "<value>Minute" 15 "<value>Minute" 16 "<value>Minute" 17 "<value>Minute" 18 "<value>Minute" 19 "<value>Minute" 20 "<value>Minute" 21 "<value>Minute" 22 "<value>Minute" 23 "<value>Minute" 24 "<value>Minute" 25 "<value>Minute" 26 "<value>Minute" 27 "<value>Minute" 28 "<value>Minute" 29 "<value>Minute" 30 "<value>Minute" 31 "<value>Minute" 32 "<value>Minute" 33 "<value>Minute" 34 "<value>Minute" 35 "<value>Minute" 36 "<value>Minute" 37 "<value>Minute" 38 "<value>Minute" 39 "<value>Minute" 40 "<value>Minute" 41 "<value>Minute" 42 "<value>Minute" 43 "<value>Minute" 44 "<value>Minute" 45 "<value>Minute" 46 "<value>Minute" 47 "<value>Minute" 48 "<value>Minute" 49 "<value>Minute" 50 "<value>Minute" 51 "<value>Minute" 52 "<value>Minute" 53 "<value>Minute" 54 "<value>Minute" 55 "<value>Minute" 56 "<value>Minute" 57 "<value>Minute" 58 "<value>Minute" 60 "Invalid" 61 "Invalid" 62 "Invalid";
VAL_ 1383 Second 0 "<value>Second" 1 "<value>Second" 2 "<value>Second" 3 "<value>Second" 4 "<value>Second" 5 "<value>Second" 6 "<value>Second" 7 "<value>Second" 8 "<value>Second" 9 "<value>Second" 10 "<value>Second" 11 "<value>Second" 12 "<value>Second" 13 "<value>Second" 14 "<value>Second" 15 "<value>Second" 16 "<value>Second" 17 "<value>Second" 18 "<value>Second" 19 "<value>Second" 20 "<value>Second" 21 "<value>Second" 22 "<value>Second" 23 "<value>Second" 24 "<value>Second" 25 "<value>Second" 26 "<value>Second" 27 "<value>Second" 28 "<value>Second" 29 "<value>Second" 30 "<value>Second" 31 "<value>Second" 32 "<value>Second" 33 "<value>Second" 34 "<value>Second" 35 "<value>Second" 36 "<value>Second" 37 "<value>Second" 38 "<value>Second" 39 "<value>Second" 40 "<value>Second" 41 "<value>Second" 42 "<value>Second" 43 "<value>Second" 44 "<value>Second" 45 "<value>Second" 46 "<value>Second" 47 "<value>Second" 48 "<value>Second" 49 "<value>Second" 50 "<value>Second" 51 "<value>Second" 52 "<value>Second" 53 "<value>Second" 54 "<value>Second" 55 "<value>Second" 56 "<value>Second" 57 "<value>Second" 58 "<value>Second" 60 "Invalid" 61 "Invalid" 62 "Invalid";
VAL_ 1383 Server_time_flag 0 "server time update fail" 1 "server time update success";
VAL_ 1383 GPS_Signal 0 "DA Clock" 1 "GPS Clock";
VAL_ 581 VDCFAIL 0 "no VDC(ESP) malfunction" 1 "VDC(ESP) malfunction";
VAL_ 581 OFF_SW 0 "VDC(ESP) available" 1 "VDC(ESP) disabled by the driver";
VAL_ 682 SIGNAL_SOURCING 0 "no signal" 1 "AEB operation" 2 "EAPM operation" 3 "invalid";
VAL_ 682 AEB_STATUS 0 "AEB not operation" 1 "AEB operation";
VAL_ 682 AEB_ALIVE 0 "abnormal" 1 "normal";
VAL_ 682 EAPM_ENBL 0 "not Enable" 1 "Enable";
VAL_ 682 EAPM_Status 0 "EAPM not operation" 1 "EAPM operation";
VAL_ 682 EAPM_Alive 0 "unavailable" 1 "available";
VAL_ 682 VehicleStandstill 0 "Vehicle is not standstill" 1 "Vehicle is standstill" 2 "Reserved" 3 "Invalid";
VAL_ 852 STPLMSW 0 "brake not active" 1 "brake active" 2 "Not used" 3 "invalid";
VAL_ 576 EPB_STAT 0 "Unknown state" 1 "Applied" 2 "Released" 3 "Applying" 4 "Releasing" 5 "System calibrating" 6 "Specific status" 7 "EPB lamps check";
VAL_ 576 EPB_FAIL 0 "Normal" 1 "Abnormal";
VAL_ 576 DPB_STAT 0 "OFF" 1 "DPB operation by VDC" 2 "DPB operation by electro-caliper" 3 "Not used";
VAL_ 645 WDFL 0 "Standstill" 1 "Drive Wheel Front Direction" 2 "Drive Wheel Rear Direction" 3 "Unavailable";
VAL_ 645 WDFR 0 "Standstill" 1 "Drive Wheel Front Direction" 2 "Drive Wheel Rear Direction" 3 "Unavailable";
VAL_ 645 WDRL 0 "Standstill" 1 "Non Drive Wheel Front Direction" 2 "Non Drive Wheel Rear Direction" 3 "Unavailable";
VAL_ 645 WDRR 0 "Standstill" 1 "Non Drive Wheel Front Direction" 2 "Non Drive Wheel Rear Direction" 3 "Unavailable";
VAL_ 2 LWSTRIM 0 "Unfinish" 1 "Finish";
VAL_ 2 LWSCAL 0 "Unfinish" 1 "Finish";
VAL_ 2 LWSOK 0 "Abnormal" 1 "Normal";
VAL_ 500 PT_MotoSpd 0 "" 1 "" 2 "" 3 "" 4 "" 5 "" 6 "" 7 "" 8 "" 9 "" 10 "" 11 "" 12 "" 13 "" 14 "" 15 "" 16 "" 17 "" 18 "" 19 "" 20 "" 21 "" 22 "" 23 "" 24 "" 25 "" 26 "" 27 "" 28 "" 29 "" 30 "" 31 "" 32 "" 33 "" 34 "" 35 "" 36 "" 37 "" 38 "" 39 "" 40 "" 41 "" 42 "" 43 "" 44 "" 45 "" 46 "" 47 "" 48 "" 49 "" 50 "" 51 "" 52 "" 53 "" 54 "" 55 "" 56 "" 57 "" 58 "" 59 "" 60 "" 61 "" 62 "" 63 "" 64 "" 65 "" 66 "" 67 "" 68 "" 69 "" 70 "" 71 "" 72 "" 73 "" 74 "" 75 "" 76 "" 77 "" 78 "" 79 "" 80 "" 81 "" 82 "" 83 "" 84 "" 85 "" 86 "" 87 "" 88 "" 89 "" 90 "" 91 "" 92 "" 93 "" 94 "" 95 "" 96 "" 97 "" 98 "" 99 "" 100 "" 101 "" 102 "" 103 "" 104 "" 105 "" 106 "" 107 "" 108 "" 109 "" 110 "" 111 "" 112 "" 113 "" 114 "" 115 "" 116 "" 117 "" 118 "" 119 "" 120 "" 121 "" 122 "" 123 "" 124 "" 125 "" 126 "" 127 "" 128 "" 129 "" 130 "" 131 "" 132 "" 133 "" 134 "" 135 "" 136 "" 137 "" 138 "" 139 "" 140 "" 141 "" 142 "" 143 "" 144 "" 145 "" 146 "" 147 "" 148 "" 149 "" 150 "" 151 "" 152 "" 153 "" 154 "" 155 "" 156 "" 157 "" 158 "" 159 "" 160 "" 161 "" 162 "" 163 "" 164 "" 165 "" 166 "" 167 "" 168 "" 169 "" 170 "" 171 "" 172 "" 173 "" 174 "" 175 "" 176 "" 177 "" 178 "" 179 "" 180 "" 181 "" 182 "" 183 "" 184 "" 185 "" 186 "" 187 "" 188 "" 189 "" 190 "" 191 "" 192 "" 193 "" 194 "" 195 "" 196 "" 197 "" 198 "" 199 "" 200 "" 201 "" 202 "" 203 "" 204 "" 205 "" 206 "" 207 "" 208 "" 209 "" 210 "" 211 "" 212 "" 213 "" 214 "" 215 "" 216 "" 217 "" 218 "" 219 "" 220 "" 221 "" 222 "" 223 "" 224 "" 225 "" 226 "" 227 "" 228 "" 229 "" 230 "" 231 "" 232 "" 233 "" 234 "" 235 "" 236 "" 237 "" 238 "" 239 "" 240 "" 241 "" 242 "" 243 "" 244 "" 245 "" 246 "" 247 "" 248 "" 249 "" 250 "" 251 "" 252 "" 253 "" 254 "" 255 "";
VAL_ 500 PT_MotoSpdV 0 "Invalid" 1 "Valid";
VAL_ 502 PT_AccelPadelPos 0 "" 1 "" 2 "" 3 "";
VAL_ 502 PT_AccelPadelPosV 0 "Invalid" 1 "Valid";
VAL_ 502 IND_RNG 0 "OFF" 1 "P range" 2 "R range" 3 "N range" 4 "D range" 5 "Reserved" 6 "Reserved" 7 "Reserved" 8 "Reserved" 9 "Reserved" 10 "Reserved" 11 "Reserved" 12 "Reserved" 13 "Reserved" 14 "Reserved" 15 "Reserved" 16 "Reserved" 17 "Reserved" 18 "Reserved" 19 "Reserved" 20 "Reserved" 21 "Reserved" 22 "Reserved" 23 "Reserved" 24 "Reserved" 25 "Reserved" 26 "Reserved" 27 "Reserved" 28 "Reserved" 29 "Reserved" 30 "Reserved";
VAL_ 384 ETCFAIL 0 "normal" 1 "Not used" 2 "Not used" 3 "torque request cant be achieved";
VAL_ 1361 ENG_STA 0 "engine stopped" 1 "engine stalled" 2 "engine running（EV vehicle ready）" 3 "engine cranking";
VAL_ 689 AD_take_over_request 0 "NO Request" 1 "AD Error, take over request" 2 "Fail to main road, take over please" 3 "Reserve" 4 "Reserve" 5 "Reserve" 6 "Reserve" 7 "Reserve" 8 "Reserve" 9 "Reserve" 10 "Reserve" 11 "Reserve" 12 "Reserve" 13 "Reserve" 14 "Reserve" 15 "Reserve" 16 "Reserve" 17 "Reserve" 18 "Reserve" 19 "Reserve" 20 "Reserve" 21 "Reserve" 22 "Reserve" 23 "Reserve" 24 "Reserve" 25 "Reserve" 26 "Reserve" 27 "Reserve" 28 "Reserve" 29 "Reserve" 30 "Reserve" 31 "Reserve" 32 "Reserve" 33 "Reserve" 34 "Reserve" 35 "Reserve" 36 "Reserve" 37 "Reserve" 38 "Reserve" 39 "Reserve" 40 "Reserve" 41 "Reserve" 42 "Reserve" 43 "Reserve" 44 "Reserve" 45 "Reserve" 46 "Reserve" 47 "Reserve" 48 "Reserve" 49 "Reserve" 50 "Reserve" 51 "Reserve" 52 "Reserve" 53 "Reserve" 54 "Reserve" 55 "Reserve" 56 "Reserve" 57 "Reserve" 58 "Reserve" 59 "Reserve" 60 "Reserve" 61 "Reserve" 62 "Reserve";
VAL_ 689 HodMeterLampRequest 0 "no request" 1 "request";
VAL_ 689 ISLS_Limit_Speed_Value 0 "NoDisplay" 1 "SpeedLim130" 2 "SpeedLim125" 3 "SpeedLim120" 4 "SpeedLim115" 5 "SpeedLim110" 6 "SpeedLim105" 7 "SpeedLim100" 8 "SpeedLim95" 9 "SpeedLim90" 10 "SpeedLim85" 11 "SpeedLim80" 12 "SpeedLim75" 13 "SpeedLim70" 14 "SpeedLim65" 15 "SpeedLim60" 16 "SpeedLim55" 17 "SpeedLim50" 18 "SpeedLim45" 19 "SpeedLim40" 20 "SpeedLim35" 21 "SpeedLim30" 22 "SpeedLim25" 23 "SpeedLim20" 24 "SpeedLim15" 25 "SpeedLim10" 26 "SpeedLim5" 27 "SpeedLim120_Interval" 28 "SpeedLim115_Interval" 29 "SpeedLim110_Interval" 30 "SpeedLim105_Interval" 31 "SpeedLim100_Interval" 32 "SpeedLim95_Interval" 33 "SpeedLim90_Interval" 34 "SpeedLim85_Interval" 35 "SpeedLim80_Interval" 36 "SpeedLim75_Interval" 37 "SpeedLim70_Interval" 38 "SpeedLim65_Interval" 39 "SpeedLim60_Interval" 40 "SpeedLim55_Interval" 41 "SpeedLim45_Interval" 42 "SpeedLim40_Interval" 43 "SpeedLim35_Interval" 44 "SpeedLim30_Interval" 45 "SpeedLim25_Interval" 46 "SpeedLim20_Interval" 47 "SpeedLim15_Interval" 48 "SpeedLim10_Interval" 49 "SpeedLim5_Interval" 50 "MinSpeedLim120" 51 "MinSpeedLim110" 52 "MinSpeedLim100" 53 "MinSpeedLim90" 54 "MinSpeedLim80" 55 "MinSpeedLim70" 56 "MinSpeedLim60" 57 "MinSpeedLim50" 58 "SpeedLim_Cancelled" 59 "Reserve" 60 "Reserve" 61 "Reserve" 62 "Reserve" 63 "SpeedLim65";
VAL_ 689 SLIF_Limit_Speed_Validation 0 "Reverse" 1 "InValid" 2 "Valid" 3 "Reserve";
VAL_ 689 SLIF_Limit_Speed_Unit 0 "Km/h" 1 "mph" 2 "m/s" 3 "Reserve";
VAL_ 689 ISLS_Acoustic_Warning 0 "NoWarning" 1 "Warning" 2 "Reserve";
VAL_ 689 Hand_Off_Status 0 "Hands on" 1 "Hands off-light" 2 "Hands off-medium" 3 "Hands off-heavy" 4 "error" 5 "Reserve" 6 "Reserve";
VAL_ 689 AVM_Front_Cam_Video_State 0 "no video output with normally" 1 "video output with normally" 2 "video output with abnormally" 3 "not used";
VAL_ 689 AVM_Rear_Cam_Video_State 0 "no video output with normally" 1 "video output with normally" 2 "video output with abnormally" 3 "not used";
VAL_ 689 AVM_Left_Cam_Video_State 0 "no video output with normally" 1 "video output with normally" 2 "video output with abnormally" 3 "not used";
VAL_ 689 AVM_Right_Cam_Video_State 0 "no video output with normally" 1 "video output with normally" 2 "video output with abnormally" 3 "not used";
VAL_ 695 PCW_PreWarning 0 "Deactive" 1 "Active";
VAL_ 695 AEB_Active 0 "Deactive" 1 "Active";
VAL_ 695 CDW_Active 0 "Deactive" 1 "Active";
VAL_ 695 ESS_Active 0 "Deactive" 1 "LeftActive" 2 "RightActive" 3 "Reserved";
VAL_ 695 fcta_left_warning 0 "Deactive" 1 "Active";
VAL_ 695 fcta_front_warning 0 "Deactive" 1 "Active";
VAL_ 695 fcta_right_warning 0 "Deactive" 1 "Active";
VAL_ 695 fctb_left_warning 0 "Deactive" 1 "Active";
VAL_ 695 fctb_front_warning 0 "Deactive" 1 "Active";
VAL_ 695 fctb_right_warning 0 "Deactive" 1 "Active";
VAL_ 695 rctb_left_warning 0 "Deactive" 1 "Active";
VAL_ 695 rctb_rear_warning 0 "Deactive" 1 "Active";
VAL_ 695 rctb_right_warning 0 "Deactive" 1 "Active";
VAL_ 695 ELK_active 0 "no active ；" 1 "left road edge；" 2 "right road edge;" 3 "left-overtaking;" 4 "right-overtaking;" 5 "left -oncoming;" 6 "Reserve";
VAL_ 695 rcta_left_warning 0 "Deactive" 1 "Active";
VAL_ 695 rcta_rear_warning 0 "Deactive" 1 "Active";
VAL_ 695 rcta_right_warning 0 "Deactive" 1 "Active";
VAL_ 695 rcw_warning 0 "Deactive" 1 "Active";
VAL_ 695 left_bsw_warning 0 "No Warning" 1 "Left Warning Level 1" 2 "Left Warning Level 2" 3 "Reserve";
VAL_ 695 right_bsw_warning 0 "No Warning" 1 "Right Warning Level 1" 2 "Right Warning Level 2" 3 "Reserve";
VAL_ 695 left_dow_warning 0 "No Warning" 1 "Left Warning Level 1" 2 "Left Warning Level 2" 3 "Reserve";
VAL_ 695 right_dow_warning 0 "No Warning" 1 "Right Warning Level 1" 2 "Right Warning Level 2" 3 "Reserve";
VAL_ 695 LDW_Warning 0 "No Warning" 1 "left Warning" 2 "Right Warning" 3 "Reserve";
VAL_ 695 LDP_Active 0 "Deactive" 1 "left Active" 2 "Right Active" 3 "Reserve";
VAL_ 695 STS_D_MEB 0 "MEB OFF" 1 "MEB_Self diagnositic or Stand By" 2 "MEB ON_Activate" 3 "MEB ON (Alarm)" 4 "MEB Temporary OFF" 5 "MEB Malfunction" 6 "Reserve" 7 "ESP close";
VAL_ 695 SET_MEB 0 "No setting" 1 "Setting OFF" 2 "Setting ON" 3 "Not Used";
VAL_ 695 STS_W_MEB 0 "No Display" 1 "Display (System ON)" 2 "Display (MEB Temporary OFF)" 3 "Display (MEB Malfunction)";
VAL_ 695 SOUND_MEB 0 "No Beep request" 1 "Beep request";
VAL_ 1260 ACC_HEADW_SET 0 "No display" 1 "Level 1" 2 "Level 2" 3 "Level 3" 4 "Level 4" 5 "Level 5" 6 "reserved";
VAL_ 1260 VDC_NOT_ACTIVATED 0 "No Warning(VDC ON)" 1 "Warning(VDC OFF)";
VAL_ 1260 ACC_DrSeSp 0 "" 1 "" 2 "" 3 "" 4 "" 5 "" 6 "" 7 "" 8 "" 9 "" 10 "" 11 "" 12 "" 13 "" 14 "" 15 "" 16 "" 17 "" 18 "" 19 "" 20 "" 21 "" 22 "" 23 "" 24 "" 25 "" 26 "" 27 "" 28 "" 29 "" 30 "" 31 "" 32 "" 33 "" 34 "" 35 "" 36 "" 37 "" 38 "" 39 "" 40 "" 41 "" 42 "" 43 "" 44 "" 45 "" 46 "" 47 "" 48 "" 49 "" 50 "" 51 "" 52 "" 53 "" 54 "" 55 "" 56 "" 57 "" 58 "" 59 "" 60 "" 61 "" 62 "" 63 "" 64 "" 65 "" 66 "" 67 "" 68 "" 69 "" 70 "" 71 "" 72 "" 73 "" 74 "" 75 "" 76 "" 77 "" 78 "" 79 "" 80 "" 81 "" 82 "" 83 "" 84 "" 85 "" 86 "" 87 "" 88 "" 89 "" 90 "" 91 "" 92 "" 93 "" 94 "" 95 "" 96 "" 97 "" 98 "" 99 "" 100 "" 101 "" 102 "" 103 "" 104 "" 105 "" 106 "" 107 "" 108 "" 109 "" 110 "" 111 "" 112 "" 113 "" 114 "" 115 "" 116 "" 117 "" 118 "" 119 "" 120 "" 121 "" 122 "" 123 "" 124 "" 125 "" 126 "" 127 "" 128 "" 129 "" 130 "" 131 "" 132 "" 133 "" 134 "" 135 "" 136 "" 137 "" 138 "" 139 "" 140 "" 141 "" 142 "" 143 "" 144 "" 145 "" 146 "" 147 "" 148 "" 149 "" 150 "" 151 "" 152 "" 153 "" 154 "" 155 "" 156 "" 157 "" 158 "" 159 "" 160 "" 161 "" 162 "" 163 "" 164 "" 165 "" 166 "" 167 "" 168 "" 169 "" 170 "" 171 "" 172 "" 173 "" 174 "" 175 "" 176 "" 177 "" 178 "" 179 "" 180 "" 181 "" 182 "" 183 "" 184 "" 185 "" 186 "" 187 "" 188 "" 189 "" 190 "" 191 "" 192 "" 193 "" 194 "" 195 "" 196 "" 197 "" 198 "" 199 "" 200 "" 201 "" 202 "" 203 "" 204 "" 205 "" 206 "" 207 "" 208 "" 209 "" 210 "" 211 "" 212 "" 213 "" 214 "" 215 "" 216 "" 217 "" 218 "" 219 "" 220 "" 221 "" 222 "" 223 "" 224 "" 225 "" 226 "" 227 "" 228 "" 229 "" 230 "" 231 "" 232 "" 233 "" 234 "" 235 "" 236 "" 237 "" 238 "" 239 "" 240 "" 241 "" 242 "" 243 "" 244 "" 245 "" 246 "" 247 "" 248 "" 249 "" 250 "" 251 "" 252 "" 253 "" 254 "" 255 "";
VAL_ 1260 ACC_DisToTgt 0 "" 1 "" 2 "" 3 "" 4 "" 5 "" 6 "" 7 "" 8 "" 9 "" 10 "" 11 "" 12 "" 13 "" 14 "" 15 "" 16 "" 17 "" 18 "" 19 "" 20 "" 21 "" 22 "" 23 "" 24 "" 25 "" 26 "" 27 "" 28 "" 29 "" 30 "" 31 "" 32 "" 33 "" 34 "" 35 "" 36 "" 37 "" 38 "" 39 "" 40 "" 41 "" 42 "" 43 "" 44 "" 45 "" 46 "" 47 "" 48 "" 49 "" 50 "" 51 "" 52 "" 53 "" 54 "" 55 "" 56 "" 57 "" 58 "" 59 "" 60 "" 61 "" 62 "" 63 "" 64 "" 65 "" 66 "" 67 "" 68 "" 69 "" 70 "" 71 "" 72 "" 73 "" 74 "" 75 "" 76 "" 77 "" 78 "" 79 "" 80 "" 81 "" 82 "" 83 "" 84 "" 85 "" 86 "" 87 "" 88 "" 89 "" 90 "" 91 "" 92 "" 93 "" 94 "" 95 "" 96 "" 97 "" 98 "" 99 "" 100 "" 101 "" 102 "" 103 "" 104 "" 105 "" 106 "" 107 "" 108 "" 109 "" 110 "" 111 "" 112 "" 113 "" 114 "" 115 "" 116 "" 117 "" 118 "" 119 "" 120 "" 121 "" 122 "" 123 "" 124 "" 125 "" 126 "" 127 "" 128 "" 129 "" 130 "" 131 "" 132 "" 133 "" 134 "" 135 "" 136 "" 137 "" 138 "" 139 "" 140 "" 141 "" 142 "" 143 "" 144 "" 145 "" 146 "" 147 "" 148 "" 149 "" 150 "" 151 "" 152 "" 153 "" 154 "" 155 "" 156 "" 157 "" 158 "" 159 "" 160 "" 161 "" 162 "" 163 "" 164 "" 165 "" 166 "" 167 "" 168 "" 169 "" 170 "" 171 "" 172 "" 173 "" 174 "" 175 "" 176 "" 177 "" 178 "" 179 "" 180 "" 181 "" 182 "" 183 "" 184 "" 185 "" 186 "" 187 "" 188 "" 189 "" 190 "" 191 "" 192 "" 193 "" 194 "" 195 "" 196 "" 197 "" 198 "" 199 "" 200 "" 201 "" 202 "" 203 "" 204 "" 205 "" 206 "" 207 "" 208 "" 209 "" 210 "" 211 "" 212 "" 213 "" 214 "" 215 "" 216 "" 217 "" 218 "" 219 "" 220 "" 221 "" 222 "" 223 "" 224 "" 225 "" 226 "" 227 "" 228 "" 229 "" 230 "" 231 "" 232 "" 233 "" 234 "" 235 "" 236 "" 237 "" 238 "" 239 "" 240 "" 241 "" 242 "" 243 "" 244 "" 245 "" 246 "" 247 "" 248 "" 249 "" 250 "" 251 "" 252 "" 253 "" 254 "" 255 "";
VAL_ 1260 ACC_TgtDet 0 "False" 1 "True";
VAL_ 1260 ACC_GoNoti 0 "False;" 1 "True;";
VAL_ 1260 CP_Status 0 "OFF" 1 "Passive" 2 "ACC Standby" 3 "CP Standby" 4 "Reserve" 5 "ACC Active" 6 "CP Active" 7 "Standstill_Active" 8 "Standstill_Wait" 9 "Override,A Pedal" 10 "CP Override，Steering,Reserve" 11 "temporary error" 12 "Permanent error" 13 "BOM" 14 "Reserve" 15 "Reserve";
VAL_ 1260 MSG_ILC_Opera 0 "No ILC operation" 1 "ILC operation to left" 2 "ILC operation to right" 3 "Reserve";
VAL_ 1260 CP_PLC_Status 0 "OFF" 1 "Waiting to change lane" 2 "lane change cancel by driver" 3 "Lane change cancel for waiting too long" 4 "changing lane" 5 "Reserve" 6 "lane change back,failure" 7 "lane change sucessfully" 8 "Reserve" 11 "Reserve" 12 "Reserve" 13 "Reserve" 14 "Reserve" 15 "Reserve";
VAL_ 1260 CP_PLC_Direction 0 "NO Acitve" 1 "Left" 2 "Right" 3 "Reserve";
VAL_ 1260 Message_AD_unActive_Reason 0 "No Warning" 1 "Door on" 2 "Driver_Seat_Belt_Unwear" 3 "EPB_ Applied" 4 "Brake_Pedal_ Depressed" 5 "Not_D_Range" 6 "Out_Setting_Speed" 7 "Out_Steering_Angle" 8 "External_Rearview_Mirror_UnFolding_Request" 9 "Please open AEB Button" 10 "Disincentive Measures,Reserved" 11 "Reserve" 12 "Reserve" 13 "Reserve" 14 "Reserve";
VAL_ 1260 ACC_Status 0 "OFF" 1 "ACC Passive" 2 "ACC Standby" 3 "ACC Active" 4 "ACC Standstill_Active" 5 "ACC Standstill_Wait" 6 "ACC Override,A Pedal" 7 "ACC Permanent error" 8 "ACC temporary error" 9 "BOM" 10 "Reserve" 11 "Reserve" 12 "Reserve" 13 "Reserve" 14 "Reserve" 15 "Reserve";
VAL_ 1260 AD_Notice_Information 0 "No Request" 1 "ACC Active" 2 "ACC Quits" 3 "Set Speed reach upper limit" 4 "Construction zone speed limit" 5 "wait too long, step on the gas" 6 "CP Active" 7 "CP Quits" 8 "Upgrade to CP" 9 "Downgrade to ACC" 10 "Update SLIF Speed" 11 "Exceeding ODD Speed" 12 "Reserve" 13 "Reserve" 14 "Reserve" 15 "Reserve" 16 "Reserve" 17 "Reserve" 18 "Reserve" 19 "Reserve" 20 "Reserve" 21 "Reserve" 22 "Reserve" 23 "Reserve" 24 "Reserve" 25 "Reserve" 26 "Reserve" 27 "Reserve" 28 "Reserve" 29 "Reserve" 30 "Reserve" 32 "Lane change begin to left" 33 "Lane change begin to right" 34 "Reserved" 35 "Reserved" 36 "Lane changing to left" 37 "Lane changing to right" 38 "Lane change cancel for waiting too long" 39 "lane change cancel by driver" 40 "Lane change back, failure" 41 "Lane change cancel failure" 42 "Lane change successfully" 43 "Cannot lane change due to speed reason" 44 "Lane change wait due to solid line" 45 "Lane change wait due to obstacle" 46 "SALC  failure to active" 47 "Reserve" 48 "Reserve" 49 "Reserve" 50 "Reserve" 51 "Reserve" 52 "Reserve" 53 "Reserve" 54 "Reserve" 55 "Reserve" 56 "Reserve" 57 "Reserve" 58 "Reserve" 59 "Reserve" 60 "Reserve" 61 "Reserve" 62 "Reserve" 64 "HNP is actived" 65 "HNP is updated" 66 "Please confirm HNPlane change" 67 "Brake and stop" 68 "HNP quits" 69 "HNP to CP" 70 "200m last quit HNP soon" 71 "Left lane change to ramp" 72 "Right lane change to ramp" 73 "Left lane change to main road" 74 "Right lane change to main road" 75 "Left lane change to overtake" 76 "Right lane change to overtake" 77 "Set Speed reach upper limit（NP in city is 85km/h）" 78 "Vehicle starting at green light" 79 "Vehicle starting(at an intersection without traffic lights)" 80 "Go straight at the junction ahead" 81 "Turn right at the junction ahead" 82 "Turn left at the junction ahead" 83 "U-turn at the junction ahead" 84 "Pass through roundabout ahead" 85 "Pass through the toll booth ahead" 86 "Pass through the tunnel ahead" 87 "reserve" 88 "reserve" 89 "reserve" 90 "reserve" 91 "reserve" 92 "reserve" 93 "reserve" 94 "reserve" 95 "reserve" 96 "reserve" 97 "reserve" 98 "reserve" 99 "reserve" 100 "reserve" 101 "reserve" 102 "reserve" 103 "reserve" 104 "reserve" 105 "reserve" 106 "reserve" 107 "reserve" 108 "reserve" 109 "reserve" 110 "reserve" 111 "reserve" 112 "reserve" 113 "reserve" 114 "reserve" 115 "reserve" 116 "reserve" 117 "reserve" 118 "reserve" 119 "reserve" 120 "reserve" 121 "reserve" 122 "reserve" 123 "reserve" 124 "reserve" 125 "reserve" 126 "reserve" 127 "reserve" 128 "reserve" 129 "reserve" 130 "reserve" 131 "reserve" 132 "reserve" 133 "reserve" 134 "reserve" 135 "reserve" 136 "reserve" 137 "reserve" 138 "reserve" 139 "reserve" 140 "reserve" 141 "reserve" 142 "reserve" 143 "reserve" 144 "reserve" 145 "reserve" 146 "reserve" 147 "reserve" 148 "reserve" 149 "reserve" 150 "reserve" 151 "reserve" 152 "reserve" 153 "reserve" 154 "reserve" 155 "reserve" 156 "reserve" 157 "reserve" 158 "reserve" 159 "reserve" 160 "reserve" 161 "reserve" 162 "reserve" 163 "reserve" 164 "reserve" 165 "reserve" 166 "reserve" 167 "reserve" 168 "reserve" 169 "reserve" 170 "reserve" 171 "reserve" 172 "reserve" 173 "reserve" 174 "reserve" 175 "reserve" 176 "reserve" 177 "reserve" 178 "reserve" 179 "reserve" 180 "reserve" 181 "reserve" 182 "reserve" 183 "reserve" 184 "reserve" 185 "reserve" 186 "reserve" 187 "reserve" 188 "reserve" 189 "reserve" 190 "reserve" 191 "reserve" 192 "reserve" 193 "reserve" 194 "reserve" 195 "reserve" 196 "reserve" 197 "reserve" 198 "reserve" 199 "reserve" 200 "reserve" 201 "reserve" 202 "reserve" 203 "reserve" 204 "reserve" 205 "reserve" 206 "reserve" 207 "reserve" 208 "reserve" 209 "reserve" 210 "reserve" 211 "reserve" 212 "reserve" 213 "reserve" 214 "reserve" 215 "reserve" 216 "reserve" 217 "reserve" 218 "reserve" 219 "reserve" 220 "reserve" 221 "reserve" 222 "reserve" 223 "reserve" 224 "reserve" 225 "reserve" 226 "reserve" 227 "reserve" 228 "reserve" 229 "reserve" 230 "reserve" 231 "reserve" 232 "reserve" 233 "reserve" 234 "reserve" 235 "reserve" 236 "reserve" 237 "reserve" 238 "reserve" 239 "reserve" 240 "reserve" 241 "reserve" 242 "reserve" 243 "reserve" 244 "reserve" 245 "reserve" 246 "reserve" 247 "reserve" 248 "reserve" 249 "reserve" 250 "reserve" 251 "reserve" 252 "reserve" 253 "reserve" 254 "reserve";
VAL_ 1260 ISLC_Comfirm_Request 0 "NO request" 1 "Request";
VAL_ 1260 HnpLastDistance 0 "More than 1000m" 1 "1000m last" 2 "900m last" 3 "800m last" 4 "700m last" 5 "600m last" 6 "500m last" 7 "400m last" 8 "300m last" 9 "200m last" 10 "150m last" 11 "100m last" 12 "50m last" 13 "0m last" 14 "Reserved" 15 "Reserved";
VAL_ 1260 AD_ICON 0 "No display" 1 "ACC standby" 2 "ACC active" 3 "ACC override" 4 "CP standby" 5 "CP active" 6 "CP override lon" 7 "CP override lat,reserve" 8 "HNP standby" 9 "HNP active" 10 "HNP override lon" 11 "HNP override lat,reserve" 12 "reserve" 13 "reserve" 14 "reserve" 15 "reserve" 16 "reserve" 17 "reserve" 18 "reserve" 19 "reserve" 20 "reserve" 21 "reserve" 22 "reserve" 23 "reserve" 24 "reserve" 25 "reserve" 26 "reserve" 27 "reserve" 28 "reserve" 29 "reserve" 30 "reserve";
VAL_ 1260 HNP_Status 0 "OFF" 1 "Passive" 2 "HNP Standby" 3 "HNP Active" 4 "MRC" 5 "Permanent error" 6 "Temporary error" 7 "Lave Keep" 8 "Navi Lane Change" 9 "Autonomous Lane Change" 10 "Semi Autonomous Lane Change" 11 "override" 12 "Standstill_Active" 13 "Standstill_Wait" 14 "BOM" 15 "Reserve" 16 "Reserve" 17 "Reserve" 18 "Reserve" 19 "Reserve" 20 "Reserve" 21 "Reserve" 22 "Reserve" 23 "Reserve" 24 "Reserve" 25 "Reserve" 26 "Reserve" 27 "Reserve" 28 "Reserve" 29 "Reserve" 30 "Reserve" 31 "Reserve" 32 "Reserve" 33 "Reserve" 34 "Reserve" 35 "Reserve" 36 "Reserve" 37 "Reserve" 38 "Reserve" 39 "Reserve" 40 "Reserve" 41 "Reserve" 42 "Reserve" 43 "Reserve" 44 "Reserve" 45 "Reserve" 46 "Reserve" 47 "Reserve" 48 "Reserve" 49 "Reserve" 50 "Reserve" 51 "Reserve" 52 "Reserve" 53 "Reserve" 54 "Reserve" 55 "Reserve" 56 "Reserve" 57 "Reserve" 58 "Reserve" 59 "Reserve" 60 "Reserve" 61 "Reserve" 62 "Reserve" 63 "BOM";
VAL_ 1260 HNP_Lane_Change_Status 0 "OFF" 1 "Waiting to change lane to left" 2 "Waiting to change lanes to right" 3 "Waiting confirmation to change lane to left" 4 "Waiting confirmation to change lanes to right" 5 "lane change cancel" 6 "Waiting to change lane failure" 7 "changing lane to the left" 8 "changing lane to the right" 9 "lane change back from the left" 10 "lane change back from the right" 11 "lane change successfully" 12 "Reserve" 13 "Reserve" 14 "Reserve" 15 "Reserve";
VAL_ 1260 Message_AD_Error 0 "no  warning ；" 1 "warning ；";
VAL_ 1260 Message_Inclement_weather 0 "no warning ;" 1 "heavy rain ;" 2 "heavy snow ;" 3 "heavy fog;";
VAL_ 1260 Message_FR_Camera_block 0 "no  warning ；" 1 "warning ；";
VAL_ 1260 Message_FR_Radar_block 0 "no  warning ；" 1 "warning ；";
VAL_ 1260 Msg_Side_Fisheye_Camera_block 0 "no  warning ；" 1 "warning ；";
VAL_ 1260 Message_Rear_Camera_block 0 "no  warning ；" 1 "warning ；";
VAL_ 1260 Message_Side_Rear_Radar_block 0 "no  warning ；" 1 "warning ；";
VAL_ 1260 SETTING_LDW_LDP_Status 0 "Reserve" 1 "Status OFF" 2 "Status ON of LDW" 3 "Status ON of LDW and LDP";
VAL_ 1260 LDW__INFO 0 "OFF" 1 "Passive" 2 "Standby" 3 "Active" 4 "temporary error" 5 "Permanent error" 6 "Reserve";
VAL_ 1260 SET_LDW_SENS_Status 0 "Reserve" 1 "Status Early" 2 "Status Middle" 3 "Status Late" 4 "Reserve" 5 "Reserve" 6 "Reserve";
VAL_ 1260 AEBS_INFO 0 "OFF" 1 "Passive" 2 "Standby" 3 "Active" 4 "temporary error" 5 "Permanent error" 6 "Reserve";
VAL_ 1260 SET_FCW_SENS_Status 0 "Reserve" 1 "Status Early" 2 "Status Middle" 3 "Status Late" 4 "Reserve" 5 "Reserve" 6 "Reserve";
VAL_ 1260 SETTING_AEBS_Status 0 "Reserve" 1 "Status OFF" 2 "Status ON" 3 "Reserve";
VAL_ 1260 LDP_INFO 0 "OFF" 1 "Passive" 2 "Standby" 3 "Active" 4 "temporary error" 5 "Permanent error" 6 "Reserve";
VAL_ 1260 SETTING_ELK_Status 0 "Reserve" 1 "Status OFF" 2 "Status ON" 3 "Reserve";
VAL_ 1260 ELK_INFO 0 "OFF" 1 "Passive" 2 "Standby" 3 "Active" 4 "temporary error" 5 "Permanent error" 6 "Reserve";
VAL_ 1260 SETTING_ESS_Status 0 "Reserve" 1 "Status OFF" 2 "Status ON" 3 "Reserve";
VAL_ 1260 ESS_INFO 0 "Off" 1 "Passive" 2 "Standby" 3 "Active" 4 "Temporary error" 5 "Permanent error" 6 "Reserve";
VAL_ 1260 SET_PILOT_STA 0 "ACC ON" 1 "CP ON" 2 "HNP ON" 3 "MNP ON (TBD)" 4 "Reserve" 5 "Reserve" 6 "Reserve" 7 "Reserve";
VAL_ 1260 SET_ILC_STA 0 "Reserve" 1 "Status OFF" 2 "Status ON" 3 "Reserve";
VAL_ 1260 SET_IHC_STA 0 "Reserve" 1 "Status OFF" 2 "Status ON" 3 "Reserve";
VAL_ 1260 SET_PLC_STA 0 "Reserve" 1 "Status OFF" 2 "Status ON" 3 "Reserve";
VAL_ 1260 ISLS_INFO 0 "OFF" 1 "Passive" 2 "Standby" 3 "Active" 4 "Active Warning" 5 "Reserve" 6 "Reserve" 7 "Failure";
VAL_ 1260 SET_TSR_status 0 "Reserve" 1 "Status OFF" 2 "Status ON" 3 "Reserve";
VAL_ 1260 TSR_INFO 0 "Passive" 1 "Standby" 2 "Active" 3 "Temporary error" 4 "Permanent error" 5 "Reserve" 6 "Reserve";
VAL_ 1260 SET_TLA_status 0 "Reserve" 1 "Status OFF" 2 "Status ON" 3 "Reserve";
VAL_ 1260 SET_TLAS_status 0 "Reserved" 1 "TLAD OFF and TLAI OFF  and TLAC OFF" 2 "TLAD ON and TLAI OFF  and TLAC OFF" 3 "TLAD ON and TLAI ON  and TLAC OFF" 4 "TLAD ON and TLAI ON  and TLAC ON";
VAL_ 1260 TLA__INFO 0 "Passive" 1 "Standby" 2 "Active" 3 "Active Warning" 4 "Active Control" 5 "Temporary error" 6 "Permanent error" 7 "Reserve";
VAL_ 1260 SET_RCTA_RCTB_status 0 "Reserve" 1 "RCTA OFF and RCTB OFF" 2 "RCTA ON and RCTB OFF" 3 "RCTA ON and RCTB ON";
VAL_ 1260 RCTA_INFO 0 "OFF" 1 "Temporary error" 2 "permanent error" 3 "Passive" 4 "Standby" 5 "RCTA Active" 6 "Reserve";
VAL_ 1260 RCTB_INFO 0 "OFF" 1 "Temporary error" 2 "permanent error" 3 "Passive" 4 "Standby" 5 "RCTB Active" 6 "Reserve";
VAL_ 1260 SET_FCTA_FCTB_status 0 "Reserve" 1 "FCTA OFF and FCTB OFF" 2 "FCTA ON and FCTB OFF" 3 "FCTA ON and FCTB ON";
VAL_ 1260 FCTA_INFO 0 "OFF" 1 "Temporary error" 2 "permanent error" 3 "Passive" 4 "Standby" 5 "FCTA Active" 6 "Reserve";
VAL_ 1260 FCTB_INFO 0 "OFF" 1 "Temporary error" 2 "permanent error" 3 "Passive" 4 "Standby" 5 "FCTB Active" 6 "Reserve";
VAL_ 1260 SET_BSW_status 0 "Reserve" 1 "Status OFF" 2 "Status ON" 3 "Reserve";
VAL_ 1260 BSW_INFO 0 "OFF" 1 "Temporary error" 2 "permanent error" 3 "Passive" 4 "Standby" 5 "BSW Active Level1" 6 "BSW Active Level2" 7 "Reserve";
VAL_ 1260 SET_DOW_status 0 "Reserve" 1 "Status OFF" 2 "Status ON" 3 "Reserve";
VAL_ 1260 DOW_INFO 0 "OFF" 1 "Temporary error" 2 "permanent error" 3 "Passive" 4 "Standby" 5 "DOW Active Level1" 6 "DOW Active Level2" 7 "Reserve";
VAL_ 1260 SET_RCW_status 0 "Reserve" 1 "Status OFF" 2 "Status ON" 3 "Reserve";
VAL_ 1260 RCW_INFO 0 "OFF" 1 "Temporary error" 2 "permanent error" 3 "Passive" 4 "Standby" 5 "RCW Active" 6 "Reserve";
VAL_ 1260 SET_VOL_STA 0 "Reserve" 1 "Status OFF" 2 "Status ON" 3 "Reserve";
VAL_ 1260 SET_CDW_SENS_Status 0 "Reserve" 1 "Status Early" 2 "Status Middle" 3 "Status Late" 4 "Reserve" 5 "Reserve" 6 "Reserve";
VAL_ 1260 SETTING_CDW_Status 0 "Reserve" 1 "Status OFF" 2 "Status ON" 3 "Reserve";
VAL_ 1260 MSG_FR_Camera_H_Temp 0 "No Warning" 1 "Warning";
VAL_ 1260 MSG_RR_Camera_H_Temp 0 "No Warning" 1 "Warning";
VAL_ 1260 MSG_ADCU_H_Temp 0 "No Warning" 1 "Warning";
VAL_ 1260 MSG_fisheye_Camera_H_Temp 0 "No Warning" 1 "Warning";
VAL_ 1260 MSG_VDC_NO_Actived 0 "No Warning" 1 "Warning";
VAL_ 1260 SET_ISLS_STA 0 "Reserve" 1 "ISLD OFF and ISLI  OFF  and ISLC OFF" 2 "ISLD ON and ISLI  OFF  and ISLC OFF" 3 "ISLD ON  and ISLI  ON and ISLC OFF" 4 "ISLD ON  and ISLI  ON and ISLC ON" 5 "Reserve" 6 "Reserve";
VAL_ 1260 SALC_INFO 0 "OFF" 1 "passive" 2 "standby" 3 "active" 4 "error" 5 "reserve" 6 "reserve";
VAL_ 1260 HNPDowngradeStatus 0 "Not show" 1 "Can downgrade" 2 "Cannot downgrade" 3 "reserve" 4 "reserve" 5 "reserve" 6 "reserve";
VAL_ 1260 CPUpgradeStatus 0 "Not show" 1 "Can upgrade" 2 "Cannot upgrade" 3 "reserve" 4 "reserve" 5 "reserve" 6 "reserve";
VAL_ 1260 HNPLaneChangeStyleStatus 0 "reserve" 1 "Level 1" 2 "Level 2" 3 "Level 3";
VAL_ 1260 HNPLanePreferenceStatus 0 "reserve" 1 "Left 1 Lane" 2 "Left 2 Lane" 3 "Left 3 Lane" 4 "reserve" 5 "reserve" 6 "reserve";
VAL_ 1260 TSR_DISP 0 "NoDisplay" 1 "Overtaking Forbidden" 2 "Overtaking Forbidden Cancel" 3 "Stop Sign" 4 "Give Way Sign" 5 "Road Work Sign" 6 "Pedestrian Crossings" 7 "Bycle Lane" 8 "Prohibit Parking" 9 "NoEntrySign" 10 "NoMotorVehiclesAreAllowedToEnterTheSign" 11 "NoLeftTurnSign" 12 "NoRightTrunSign" 13 "UShapeBendMarkIsProhibited" 14 "ParkingSign" 15 "YieldSign" 16 "VehicleImportFlagOnTheRight" 17 "StartingPointOfTheHighway" 18 "EndOfHighway" 19 "MakeASharpRightTurn" 20 "SharpLeftTurn" 21 "VehicleImportFlagOnTheLeft" 22 "Rain and wet" 23 "Snow and ice" 24 "BEGIN_OF_PASSING_RESTRICTION" 25 "END_OF_NO_PASSING_RESTRICTION" 26 "NO_PASS" 27 "TSR_SIGN_NO_PASSENGER_CAR_ENTRANCE" 28 "NO_VEHICLE_ENTRANCE" 29 "Reserve" 30 "Reserve" 31 "ParkingSign";
VAL_ 1260 TLA_Pattern 0 "None" 1 "Left Uturn" 2 "Left Arrow" 3 "Right Arrow" 4 "Up Arrow" 5 "Left Solid Circle" 6 "Right Solid Circle" 7 "Up Solid Circle";
VAL_ 1260 Left_Uturn_Indication 0 "Unknown" 1 "Red" 2 "Yellow" 3 "Green" 4 "Yellow Blinking" 5 "Green Blinking" 6 "Reserve";
VAL_ 1260 Turn_Left_Indication 0 "Unknown" 1 "Red" 2 "Yellow" 3 "Green" 4 "Yellow Blinking" 5 "Green Blinking" 6 "Reserve";
VAL_ 1260 Go_Stright_Indication 0 "Unknown" 1 "Red" 2 "Yellow" 3 "Green" 4 "Yellow Blinking" 5 "Green Blinking" 6 "Reserve";
VAL_ 1260 Trun_Right_Indication 0 "Unknown" 1 "Red" 2 "Yellow" 3 "Green" 4 "Yellow Blinking" 5 "Green Blinking" 6 "Reserve";
VAL_ 1260 ALC_Confirm 0 "Reserve" 1 "Status OFF" 2 "Status ON" 3 "Reserve";
VAL_ 1260 DVR_InfoStatus 0 "Reserved" 1 "Status OFF" 2 "Status ON" 3 "Not used";
VAL_ 1260 MESSAGE_DVR_WARN 0 "No Warning" 1 "Warning";
VAL_ 1260 CDW_INFO 0 "OFF" 1 "Passive" 2 "Standby" 3 "Active" 4 "temporary error" 5 "Permanent error" 6 "Reserve";
VAL_ 1260 AD_Safety_Event 0 "No Event（未触发）" 1 "Other Reason（其他原因）" 2 "Crossed Over the Lines with AD Active（AD激活时压车道线）" 3 "Brake Pedal Depressed（驾驶员踩刹车）" 4 "Pilot Cancel（Pilot键退出）" 5 "Excessive Steering Wheel Torque（方向盘手力矩过大）" 6 "Left or Right Lamp On（打转向灯）" 7 "Not D Range（非D档）" 8 "Door Open（车门打开）" 9 "Boot Open（后背门打开）" 10 "Hood Open（前机舱盖打开）" 11 "Driver Seat Belt not Fastened（主驾安全带未系）" 12 "AD Switch Status OFF（AD车机软开关OFF）" 13 "Accelerate to Over 130 kph（主动加速超过130kph）" 14 "EPB Applied（拉起EPB）" 15 "No Driver in the Seat（驾驶员离开主驾座位）" 16 "Hands Off-Heavy（三级脱手报警）" 17 "The Vehicle Has Stopped（车辆已刹停）" 18 "AD Failure（AD系统故障）" 19 "Excessive Lane Curvature（车道曲率过大）" 20 "Lane Disappeared（车道线消失）" 21 "Deceleration Limit Exceeded（减速度达到上限）" 22 "AEB Active（AEB激活）" 23 "reserved" 24 "reserved" 25 "reserved" 26 "reserved" 27 "reserved" 28 "reserved" 29 "reserved" 30 "reserved";
VAL_ 1260 CFDI_ALL_Sts 0 "No Request" 1 "CDFI ALL DATA ON" 2 "CDFI ALL DATA OFF" 3 "CDFI ALL DATA ON EXCEPT PERSONAL DATA";
VAL_ 1260 CFDI_DeletePDDATA_Sts 0 "No Request" 1 "CDFI PERSONAL DATA DELETE" 2 "CDFI PERSONAL DATA DELETE FAIL" 3 "Reserved";
VAL_ 640 STAT_CHG_REQ2 0 "Not Request" 1 "ALC comfirm OFF" 2 "ALC confirm ON" 3 "HNP recommand OFF" 4 "HNP recommand ON" 5 "FCTA OFF and FCTB OFF" 6 "FCTA ON and FCTB OFF" 7 "FCTA OFF and FCTB ON" 8 "FCTA ON and FCTB ON" 9 "MEB OFF" 10 "MEB ON" 11 "ESS OFF" 12 "ESS ON" 13 "PLC ON" 14 "PLC OFF" 15 "TSR OFF" 16 "TSR ON" 17 "TLAD OFF and TLAI OFF  and TLAC OFF" 18 "TLAD ON and TLAI OFF  and TLAC OFF" 19 "TLAD ON and TLAI ON  and TLAC OFF" 20 "TLAD ON and TLAI ON  and TLAC ON" 21 "MNP OFF" 22 "MNP ON" 23 "MNP Downgrade to CP Request" 24 "CP Upgrade to MNP Request" 25 "Early(CDW Timing)" 26 "Middle(CDW Timing)" 27 "Late(CDW Timing)" 28 "Lane Change Style Level 1（柔和）" 29 "Lane Change Style Level 2（标准）" 30 "Lane Change Style Level 3（激进）" 31 "Lane Preference， Left 1" 32 "Lane Preference， Left 2" 33 "Lane Preference， Left 3" 34 "HNP Downgrade to CP Request" 35 "CP Upgrade to HNP Request" 36 "DMS drowniness distraction switch on" 37 "DMS drowniness distraction switch off" 38 "DMS dangerous behavior switch on" 39 "DMS dangerous behavior switch off" 40 "DMS Sensitivity level high" 41 "DMS Sensitivity level low" 42 "DVR OFF" 43 "DVR ON" 44 "Reserved" 45 "MNP Begin to Build Route" 46 "MNP Finish building Route" 47 "MNP Cancel Building Route" 48 "MNP Complete save" 49 "MNP Route Building Failure and no save";
VAL_ 640 BAC_SW 0 "seat belt buckle switch on" 1 "seat belt buckle switch off (sheet belt lamp on)";
VAL_ 640 AD_signalback 0 "no receive" 1 "receive";
VAL_ 853 Disp_Unit 0 "km/h" 1 "MPH";
VAL_ 853 STAT_CHG_REQ1 0 "Not Request" 1 "CDW OFF" 2 "CDW ON" 3 "LDW and LDP OFF" 4 "LDW ON" 5 "BSW OFF" 6 "BSW ON" 7 "Only ACC" 8 "CP mode" 9 "LDP OFF Reserve (not use)" 10 "LDP ON" 11 "ELK OFF" 12 "ELK ON" 13 "ISLD OFF and ISLI  OFF  and ISLC OFF" 14 "ISLD ON and ISLI  OFF  and ISLC OFF" 15 "ISLD ON  and ISLI  ON and ISLC OFF" 16 "ISLD ON  and ISLI  ON and ISLC ON" 17 "Early(LDW Timing)" 18 "Middle(LDW Timing" 19 "Late(LDW Timing)" 20 "Early(FCW Timing)" 21 "Middle(FCW Timing)" 22 "Late(FCW Timing)" 23 "ILC OFF" 24 "ILC ON" 25 "HNP mode" 26 "MOD_OFF" 27 "MOD_ON" 28 "RCTA OFF and RCTB OFF" 29 "RCTA ON and RCTB OFF" 30 "DOW OFF" 31 "DOW ON" 32 "RCTA OFF and RCTB ON" 33 "RCTA ON and RCTB ON" 34 "Factory setting reset signal" 35 "AEBS OFF" 36 "AEBS ON" 37 "EAPM OFF" 38 "EAPM ON" 39 "not used" 40 "SONAR_AUTO_DISPLAY_OFF" 41 "SONAR_AUTO_DISPLAY_ON" 42 "SONAR_DETECTION_RANGE_NEAR" 43 "SONAR_DETECTION_RANGE_MIDDLE" 44 "SONAR_SYSTEM_OFF" 45 "SONAR_SYSTEM_ON(FR&RR)" 46 "SONAR_SYSTEM_ON(FR only)" 47 "SONAR_SYSTEM_PAUSE_ON" 48 "SONAR_DETECTION_RANGE_FAR" 49 "SONAR_BUZZER_VOLUME_HIGH" 50 "SONAR_BUZZER_VOLUME_MIDDLE" 51 "SONAR_BUZZER_VOLUME_LOW" 52 "SONAR_FRONT_OFF" 53 "SONAR_FRONT_ON" 54 "SONAR_REAR_OFF" 55 "SONAR_REAR_ON" 60 "RCW OFF" 61 "RCW ON" 62 "FCW OFF Reseve (not use)" 63 "FCW ON Reseve (not use)";
VAL_ 1402 REQ_DISP_MET 0 "No sonar detection display request" 1 "Sonar detection display request";
VAL_ 1402 REQ_DISP_CEN 0 "No sonar detection display request" 1 "Sonar detection display request";
VAL_ 1402 SONAR_S_REQ 0 "No sonar status display request" 1 "Sonar status display request" 2 "SONAR deactive" 3 "SONAR ERROR" 4 "SONAR front ERROR" 5 "RESERVE" 6 "RESERVE";
VAL_ 1402 STS_SETTING 0 "Setting unavailable" 1 "Setting avaiilable";
VAL_ 1402 RR_CEN 0 "No detection" 1 "Detect level 4 (180~70cm)" 2 "Detect level 3 (70~50cm)" 3 "Detect level 2 (50~30cm)" 4 "Detect level 1 (30~cm)" 5 "Not used" 6 "Not used" 7 "Not used";
VAL_ 1402 A_RR_CEN 0 "No sensor" 1 "Sensor available";
VAL_ 1402 FR_CEN 0 "No detection" 1 "Detect level 4 (180~70cm)" 2 "Detect level 3 (70~50cm)" 3 "Detect level 2 (50~30cm)" 4 "Detect level 1 (30~cm)" 5 "Not used" 6 "Not used" 7 "Not used";
VAL_ 1402 A_FR_CEN 0 "No sensor" 1 "Sensor available";
VAL_ 1402 RR_L 0 "No detection" 1 "Reserve" 2 "Detect level 3 (70~50cm)" 3 "Detect level 2 (50~30cm)" 4 "Detect level 1 (30~cm)" 5 "Not used" 6 "Not used" 7 "Not used";
VAL_ 1402 A_RR_L 0 "No sensor" 1 "Sensor available";
VAL_ 1402 RR_R 0 "No detection" 1 "Reserve" 2 "Detect level 3 (70~50cm)" 3 "Detect level 2 (50~30cm)" 4 "Detect level 1 (30~cm)" 5 "Not used" 6 "Not used" 7 "Not used";
VAL_ 1402 A_RR_R 0 "No sensor" 1 "Sensor available";
VAL_ 1402 FR_L 0 "No detection" 1 "Reserve" 2 "Detect level 3 (70~50cm)" 3 "Detect level 2 (50~30cm)" 4 "Detect level 1 (30~cm)" 5 "Not used" 6 "Not used" 7 "Not used";
VAL_ 1402 A_FR_L 0 "No sensor" 1 "Sensor available";
VAL_ 1402 FR_R 0 "No detection" 1 "Reserve" 2 "Detect level 3 (70~50cm)" 3 "Detect level 2 (50~30cm)" 4 "Detect level 1 (30~cm)" 5 "Not used" 6 "Not used" 7 "Not used";
VAL_ 1402 A_FR_R 0 "No sensor" 1 "Sensor available";
VAL_ 1402 STS_DISTANCE 0 "No detection" 1 "STOP (continuous tone)" 2 "30cm" 3 "40cm" 4 "50cm" 5 "60cm" 6 "70cm" 7 "80cm" 8 "90cm" 9 "100cm" 10 "110cm" 11 "120cm" 12 "130cm" 13 "140cm" 14 "150cm" 15 "160cm" 16 "170cm" 17 "180cm" 18 "190cm" 19 "200cm" 20 "reserve" 21 "reserve" 22 "reserve" 23 "reserve" 24 "reserve" 25 "reserve" 26 "reserve" 27 "reserve" 28 "reserve" 29 "reserve" 30 "reserve" 31 "reserve";
VAL_ 1402 STS_AUTO_DISP 0 "DISPLAY ON" 1 "DISPLAY OFF";
VAL_ 1402 STS_SYS_MODE 0 "Active FR&RR" 1 "Active FR only" 2 "Permanent deactive" 3 "Error" 4 "Temporary OFF_FR_RR" 5 "Temporary OFF_FR_ONLY" 6 "RESERVE" 7 "RESERVE";
VAL_ 1402 SOUND_ZONE 0 "No sound request" 1 "REAR Left" 2 "REAR Center" 3 "REAR Right" 4 "REAR Left side" 5 "REAR Right side" 6 "RESERVE" 7 "RESERVE";
VAL_ 1402 SOUND_CONT 0 "Discontinuous" 1 "Continuous";
VAL_ 1402 SOUND_LEVEL 0 "No sound request" 1 "LV4 （Beep cycle- Beep 75ms +No Beep 300ms）" 2 "LV3（Beep cycle- Beep 75ms +No Beep 150ms）" 3 "LV2 （Beep cycle- Beep 75ms +No Beep 75ms）" 4 "LV1  （Beep cycle- Continuous Beep）" 5 "Continuous beeping （启动时自检鸣叫需求 0.5S or 3S）" 6 "RESERVE" 7 "MUTE";
VAL_ 1402 SONAR_Detect_Distance_F 0 "No detection" 1 "STOP (continuous tone)" 2 "30cm" 3 "40cm" 4 "50cm" 5 "60cm" 6 "70cm" 7 "80cm" 8 "90cm" 9 "100cm" 10 "110cm" 11 "120cm" 12 "130cm" 13 "140cm" 14 "150cm" 15 "160cm" 16 "170cm" 17 "180cm" 18 "190cm" 19 "200cm" 20 "reserve" 21 "reserve" 22 "reserve" 23 "reserve" 24 "reserve" 25 "reserve" 26 "reserve" 27 "reserve" 28 "reserve" 29 "reserve" 30 "reserve" 31 "reseave";
VAL_ 1402 RangeStatus_RR_Right_side 0 "No detection" 1 "Reserve" 2 "Detect level 3 (70~50cm)" 3 "Detect level 2 (50~30cm)" 4 "Detect level 1 (30~cm)" 5 "Not used" 6 "Not used" 7 "Not used";
VAL_ 1402 Availavility_RR_CornerRight_side 0 "No sensor" 1 "Sensor available";
VAL_ 1402 RangeStatus_RR_left_side 0 "No detection" 1 "Reserve" 2 "Detect level 3 (70~50cm)" 3 "Detect level 2 (50~30cm)" 4 "Detect level 1 (30~cm)" 5 "Not used" 6 "Not used" 7 "Not used";
VAL_ 1402 Availavility_RR_Cornerleft_side 0 "No sensor" 1 "Sensor available";
VAL_ 1402 RangeStatus_FR_Right_side 0 "No detection" 1 "Reserve" 2 "Detect level 3 (70~50cm)" 3 "Detect level 2 (50~30cm)" 4 "Detect level 1 (30~cm)" 5 "Not used" 6 "Not used" 7 "Not used";
VAL_ 1402 Availavility_FR_CornerRight_side 0 "No sensor" 1 "Sensor available";
VAL_ 1402 RangeStatus_FR_Left_side 0 "No detection" 1 "Reserve" 2 "Detect level 3 (70~50cm)" 3 "Detect level 2 (50~30cm)" 4 "Detect level 1 (30~cm)" 5 "Not used" 6 "Not used" 7 "Not used";
VAL_ 1402 Availavility_FR_CornerLeft_side 0 "No sensor" 1 "Sensor available";
VAL_ 1402 SoundObstacleZone_Request 0 "No sound request" 1 "FRONT Left" 2 "FRONT Center" 3 "FRONT Right" 4 "FRONT Left side" 5 "FRONT Right side" 6 "RESERVE" 7 "RESERVE";
VAL_ 1403 STS_D_EAP 0 "EAPM OFF" 1 "EAPM Passive" 2 "EAPM Standby" 3 "EAPM Active" 4 "EAPM Temporary OFF" 5 "EAPM Failure" 6 "Reserve" 7 "ESP close";
VAL_ 1403 SET_EAPM 0 "No setting" 1 "Setting OFF" 2 "Setting ON" 3 "Not Used";
VAL_ 1403 STS_W_EAP 0 "No Display" 1 "Display (System ON)" 2 "Display (EAPM Temporary OFF)" 3 "Display (EAPM Malfunction)";
VAL_ 1403 SOUND_EAPM 0 "No Beep request" 1 "Beep request";
VAL_ 1405 APA_Function_Status 0 "Passive" 1 "Standby" 2 "Searching in/out" 3 "Parking in/out" 4 "Paused" 5 "Failure" 6 "Complete" 7 "Reserve";
VAL_ 1405 APA_Park_Mode 0 "Default" 1 "Park-in" 2 "Park-out" 3 "RPA_Straight";
VAL_ 1405 APA_Control_Mode 0 "Default (not in control mode)" 1 "DA control mode" 2 "BLE control mode" 3 "reserve";
VAL_ 1405 APA_Page_Type 0 "No display" 1 "Page type1- SR 45+AVM full" 2 "Page type2- SR 45+AVM half" 3 "Page type3- SR 90+AVM full" 4 "Page type4- SR 90+AVM half" 5 "Page type5- SR 60+AVM full" 6 "Page type6- SR 60+AVM half" 7 "Page type7- FIRST TIME HPA TEACHING" 8 "Page type8- setting page" 9 "reserve" 10 "reserve" 11 "reserve" 12 "reserve" 13 "reserve" 14 "reserve" 15 "reserve";
VAL_ 1405 HPA_Try_Guidance 0 "No_Display" 1 "No_Complete" 2 "Complete1" 3 "Complete2" 4 "Complete3" 5 "reserve" 6 "reserve" 7 "reserve";
VAL_ 1405 HPA_Function_Status 0 "Unavailable" 1 "Available" 2 "Searching" 3 "Learning" 4 "Cruising" 5 "MRM" 6 "reserve" 7 "reserve" 8 "reserve" 9 "reserve" 10 "reserve" 11 "reserve" 12 "reserve" 13 "reserve" 14 "reserve" 15 "reserve";
VAL_ 1405 APA_Enter_Switch_Status 0 "Hidden" 1 "Available" 2 "HightLight" 3 "Invalid";
VAL_ 1405 APA_Exit_Switch_Status 0 "Hidden" 1 "Unavailable" 2 "Available" 3 "Invalid";
VAL_ 1405 APA_Button0_Status 0 "Hiden" 1 "Unavailable" 2 "Available" 3 "Invalid";
VAL_ 1405 APA_Button1_Status 0 "Hiden" 1 "Unavailable" 2 "Available" 3 "Invalid";
VAL_ 1405 APA_Button2_Status 0 "No display (hidden)" 1 "Pause Available" 2 "Pause Unavailable" 3 "Resume available" 4 "Resume unavailable" 5 "Reserve" 6 "Reserve" 7 "Invalid";
VAL_ 1405 APA_Button3_Status 0 "Hiden" 1 "Unavailable" 2 "Available" 3 "Invalid";
VAL_ 1405 APA_Button4_Status 0 "Hiden" 1 "Unavailable" 2 "Available" 3 "Invalid";
VAL_ 1405 APA_Button5_Status 0 "Hiden" 1 "Unavailable" 2 "Available" 3 "Invalid";
VAL_ 1405 APA_Button6_Status 0 "Hiden" 1 "Unavailable" 2 "Available" 3 "Invalid";
VAL_ 1405 HPA_Button1_Status 0 "Hiden" 1 "Unavailable" 2 "Available" 3 "Invalid";
VAL_ 1405 HPA_Button2_Status 0 "Hiden" 1 "Unavailable" 2 "Available" 3 "Invalid";
VAL_ 1405 APA_PrakOut_Form 0 "Invalid；" 1 "Horizontal ；" 2 "Vertical;" 3 "reserve" 4 "reserve" 5 "reserve" 6 "reserve" 7 "reserve" 8 "reserve" 9 "reserve" 10 "reserve" 11 "reserve" 12 "reserve" 13 "reserve" 14 "reserve";
VAL_ 1405 APA_parkinDir_SelectStatus 0 "Unavailable" 1 "Available";
VAL_ 1405 APA_parkinDir_Select_Result 0 "Invalid" 1 "Head in" 2 "Tail in" 3 "Reserve";
VAL_ 1405 APA_parkoutDir_FLStatus 0 "Hiden" 1 "Available" 2 "HightLight" 3 "Invalid";
VAL_ 1405 APA_parkoutDir_FCStatus 0 "Hiden" 1 "Available" 2 "HightLight" 3 "Invalid";
VAL_ 1405 APA_parkoutDir_FRStatus 0 "Hiden" 1 "Available" 2 "HightLight" 3 "Invalid";
VAL_ 1405 APA_parkoutDir_RLStatus 0 "Hiden" 1 "Available" 2 "HightLight" 3 "Invalid";
VAL_ 1405 APA_parkoutDir_RCStatus 0 "Hiden" 1 "Available" 2 "HightLight" 3 "Invalid";
VAL_ 1405 APA_parkoutDir_RRStatus 0 "Hiden" 1 "Available" 2 "HightLight" 3 "Invalid";
VAL_ 1405 APA_SuggestOnOff_Status 0 "Default" 1 "Status_OFF" 2 "Status_ON" 3 "Invalid";
VAL_ 1405 APA_USSDispOnOff_Status 0 "Default" 1 "Status_OFF" 2 "Status_ON" 3 "Invalid";
VAL_ 1405 APA_SpeedSet_Status 0 "Invalid" 1 "Park speed low" 2 "Park speed medium" 3 "Park speed high";
VAL_ 1405 APA_TTSOnOff_Status 0 "Default" 1 "Status_OFF" 2 "Status_ON" 3 "Invalid";
VAL_ 1405 RPA_OnOff_Status 0 "Default" 1 "Status_OFF" 2 "Status_ON" 3 "Invalid";
VAL_ 1405 HPA_OnOff_Status 0 "Default" 1 "Status_OFF" 2 "Status_ON" 3 "Invalid";
VAL_ 1405 HPA_SuggestOnOff_Status 0 "Default" 1 "Status_OFF" 2 "Status_ON" 3 "Invalid";
VAL_ 1405 HPA_SpeedSet_Status 0 "Cuise speed low" 1 "Cuise speed medium" 2 "Cuise speed high" 3 "Invalid";
VAL_ 1405 HPA_Route1_Status 0 "Not learned" 1 "Learned";
VAL_ 1405 HPA_Route2_Status 0 "Not learned" 1 "Learned";
VAL_ 1405 HPA_Route3_Status 0 "Not learned" 1 "Learned";
VAL_ 1405 HPA_Route4_Status 0 "Not learned" 1 "Learned";
VAL_ 1405 HPA_Route5_Status 0 "Not learned" 1 "Learned";
VAL_ 1405 HPA_Route6_Status 0 "Not learned" 1 "Learned";
VAL_ 1405 HPA_Route7_Status 0 "Not learned" 1 "Learned";
VAL_ 1405 HPA_Route8_Status 0 "Not learned" 1 "Learned";
VAL_ 1405 HPA_Route9_Status 0 "Not learned" 1 "Learned";
VAL_ 1405 HPA_Route10_Status 0 "Not learned" 1 "Learned";
VAL_ 1405 HPA_Route11_Status 0 "Not learned" 1 "Learned";
VAL_ 1405 HPA_Route12_Status 0 "Not learned" 1 "Learned";
VAL_ 1405 HPA_Route13_Status 0 "Not learned" 1 "Learned";
VAL_ 1405 HPA_Route14_Status 0 "Not learned" 1 "Learned";
VAL_ 1405 HPA_Route15_Status 0 "Not learned" 1 "Learned";
VAL_ 1405 HPA_Route16_Status 0 "Not learned" 1 "Learned";
VAL_ 1405 HPA_Route17_Status 0 "Not learned" 1 "Learned";
VAL_ 1405 HPA_Route18_Status 0 "Not learned" 1 "Learned";
VAL_ 1405 HPA_Route19_Status 0 "Not learned" 1 "Learned";
VAL_ 1405 HPA_Route20_Status 0 "Not learned" 1 "Learned";
VAL_ 1405 HPA_Route_DeleteResp 0 "Default (no request)" 1 "Delete success" 2 "Delete fail" 3 "Invalid";
VAL_ 1405 APA_TextGuidance 0 "No request" 1 "APA_SEARCHING_IN_START_ALERT" 2 "APA_FOUND_SLOT_ALERT" 3 "APA_SPEED_TOO_HIGH_D_Range" 4 "APA_SPEED_TOO_HIGH_R_Range" 5 "APA_PARKING_IN_SELECT_ALERT" 6 "APA_PARKING_IN_START_ALERT" 7 "RPA_PARKING_IN_START_ALERT" 8 "APA_BRAKE_PEDAL_DEPRESSED_ALERT" 9 "APA_PARKING_PAUSE_ALERT" 10 "APA_PARKING_FAIL_ALERT" 11 "APA_PARKING_FINISH_ALERT" 12 "APA_SEARCHING_OUT_START_ALERT" 13 "APA_PARKING_OUT_SELECT_ALERT" 14 "ROUTE_UPDATE_BUTTON_PRESSED" 15 "STUDY_CONFIRM_BUTTON_PRESSED" 16 "IN_STUDY_PROCESS" 17 "NO_STOP_PARKING_IN_BUTTON_PRESSED" 18 "STOP_NO_SLOT" 19 "SPEED_BUMP_RECOGNITION" 20 "LAST_HUNDRED_ALERT" 21 "STUDY_DISTANCE_TOO_LONG_ALERT" 22 "ON_SLOPE" 23 "OFF_SLOPE" 24 "STOP_HAVE_SLOT" 25 "MAP_VERIFICATION" 26 "NOT_IN_SLOT" 27 "HEAD_PARKING_IN" 28 "MAP_CREATION_FAILURE" 29 "MAP_CREATION_SUCCESS" 30 "COMPLETE_AND_TRY" 31 "ARRIVE_START_POINT" 32 "NOT_ARRIVE_START_POINT" 33 "START_CRUISE" 34 "PARKING_IN_BUTTON_PRESSED" 35 "LEFT_TURN" 36 "RIGHT_TURN" 37 "JUNCTION_AHEAD" 38 "ENTER_SLOPE" 39 "EXIT_SLOPE" 40 "SPACE_NOT_PASS" 41 "DETOUR_CAR" 42 "PEDESTRIANS_YIELD" 43 "OBSTACLE_YIELD" 44 "CRUISE_COMPLETE" 45 "PARKING_IN_PROCESS_START" 46 "THROTTLE_ON" 47 "SWITCH_P_Gear(RPA)" 48 "Getoff_Car_AND_UseRPA(RPA)" 49 "During RPA(RPA)" 50 "LongPressTOstartStraightAhead(RPA)" 51 "PAUSE RESUME" 52 "DRIVER_DOOR_OPEN" 53 "PASSENGER_DOOR_OPEN" 54 "FRONT_HOOD_OPEN" 55 "BACK_TRUNK_OPEN" 56 "REARVIEW_MIRROR_FOLDED" 57 "CHARGING_GUN_CONNECT" 58 "BLUETOOTH_NOT_CONNECTTED" 59 "SWITCH_D_OR_R_GEAR" 60 "reserve" 61 "reserve" 62 "reserve" 63 "reserve";
VAL_ 1405 APA_AutoSuggest_Request 0 "No request" 1 "HAVE_PARKING_SLOT" 2 "HAVE_CRUISE" 3 "HAVE_ROUTE_STUDY";
VAL_ 1405 APA_EnterFail_Notify 0 "No failure" 1 "Fr camera fail" 2 "AVM FR camera fail" 3 "AVM Left camera fail" 4 "AVM Right camera fail" 5 "AVM RR camera fail" 6 "USS ECU fail" 7 "USS FR fail" 8 "USS side fail" 9 "USS RR fail" 10 "ADCU software error" 11 "ADCU hardwar error" 12 "IBC fail" 13 "VCM fail" 14 "EPS fail" 15 "P-box fail" 16 "ABS fail" 17 "ESC fail" 18 "OVER SPEED" 19 "OTHER_AD_ACTIVE" 20 "RPA_OFF" 21 "PowerStatusNotReady" 22 "RPANotReady" 23 "Not_P_Range" 24 "reserve" 25 "reserve" 26 "reserve" 27 "reserve" 28 "reserve" 29 "reserve" 30 "reserve" 31 "Invalid";
VAL_ 1405 APA_Park_Pause_Notify 0 "No Request" 1 "DRIVER_DOOR_OPEN" 2 "SEATBELT_OPEN" 3 "DETECTION_NOT_DRIVER" 4 "PASSENGER_DOOR_OPEN" 5 "FRONT_HOOD_OPEN" 6 "BACK_TRUNK_OPEN" 7 "REARVIEW_MIRROR_FOLDER" 8 "BLUETOOTH_CONNECTION_FAIL" 9 "OBSTACLE_ONPATH" 10 "RPAMoveDsitanceExceedLimit" 11 "reserve" 12 "reserve" 13 "reserve" 14 "reserve" 15 "reserve" 16 "reserve" 17 "reserve" 18 "reserve" 19 "reserve" 20 "reserve" 21 "reserve" 22 "reserve" 23 "reserve" 24 "reserve" 25 "reserve" 26 "reserve" 27 "reserve" 28 "reserve" 29 "reserve" 30 "reserve" 31 "reserve" 32 "reserve" 33 "reserve" 34 "reserve" 35 "reserve" 36 "reserve" 37 "reserve" 38 "reserve" 39 "reserve" 40 "reserve" 41 "reserve" 42 "reserve" 43 "reserve" 44 "reserve" 45 "reserve" 46 "reserve" 47 "reserve" 48 "reserve" 49 "reserve" 50 "reserve" 51 "reserve" 52 "reserve" 53 "reserve" 54 "reserve" 55 "reserve" 56 "reserve" 57 "reserve" 58 "reserve" 59 "reserve" 60 "reserve" 61 "reserve" 62 "reserve";
VAL_ 1405 APA_Park_Quit_Notify 0 "No Request" 1 "CHARGING_GUN_CONNECT" 2 "TIER_PRESSURE_FAILURE" 3 "RAIN_SENSOR_FAILURE" 4 "BLUETOOTH_CONNECTION_FAIL" 5 "FRONT_AVM_FAILURE" 6 "REAR_AVM_FAILURE" 7 "LEFT_AVM_FAILURE" 8 "RIGHT_AVM_FAILURE" 9 "SONAR_CONT_FAILURE" 10 "FRONT_SONAR_FAILURE" 11 "SIDE_SONAR_FAILURE" 12 "REAR_SONAR_FAILURE" 13 "ADCU_SW_FAILURE" 14 "ADCU_HW_FAILURE" 15 "VCM_FAILURE" 16 "IBC_FAILURE" 17 "EPS_FAILURE" 18 "IMU_FAILURE" 19 "ABS_FAILURE" 20 "ESC_FAILURE" 21 "BLE_FAILURE" 22 "ABS_ACTIVE" 23 "ESC_ACTIVE" 24 "OTHER_AD_ACTIVE" 25 "MEB_ACTIVE" 26 "AEB_ACTIVE" 27 "RCTB_ACTIVE" 28 "FCTB_ACTIVE" 29 "ACU_ACTIVE" 30 "ODD_NOT_SATISFIED" 31 "SLOPE_TOO_HIGH" 32 "SPEED_TOO_HIGH" 33 "THROTTLE_TAKEOVER" 34 "STEERING_TAKEOVER" 35 "GEAR_TAKEOVER" 36 "EPB_ACTIVE" 37 "TARGET_SLOT_NOT_ACTIVE" 38 "PARKING_TIMER_OVERTHRESHOLD" 39 "PAUSE_COUNT_OVERTHRESHOLD" 40 "PAUSE_TIME_OVERTHRESHOLD" 41 "SLOT_TOO_NARROW" 42 "PLANNING_TIME_OVERTHRESHOLD" 43 "HANDSHAKE FAIL" 44 "EXIT_BUTTON_PRESSED" 45 "NAVIGATION_EXIT" 46 "APA_RETURN" 47 "SCREEN_SLIDE_EXIT" 48 "PARKING FAIL" 49 "PARKING SUCCESS" 50 "RPA MOVE OVER 10 Times" 51 "EPB_FAILURE" 52 "reserve" 53 "reserve" 54 "reserve" 55 "reserve" 56 "reserve" 57 "reserve" 58 "reserve" 59 "reserve" 60 "reserve" 61 "reserve" 62 "reserve" 63 "reserve";
VAL_ 1405 RPA_Start_Notify 0 "No failure" 1 "DRIVER_DOOR_OPEN" 2 "SEATBELT_OPEN" 3 "DETECTION_NOT_DRIVER" 4 "PASSENGER_DOOR_OPEN" 5 "FRONT_HOOD_OPEN" 6 "BACK_TRUNK_OPEN" 7 "REARVIEW_MIRROR_FOLDER" 8 "CHARGING_GUN_CONNECT" 9 "TIER_PRESSURE_FAILURE" 10 "RAIN_SENSOR_FAILURE" 11 "BLUETOOTH_CONNECTION_FAIL" 12 "FRONT_AVM_FAILURE" 13 "REAR_AVM_FAILURE" 14 "LEFT_AVM_FAILURE" 15 "RIGHT_AVM_FAILURE" 16 "SONAR_CONT_FAILURE" 17 "FRONT_SONAR_FAILURE" 18 "SIDE_SONAR_FAILURE" 19 "REAR_SONAR_FAILURE" 20 "ADCU_SW_FAILURE" 21 "ADCU_SW_NOT_CALIBRATE" 22 "ADCU_HW_FAILURE" 23 "VCM_FAILURE" 24 "IBC_FAILURE" 25 "EPS_FAILURE" 26 "IMU_FAILURE" 27 "ABS_FAILURE" 28 "ESC_FAILURE" 29 "BLE_FAILURE" 30 "ABS_ACTIVE" 31 "ESC_ACTIVE" 32 "OTHER_AD_ACTIVE" 33 "MEB_ACTIVE" 34 "AEB_ACTIVE" 35 "RCTB_ACTIVE" 36 "FCTB_ACTIVE" 37 "ACU_ACTIVE" 38 "ODD_NOT_SATISFIED" 39 "SLOPE_TOO_HIGH" 40 "SPEED_TOO_HIGH" 41 "NOT_P_GEAR" 42 "RPA_NOT_OPEN" 43 "EXIT_BUTTON_PRESSED" 44 "NAVIGATION_EXIT" 45 "APA_RETURN" 46 "SCREEN_SLIDE_EXIT" 47 "SETTING_BUTTON_PRESSED" 48 "reserve" 49 "reserve" 50 "reserve" 51 "reserve" 52 "reserve" 53 "reserve" 54 "reserve" 55 "reserve" 56 "reserve" 57 "reserve" 58 "reserve" 59 "reserve" 60 "reserve" 61 "reserve" 62 "reserve" 63 "reserve";
VAL_ 1405 HPA_Learn_StartFail_Notify 0 "No failure" 1 "DRIVER_DOOR_OPEN" 2 "SEATBELT_OPEN" 3 "DETECTION_NOT_DRIVER" 4 "PASSENGER_DOOR_OPEN" 5 "FRONT_HOOD_OPEN" 6 "BACK_TRUNK_OPEN" 7 "REARVIEW_MIRROR_FOLDER" 8 "CHARGING_GUN_CONNECT" 9 "TIER_PRESSURE_FAILURE" 10 "RAIN_SENSOR_FAILURE" 11 "BLUETOOTH_CONNECTION_FAIL" 12 "FRONT_AVM_FAILURE" 13 "REAR_AVM_FAILURE" 14 "LEFT_AVM_FAILURE" 15 "RIGHT_AVM_FAILURE" 16 "SONAR_CONT_FAILURE" 17 "FRONT_SONAR_FAILURE" 18 "SIDE_SONAR_FAILURE" 19 "REAR_SONAR_FAILURE" 20 "ADCU_SW_FAILURE" 21 "ADCU_SW_NOT_CALIBRATE" 22 "ADCU_HW_FAILURE" 23 "VCM_FAILURE" 24 "IBC_FAILURE" 25 "EPS_FAILURE" 26 "IMU_FAILURE" 27 "ABS_FAILURE" 28 "ESC_FAILURE" 29 "BLE_FAILURE" 30 "ABS_ACTIVE" 31 "ESC_ACTIVE" 32 "OTHER_AD_ACTIVE" 33 "MEB_ACTIVE" 34 "AEB_ACTIVE" 35 "RCTB_ACTIVE" 36 "FCTB_ACTIVE" 37 "ACU_ACTIVE" 38 "ODD_NOT_SATISFIED" 39 "SLOPE_TOO_HIGH" 40 "SPEED_TOO_HIGH" 41 "NOT_P_GEAR" 42 "RPA_NOT_OPEN" 43 "EXIT_BUTTON_PRESSED" 44 "NAVIGATION_EXIT" 45 "APA_RETURN" 46 "SCREEN_SLIDE_EXIT" 47 "SETTING_BUTTON_PRESSED" 48 "reserve" 49 "reserve" 50 "reserve" 51 "reserve" 52 "reserve" 53 "reserve" 54 "reserve" 55 "reserve" 56 "reserve" 57 "reserve" 58 "reserve" 59 "reserve" 60 "reserve" 61 "reserve" 62 "reserve" 63 "reserve";
VAL_ 1405 HPA_Learn_Pause_Notify 0 "No Request" 1 "DRIVER_DOOR_OPEN" 2 "SEATBELT_OPEN" 3 "DETECTION_NOT_DRIVER" 4 "PASSENGER_DOOR_OPEN" 5 "FRONT_HOOD_OPEN" 6 "BACK_TRUNK_OPEN" 7 "REARVIEW_MIRROR_FOLDER" 8 "BLUETOOTH_CONNECTION_FAIL" 9 "BRAKE_TAKEOVER" 10 "OBSTACLE_ONPATH" 11 "Reserve" 12 "Reserve" 13 "Reserve" 14 "Reserve" 15 "Reserve" 16 "Reserve" 17 "Reserve" 18 "Reserve" 19 "Reserve" 20 "Reserve" 21 "Reserve" 22 "Reserve" 23 "Reserve" 24 "Reserve" 25 "Reserve" 26 "Reserve" 27 "Reserve" 28 "Reserve" 29 "Reserve" 30 "Reserve" 31 "Reserve" 32 "Reserve" 33 "Reserve" 34 "Reserve" 35 "Reserve" 36 "Reserve" 37 "Reserve" 38 "Reserve" 39 "Reserve" 40 "Reserve" 41 "Reserve" 42 "Reserve" 43 "Reserve" 44 "Reserve" 45 "Reserve" 46 "Reserve" 47 "reserve" 48 "reserve" 49 "reserve" 50 "reserve" 51 "reserve" 52 "reserve" 53 "reserve" 54 "reserve" 55 "reserve" 56 "reserve" 57 "reserve" 58 "reserve" 59 "reserve" 60 "reserve" 61 "reserve" 62 "reserve" 63 "reserve";
VAL_ 1405 HPA_Learn_Quit_Notify 0 "No Request" 1 "CHARGING_GUN_CONNECT" 2 "TIER_PRESSURE_FAILURE" 3 "RAIN_SENSOR_FAILURE" 4 "BLUETOOTH_CONNECTION_FAIL" 5 "FRONT_AVM_FAILURE" 6 "REAR_AVM_FAILURE" 7 "LEFT_AVM_FAILURE" 8 "RIGHT_AVM_FAILURE" 9 "SONAR_CONT_FAILURE" 10 "FRONT_SONAR_FAILURE" 11 "SIDE_SONAR_FAILURE" 12 "REAR_SONAR_FAILURE" 13 "ADCU_SW_FAILURE" 14 "ADCU_HW_FAILURE" 15 "VCM_FAILURE" 16 "IBC_FAILURE" 17 "EPS_FAILURE" 18 "IMU_FAILURE" 19 "ABS_FAILURE" 20 "ESC_FAILURE" 21 "BLE_FAILURE" 22 "ABS_ACTIVE" 23 "ESC_ACTIVE" 24 "OTHER_AD_ACTIVE" 25 "MEB_ACTIVE" 26 "AEB_ACTIVE" 27 "RCTB_ACTIVE" 28 "FCTB_ACTIVE" 29 "ACU_ACTIVE" 30 "ODD_NOT_SATISFIED" 31 "SLOPE_TOO_HIGH" 32 "SPEED_TOO_HIGH" 33 "THROTTLE_TAKEOVER" 34 "STEERING_TAKEOVER" 35 "GEAR_TAKEOVER" 36 "EPB_ACTIVE" 37 "TARGET_SLOT_NOT_ACTIVE" 38 "PARKING_TIMER_OVERTHRESHOLD" 39 "PAUSE_COUNT_OVERTHRESHOLD" 40 "PAUSE_TIME_OVERTHRESHOLD" 41 "SLOT_TOO_NARROW" 42 "PLANNING_TIME_OVERTHRESHOLD" 43 "STEERING_EXIT" 44 "EXIT_BUTTON_PRESSED" 45 "NAVIGATION_EXIT" 46 "APA_RETURN" 47 "SCREEN_SLIDE_EXIT" 48 "SETTING_BUTTON_PRESSED" 49 "reserve" 50 "reserve" 51 "reserve" 52 "reserve" 53 "reserve" 54 "reserve" 55 "reserve" 56 "reserve" 57 "reserve" 58 "reserve" 59 "reserve" 60 "reserve" 61 "reserve" 62 "reserve" 63 "reserve";
VAL_ 1405 HPA_Cuise_StartFail_Notify 0 "No failure" 1 "DRIVER_DOOR_OPEN" 2 "SEATBELT_OPEN" 3 "DETECTION_NOT_DRIVER" 4 "PASSENGER_DOOR_OPEN" 5 "FRONT_HOOD_OPEN" 6 "BACK_TRUNK_OPEN" 7 "REARVIEW_MIRROR_FOLDER" 8 "CHARGING_GUN_CONNECT" 9 "TIER_PRESSURE_FAILURE" 10 "RAIN_SENSOR_FAILURE" 11 "BLUETOOTH_CONNECTION_FAIL" 12 "FRONT_AVM_FAILURE" 13 "REAR_AVM_FAILURE" 14 "LEFT_AVM_FAILURE" 15 "RIGHT_AVM_FAILURE" 16 "SONAR_CONT_FAILURE" 17 "FRONT_SONAR_FAILURE" 18 "SIDE_SONAR_FAILURE" 19 "REAR_SONAR_FAILURE" 20 "ADCU_SW_FAILURE" 21 "ADCU_SW_NOT_CALIBRATE" 22 "ADCU_HW_FAILURE" 23 "VCM_FAILURE" 24 "IBC_FAILURE" 25 "EPS_FAILURE" 26 "IMU_FAILURE" 27 "ABS_FAILURE" 28 "ESC_FAILURE" 29 "BLE_FAILURE" 30 "ABS_ACTIVE" 31 "ESC_ACTIVE" 32 "OTHER_AD_ACTIVE" 33 "MEB_ACTIVE" 34 "AEB_ACTIVE" 35 "RCTB_ACTIVE" 36 "FCTB_ACTIVE" 37 "ACU_ACTIVE" 38 "ODD_NOT_SATISFIED" 39 "SLOPE_TOO_HIGH" 40 "SPEED_TOO_HIGH" 41 "NOT_P_GEAR" 42 "RPA_NOT_OPEN" 43 "EXIT_BUTTON_PRESSED" 44 "NAVIGATION_EXIT" 45 "APA_RETURN" 46 "SCREEN_SLIDE_EXIT" 47 "SETTING_BUTTON_PRESSED" 48 "reserve" 49 "reserve" 50 "reserve" 51 "reserve" 52 "reserve" 53 "reserve" 54 "reserve" 55 "reserve" 56 "reserve" 57 "reserve" 58 "reserve" 59 "reserve" 60 "reserve" 61 "reserve" 62 "reserve" 63 "reserve";
VAL_ 1405 HPA_Cuise_Pause_Notify 0 "No Request" 1 "DRIVER_DOOR_OPEN" 2 "SEATBELT_OPEN" 3 "DETECTION_NOT_DRIVER" 4 "PASSENGER_DOOR_OPEN" 5 "FRONT_HOOD_OPEN" 6 "BACK_TRUNK_OPEN" 7 "REARVIEW_MIRROR_FOLDER" 8 "BLUETOOTH_CONNECTION_FAIL" 9 "BRAKE_TAKEOVER" 10 "OBSTACLE_ONPATH" 11 "Reserve" 12 "Reserve" 13 "Reserve" 14 "Reserve" 15 "Reserve" 16 "Reserve" 17 "Reserve" 18 "Reserve" 19 "Reserve" 20 "Reserve" 21 "Reserve" 22 "Reserve" 23 "Reserve" 24 "Reserve" 25 "Reserve" 26 "Reserve" 27 "Reserve" 28 "Reserve" 29 "Reserve" 30 "Reserve" 31 "Reserve" 32 "Reserve" 33 "Reserve" 34 "Reserve" 35 "Reserve" 36 "Reserve" 37 "Reserve" 38 "Reserve" 39 "Reserve" 40 "Reserve" 41 "Reserve" 42 "Reserve" 43 "Reserve" 44 "Reserve" 45 "Reserve" 46 "Reserve" 47 "reserve" 48 "reserve" 49 "reserve" 50 "reserve" 51 "reserve" 52 "reserve" 53 "reserve" 54 "reserve" 55 "reserve" 56 "reserve" 57 "reserve" 58 "reserve" 59 "reserve" 60 "reserve" 61 "reserve" 62 "reserve" 63 "reserve";
VAL_ 1405 HPA_Cuise_Quit_Notify 0 "No Request" 1 "CHARGING_GUN_CONNECT" 2 "TIER_PRESSURE_FAILURE" 3 "RAIN_SENSOR_FAILURE" 4 "BLUETOOTH_CONNECTION_FAIL" 5 "FRONT_AVM_FAILURE" 6 "REAR_AVM_FAILURE" 7 "LEFT_AVM_FAILURE" 8 "RIGHT_AVM_FAILURE" 9 "SONAR_CONT_FAILURE" 10 "FRONT_SONAR_FAILURE" 11 "SIDE_SONAR_FAILURE" 12 "REAR_SONAR_FAILURE" 13 "ADCU_SW_FAILURE" 14 "ADCU_HW_FAILURE" 15 "VCM_FAILURE" 16 "IBC_FAILURE" 17 "EPS_FAILURE" 18 "IMU_FAILURE" 19 "ABS_FAILURE" 20 "ESC_FAILURE" 21 "BLE_FAILURE" 22 "ABS_ACTIVE" 23 "ESC_ACTIVE" 24 "OTHER_AD_ACTIVE" 25 "MEB_ACTIVE" 26 "AEB_ACTIVE" 27 "RCTB_ACTIVE" 28 "FCTB_ACTIVE" 29 "ACU_ACTIVE" 30 "ODD_NOT_SATISFIED" 31 "SLOPE_TOO_HIGH" 32 "SPEED_TOO_HIGH" 33 "THROTTLE_TAKEOVER" 34 "STEERING_TAKEOVER" 35 "GEAR_TAKEOVER" 36 "EPB_ACTIVE" 37 "TARGET_SLOT_NOT_ACTIVE" 38 "PARKING_TIMER_OVERTHRESHOLD" 39 "PAUSE_COUNT_OVERTHRESHOLD" 40 "PAUSE_TIME_OVERTHRESHOLD" 41 "SLOT_TOO_NARROW" 42 "PLANNING_TIME_OVERTHRESHOLD" 43 "STEERING_EXIT" 44 "EXIT_BUTTON_PRESSED" 45 "NAVIGATION_EXIT" 46 "APA_RETURN" 47 "SCREEN_SLIDE_EXIT" 48 "SETTING_BUTTON_PRESSED" 49 "EPB_FAILURE" 50 "reserve" 51 "reserve" 52 "reserve" 53 "reserve" 54 "reserve" 55 "reserve" 56 "reserve" 57 "reserve" 58 "reserve" 59 "reserve" 60 "reserve" 61 "reserve" 62 "reserve" 63 "reserve";
VAL_ 1405 RPA_Enter_Switch_Status 0 "Hiden" 1 "Unavailable" 2 "Available" 3 "Invalid";
VAL_ 1405 RPA_Exit_Switch_Status 0 "Hiden" 1 "Unavailable" 2 "Available" 3 "Invalid";
VAL_ 1405 RPA_Button1_Status 0 "Hiden" 1 "Unavailable" 2 "Available" 3 "Invalid";
VAL_ 1405 RPA_Button2_Status 0 "No display (hidden)" 1 "Pause Available" 2 "Pause Unavailable" 3 "Resume available" 4 "Resume unavailable" 5 "Reserve" 6 "Reserve" 7 "Invalid";
VAL_ 1405 RPA_Button3_Status 0 "Hiden" 1 "Unavailable" 2 "Available" 3 "Invalid";
VAL_ 1405 RPA_Park_StartFail_Notify 0 "No failure" 1 "DRIVER_DOOR_OPEN" 2 "reserve" 3 "reserve" 4 "PASSENGER_DOOR_OPEN" 5 "FRONT_HOOD_OPEN" 6 "BACK_TRUNK_OPEN" 7 "REARVIEW_MIRROR_FOLDER" 8 "CHARGING_GUN_CONNECT" 9 "TIER_PRESSURE_FAILURE" 10 "RAIN_SENSOR_FAILURE" 11 "BLUETOOTH_CONNECTION_FAIL" 12 "FRONT_AVM_FAILURE" 13 "REAR_AVM_FAILURE" 14 "LEFT_AVM_FAILURE" 15 "RIGHT_AVM_FAILURE" 16 "SONAR_CONT_FAILURE" 17 "FRONT_SONAR_FAILURE" 18 "SIDE_SONAR_FAILURE" 19 "REAR_SONAR_FAILURE" 20 "ADCU_SW_FAILURE" 21 "ADCU_SW_NOT_CALIBRATE" 22 "ADCU_HW_FAILURE" 23 "VCM_FAILURE" 24 "IBC_FAILURE" 25 "EPS_FAILURE" 26 "IMU_FAILURE" 27 "ABS_FAILURE" 28 "ESC_FAILURE" 29 "BLE_FAILURE" 30 "ABS_ACTIVE" 31 "ESC_ACTIVE" 32 "OTHER_AD_ACTIVE" 33 "MEB_ACTIVE" 34 "AEB_ACTIVE" 35 "RCTB_ACTIVE" 36 "FCTB_ACTIVE" 37 "ACU_ACTIVE" 38 "ODD_NOT_SATISFIED" 39 "SLOPE_TOO_HIGH" 40 "SPEED_TOO_HIGH" 41 "NOT_P_GEAR" 42 "RPA_NOT_OPEN" 43 "EXIT_BUTTON_PRESSED" 44 "NAVIGATION_EXIT" 45 "APA_RETURN" 46 "SCREEN_SLIDE_EXIT" 47 "SETTING_BUTTON_PRESSED" 48 "PARKING_CONFLICT" 49 "reserve" 50 "reserve" 51 "reserve" 52 "reserve" 53 "reserve" 54 "reserve" 55 "reserve" 56 "reserve" 57 "reserve" 58 "reserve" 59 "reserve" 60 "reserve" 61 "reserve" 62 "reserve" 63 "reserve";
VAL_ 1405 RPA_Park_Pause_Notify 0 "No Request" 1 "DRIVER_DOOR_OPEN" 2 "MoveDsitanceExceedLimit" 3 "Reserve" 4 "PASSENGER_DOOR_OPEN" 5 "FRONT_HOOD_OPEN" 6 "BACK_TRUNK_OPEN" 7 "REARVIEW_MIRROR_FOLDER" 8 "BLUETOOTH_CONNECTION_FAIL" 9 "BRAKE_TAKEOVER" 10 "OBSTACLE_ONPATH" 11 "Reserve" 12 "Reserve" 13 "Reserve" 14 "Reserve" 15 "Reserve" 16 "Reserve" 17 "Reserve" 18 "Reserve" 19 "Reserve" 20 "Reserve" 21 "Reserve" 22 "Reserve" 23 "Reserve" 24 "Reserve" 25 "Reserve" 26 "Reserve" 27 "Reserve" 28 "Reserve" 29 "Reserve" 30 "Reserve" 31 "Reserve" 32 "Reserve" 33 "Reserve" 34 "Reserve" 35 "Reserve" 36 "Reserve" 37 "Reserve" 38 "Reserve" 39 "Reserve" 40 "Reserve" 41 "Reserve" 42 "Reserve" 43 "Reserve" 44 "Reserve" 45 "Reserve" 46 "Reserve" 47 "reserve" 48 "reserve" 49 "reserve" 50 "reserve" 51 "reserve" 52 "reserve" 53 "reserve" 54 "reserve" 55 "reserve" 56 "reserve" 57 "reserve" 58 "reserve" 59 "reserve" 60 "reserve" 61 "reserve" 62 "reserve" 63 "reserve";
VAL_ 1405 RPA_Park_Quit_Notify 0 "No Request" 1 "CHARGING_GUN_CONNECT" 2 "TIER_PRESSURE_FAILURE" 3 "RAIN_SENSOR_FAILURE" 4 "BLUETOOTH_CONNECTION_FAIL" 5 "FRONT_AVM_FAILURE" 6 "REAR_AVM_FAILURE" 7 "LEFT_AVM_FAILURE" 8 "RIGHT_AVM_FAILURE" 9 "SONAR_CONT_FAILURE" 10 "FRONT_SONAR_FAILURE" 11 "SIDE_SONAR_FAILURE" 12 "REAR_SONAR_FAILURE" 13 "ADCU_SW_FAILURE" 14 "ADCU_HW_FAILURE" 15 "VCM_FAILURE" 16 "IBC_FAILURE" 17 "EPS_FAILURE" 18 "IMU_FAILURE" 19 "ABS_FAILURE" 20 "ESC_FAILURE" 21 "BLE_FAILURE" 22 "ABS_ACTIVE" 23 "ESC_ACTIVE" 24 "OTHER_AD_ACTIVE" 25 "MEB_ACTIVE" 26 "AEB_ACTIVE" 27 "RCTB_ACTIVE" 28 "FCTB_ACTIVE" 29 "ACU_ACTIVE" 30 "ODD_NOT_SATISFIED" 31 "SLOPE_TOO_HIGH" 32 "SPEED_TOO_HIGH" 33 "THROTTLE_TAKEOVER" 34 "STEERING_TAKEOVER" 35 "GEAR_TAKEOVER" 36 "EPB_ACTIVE" 37 "TARGET_SLOT_NOT_ACTIVE" 38 "PARKING_TIMER_OVERTHRESHOLD" 39 "PAUSE_COUNT_OVERTHRESHOLD" 40 "PAUSE_TIME_OVERTHRESHOLD" 41 "SLOT_TOO_NARROW" 42 "PLANNING_TIME_OVERTHRESHOLD" 43 "HANDSHAKE FAIL" 44 "EXIT_BUTTON_PRESSED" 45 "NAVIGATION_EXIT" 46 "APA_RETURN" 47 "SCREEN_SLIDE_EXIT" 48 "PARKING FAIL" 49 "PARKING SUCCESS" 50 "RPA MOVE OVER 10 Times" 51 "EPB_FAILURE" 52 "reserve" 53 "reserve" 54 "reserve" 55 "reserve" 56 "reserve" 57 "reserve" 58 "reserve" 59 "reserve" 60 "reserve" 61 "reserve" 62 "reserve" 63 "reserve";
VAL_ 1405 RPA_ModeValid 0 "RPA mode no valid" 1 "RPA mode valid";
VAL_ 1405 RPA_BLEfeedbackReq 0 "default" 1 "control enable" 2 "control disable" 3 "reserve";
VAL_ 1405 RPAparkinSelectResult 0 "Invalid" 1 "Vertical_ Left" 2 "Vertical_ Right" 3 "Vertical_ Front" 4 "Vertical_ Rear" 5 "Horizontal_Left" 6 "Horizontal_Right" 7 "reserve" 8 "reserve" 9 "reserve" 10 "reserve" 11 "reserve" 12 "reserve" 13 "reserve" 14 "reserve" 15 "reserve";
VAL_ 1405 Counter_ADCU_RPA 0 "" 1 "" 2 "" 3 "" 4 "" 5 "" 6 "" 7 "" 8 "" 9 "" 10 "" 11 "" 12 "" 13 "" 14 "" 15 "";
VAL_ 1405 CRC_ADCU_RPA 0 "" 1 "" 2 "" 3 "" 4 "" 5 "" 6 "" 7 "" 8 "" 9 "" 10 "" 11 "" 12 "" 13 "" 14 "" 15 "" 16 "" 17 "" 18 "" 19 "" 20 "" 21 "" 22 "" 23 "" 24 "" 25 "" 26 "" 27 "" 28 "" 29 "" 30 "" 31 "" 32 "" 33 "" 34 "" 35 "" 36 "" 37 "" 38 "" 39 "" 40 "" 41 "" 42 "" 43 "" 44 "" 45 "" 46 "" 47 "" 48 "" 49 "" 50 "" 51 "" 52 "" 53 "" 54 "" 55 "" 56 "" 57 "" 58 "" 59 "" 60 "" 61 "" 62 "" 63 "" 64 "" 65 "" 66 "" 67 "" 68 "" 69 "" 70 "" 71 "" 72 "" 73 "" 74 "" 75 "" 76 "" 77 "" 78 "" 79 "" 80 "" 81 "" 82 "" 83 "" 84 "" 85 "" 86 "" 87 "" 88 "" 89 "" 90 "" 91 "" 92 "" 93 "" 94 "" 95 "" 96 "" 97 "" 98 "" 99 "" 100 "" 101 "" 102 "" 103 "" 104 "" 105 "" 106 "" 107 "" 108 "" 109 "" 110 "" 111 "" 112 "" 113 "" 114 "" 115 "" 116 "" 117 "" 118 "" 119 "" 120 "" 121 "" 122 "" 123 "" 124 "" 125 "" 126 "" 127 "" 128 "" 129 "" 130 "" 131 "" 132 "" 133 "" 134 "" 135 "" 136 "" 137 "" 138 "" 139 "" 140 "" 141 "" 142 "" 143 "" 144 "" 145 "" 146 "" 147 "" 148 "" 149 "" 150 "" 151 "" 152 "" 153 "" 154 "" 155 "" 156 "" 157 "" 158 "" 159 "" 160 "" 161 "" 162 "" 163 "" 164 "" 165 "" 166 "" 167 "" 168 "" 169 "" 170 "" 171 "" 172 "" 173 "" 174 "" 175 "" 176 "" 177 "" 178 "" 179 "" 180 "" 181 "" 182 "" 183 "" 184 "" 185 "" 186 "" 187 "" 188 "" 189 "" 190 "" 191 "" 192 "" 193 "" 194 "" 195 "" 196 "" 197 "" 198 "" 199 "" 200 "" 201 "" 202 "" 203 "" 204 "" 205 "" 206 "" 207 "" 208 "" 209 "" 210 "" 211 "" 212 "" 213 "" 214 "" 215 "" 216 "" 217 "" 218 "" 219 "" 220 "" 221 "" 222 "" 223 "" 224 "" 225 "" 226 "" 227 "" 228 "" 229 "" 230 "" 231 "" 232 "" 233 "" 234 "" 235 "" 236 "" 237 "" 238 "" 239 "" 240 "" 241 "" 242 "" 243 "" 244 "" 245 "" 246 "" 247 "" 248 "" 249 "" 250 "" 251 "" 252 "" 253 "" 254 "" 255 "";
VAL_ 1445 APASwitchReq 0 "No switch request" 1 "Enter" 2 "Exit" 3 "Reserve";
VAL_ 1445 APAButtonReq 0 "No button request" 1 "Park start" 2 "Park pause" 3 "Park resume" 4 "Park stop" 5 "RPA start request" 6 "RPA stop request" 7 "HPA learn start" 8 "HPA learn stop" 9 "HPA cruise start" 10 "HPA cruise pause" 11 "HPA cruise resume" 12 "HPA cruise stop" 13 "reserve" 14 "reserve" 15 "reserve" 16 "reserve" 17 "reserve" 18 "reserve" 19 "reserve" 20 "reserve" 21 "reserve" 22 "reserve" 23 "reserve" 24 "reserve" 25 "reserve" 26 "reserve" 27 "reserve" 28 "reserve" 29 "reserve" 30 "reserve" 31 "reserve";
VAL_ 1445 APA_ParkSpot_Select 0 "Default (no select)" 1 "Spot ID <value>" 2 "Spot ID <value>" 3 "Spot ID <value>" 4 "Spot ID <value>" 5 "Spot ID <value>" 6 "Spot ID <value>" 7 "Spot ID <value>" 8 "Spot ID <value>" 9 "Spot ID <value>" 10 "Spot ID <value>" 11 "Spot ID <value>" 12 "Spot ID <value>" 13 "Spot ID <value>" 14 "Spot ID <value>" 15 "Spot ID <value>" 16 "Spot ID <value>" 17 "Spot ID <value>" 18 "Spot ID <value>" 19 "Spot ID <value>" 20 "Spot ID <value>" 21 "Spot ID <value>" 22 "Spot ID <value>" 23 "Spot ID <value>" 24 "Spot ID <value>" 25 "Spot ID <value>" 26 "Spot ID <value>" 27 "Spot ID <value>" 28 "Spot ID <value>" 29 "Spot ID <value>" 30 "Spot ID <value>" 31 "Spot ID <value>" 32 "Spot ID <value>" 33 "Spot ID <value>" 34 "Spot ID <value>" 35 "Spot ID <value>" 36 "Spot ID <value>" 37 "Spot ID <value>" 38 "Spot ID <value>" 39 "Spot ID <value>" 40 "Spot ID <value>" 41 "Spot ID <value>" 42 "Spot ID <value>" 43 "Spot ID <value>" 44 "Spot ID <value>" 45 "Spot ID <value>" 46 "Spot ID <value>" 47 "Spot ID <value>" 48 "Spot ID <value>" 49 "Spot ID <value>" 50 "Spot ID <value>" 51 "Spot ID <value>" 52 "Spot ID <value>" 53 "Spot ID <value>" 54 "Spot ID <value>" 55 "Spot ID <value>" 56 "Spot ID <value>" 57 "Spot ID <value>" 58 "Spot ID <value>" 59 "Spot ID <value>" 60 "Spot ID <value>" 61 "Spot ID <value>" 62 "Spot ID <value>" 63 "Spot ID <value>" 64 "Spot ID <value>" 65 "Spot ID <value>" 66 "Spot ID <value>" 67 "Spot ID <value>" 68 "Spot ID <value>" 69 "Spot ID <value>" 70 "Spot ID <value>" 71 "Spot ID <value>" 72 "Spot ID <value>" 73 "Spot ID <value>" 74 "Spot ID <value>" 75 "Spot ID <value>" 76 "Spot ID <value>" 77 "Spot ID <value>" 78 "Spot ID <value>" 79 "Spot ID <value>" 80 "Spot ID <value>" 81 "Spot ID <value>" 82 "Spot ID <value>" 83 "Spot ID <value>" 84 "Spot ID <value>" 85 "Spot ID <value>" 86 "Spot ID <value>" 87 "Spot ID <value>" 88 "Spot ID <value>" 89 "Spot ID <value>" 90 "Spot ID <value>" 91 "Spot ID <value>" 92 "Spot ID <value>" 93 "Spot ID <value>" 94 "Spot ID <value>" 95 "Spot ID <value>" 96 "Spot ID <value>" 97 "Spot ID <value>" 98 "Spot ID <value>" 99 "Spot ID <value>" 100 "Spot ID <value>" 101 "Spot ID <value>" 102 "Spot ID <value>" 103 "Spot ID <value>" 104 "Spot ID <value>" 105 "Spot ID <value>" 106 "Spot ID <value>" 107 "Spot ID <value>" 108 "Spot ID <value>" 109 "Spot ID <value>" 110 "Spot ID <value>" 111 "Spot ID <value>" 112 "Spot ID <value>" 113 "Spot ID <value>" 114 "Spot ID <value>" 115 "Spot ID <value>" 116 "Spot ID <value>" 117 "Spot ID <value>" 118 "Spot ID <value>" 119 "Spot ID <value>" 120 "Spot ID <value>" 121 "Spot ID <value>" 122 "Spot ID <value>" 123 "Spot ID <value>" 124 "Spot ID <value>" 125 "Spot ID <value>" 126 "Spot ID <value>" 127 "Spot ID <value>" 128 "Spot ID <value>" 129 "Spot ID <value>" 130 "Spot ID <value>" 131 "Spot ID <value>" 132 "Spot ID <value>" 133 "Spot ID <value>" 134 "Spot ID <value>" 135 "Spot ID <value>" 136 "Spot ID <value>" 137 "Spot ID <value>" 138 "Spot ID <value>" 139 "Spot ID <value>" 140 "Spot ID <value>" 141 "Spot ID <value>" 142 "Spot ID <value>" 143 "Spot ID <value>" 144 "Spot ID <value>" 145 "Spot ID <value>" 146 "Spot ID <value>" 147 "Spot ID <value>" 148 "Spot ID <value>" 149 "Spot ID <value>" 150 "Spot ID <value>" 151 "Spot ID <value>" 152 "Spot ID <value>" 153 "Spot ID <value>" 154 "Spot ID <value>" 155 "Spot ID <value>" 156 "Spot ID <value>" 157 "Spot ID <value>" 158 "Spot ID <value>" 159 "Spot ID <value>" 160 "Spot ID <value>" 161 "Spot ID <value>" 162 "Spot ID <value>" 163 "Spot ID <value>" 164 "Spot ID <value>" 165 "Spot ID <value>" 166 "Spot ID <value>" 167 "Spot ID <value>" 168 "Spot ID <value>" 169 "Spot ID <value>" 170 "Spot ID <value>" 171 "Spot ID <value>" 172 "Spot ID <value>" 173 "Spot ID <value>" 174 "Spot ID <value>" 175 "Spot ID <value>" 176 "Spot ID <value>" 177 "Spot ID <value>" 178 "Spot ID <value>" 179 "Spot ID <value>" 180 "Spot ID <value>" 181 "Spot ID <value>" 182 "Spot ID <value>" 183 "Spot ID <value>" 184 "Spot ID <value>" 185 "Spot ID <value>" 186 "Spot ID <value>" 187 "Spot ID <value>" 188 "Spot ID <value>" 189 "Spot ID <value>" 190 "Spot ID <value>" 191 "Spot ID <value>" 192 "Spot ID <value>" 193 "Spot ID <value>" 194 "Spot ID <value>" 195 "Spot ID <value>" 196 "Spot ID <value>" 197 "Spot ID <value>" 198 "Spot ID <value>" 199 "Spot ID <value>" 200 "Spot ID <value>" 201 "Spot ID <value>" 202 "Spot ID <value>" 203 "Spot ID <value>" 204 "Spot ID <value>" 205 "Spot ID <value>" 206 "Spot ID <value>" 207 "Spot ID <value>" 208 "Spot ID <value>" 209 "Spot ID <value>" 210 "Spot ID <value>" 211 "Spot ID <value>" 212 "Spot ID <value>" 213 "Spot ID <value>" 214 "Spot ID <value>" 215 "Spot ID <value>" 216 "Spot ID <value>" 217 "Spot ID <value>" 218 "Spot ID <value>" 219 "Spot ID <value>" 220 "Spot ID <value>" 221 "Spot ID <value>" 222 "Spot ID <value>" 223 "Spot ID <value>" 224 "Spot ID <value>" 225 "Spot ID <value>" 226 "Spot ID <value>" 227 "Spot ID <value>" 228 "Spot ID <value>" 229 "Spot ID <value>" 230 "Spot ID <value>" 231 "Spot ID <value>" 232 "Spot ID <value>" 233 "Spot ID <value>" 234 "Spot ID <value>" 235 "Spot ID <value>" 236 "Spot ID <value>" 237 "Spot ID <value>" 238 "Spot ID <value>" 239 "Spot ID <value>" 240 "Spot ID <value>" 241 "Spot ID <value>" 242 "Spot ID <value>" 243 "Spot ID <value>" 244 "Spot ID <value>" 245 "Spot ID <value>" 246 "Spot ID <value>" 247 "Spot ID <value>" 248 "Spot ID <value>" 249 "Spot ID <value>" 250 "Spot ID <value>" 251 "Spot ID <value>" 252 "Spot ID <value>" 253 "Spot ID <value>" 254 "Spot ID <value>";
VAL_ 1445 APA_ParkinDir_Select 0 "Invalid" 1 "Head in" 2 "Tail in" 3 "reserve";
VAL_ 1445 APA_parkoutDir_Select 0 "Invalid" 1 "Front left" 2 "Front straight" 3 "Front right" 4 "Rear left" 5 "Rear straight" 6 "Rear right" 7 "reserve" 8 "reserve" 9 "reserve" 10 "reserve" 11 "reserve" 12 "reserve" 13 "reserve" 14 "reserve" 15 "reserve";
VAL_ 1445 APA_Setting_Request 0 "No setting request" 1 "HPA on" 2 "HPA off" 3 "HPA suggest on" 4 "HPA suggest off" 5 "RPA on" 6 "RPA off" 7 "APA suggest on" 8 "APA suggest off" 9 "USS Disp on" 10 "USS Disp off" 11 "Park speed low" 12 "Park speed medium" 13 "Park speed high" 14 "Cuise speed low" 15 "Cuise speed medium" 16 "Cuise speed high" 17 "TTS Play Remind on" 18 "TTS Play Remind off" 19 "reserve" 20 "reserve" 21 "reserve" 22 "reserve" 23 "reserve" 24 "reserve" 25 "reserve" 26 "reserve" 27 "reserve" 28 "reserve" 29 "reserve" 30 "reserve" 31 "reserve";
VAL_ 1445 APA_PopUp_Response 0 "No response" 1 "Confirm" 2 "Exit/Cancel" 3 "reserve";
VAL_ 1445 HPA_Route_Select 0 "No route select" 1 "Route ID 1" 2 "Route ID 2" 3 "Route ID 3" 4 "Route ID 4" 5 "Route ID 5" 6 "Route ID 6" 7 "Route ID 7" 8 "Route ID 8" 9 "Route ID 9" 10 "Route ID 10" 11 "Route ID 11" 12 "Route ID 12" 13 "Route ID 13" 14 "Route ID 14" 15 "Route ID 15" 16 "Route ID 16" 17 "Route ID 17" 18 "Route ID 18" 19 "Route ID 19" 20 "Route ID 20" 21 "reserve" 22 "reserve" 23 "reserve" 24 "reserve" 25 "reserve" 26 "reserve" 27 "reserve" 28 "reserve" 29 "reserve" 30 "reserve" 31 "reserve";
VAL_ 1445 HPA_Route_Delete 0 "No request" 1 "Request to delete";
VAL_ 1445 CFDI_ALL_SW 0 "No Request" 1 "CDFI ALL DATA ON" 2 "CDFI ALL DATA OFF" 3 "Reserved";
VAL_ 1445 CFDI_PD_SW 0 "No Request" 1 "CDFI PERSONAL DATA ON" 2 "CDFI PERSONAL DATA OFF" 3 "CDFI PERSONAL DATA DELETE";
VAL_ 1445 Counter_CDC_APA 0 "" 1 "" 2 "" 3 "" 4 "" 5 "" 6 "" 7 "" 8 "" 9 "" 10 "" 11 "" 12 "" 13 "" 14 "" 15 "";
VAL_ 1445 CRC_CDC_APA 0 "" 1 "" 2 "" 3 "" 4 "" 5 "" 6 "" 7 "" 8 "" 9 "" 10 "" 11 "" 12 "" 13 "" 14 "" 15 "" 16 "" 17 "" 18 "" 19 "" 20 "" 21 "" 22 "" 23 "" 24 "" 25 "" 26 "" 27 "" 28 "" 29 "" 30 "" 31 "" 32 "" 33 "" 34 "" 35 "" 36 "" 37 "" 38 "" 39 "" 40 "" 41 "" 42 "" 43 "" 44 "" 45 "" 46 "" 47 "" 48 "" 49 "" 50 "" 51 "" 52 "" 53 "" 54 "" 55 "" 56 "" 57 "" 58 "" 59 "" 60 "" 61 "" 62 "" 63 "" 64 "" 65 "" 66 "" 67 "" 68 "" 69 "" 70 "" 71 "" 72 "" 73 "" 74 "" 75 "" 76 "" 77 "" 78 "" 79 "" 80 "" 81 "" 82 "" 83 "" 84 "" 85 "" 86 "" 87 "" 88 "" 89 "" 90 "" 91 "" 92 "" 93 "" 94 "" 95 "" 96 "" 97 "" 98 "" 99 "" 100 "" 101 "" 102 "" 103 "" 104 "" 105 "" 106 "" 107 "" 108 "" 109 "" 110 "" 111 "" 112 "" 113 "" 114 "" 115 "" 116 "" 117 "" 118 "" 119 "" 120 "" 121 "" 122 "" 123 "" 124 "" 125 "" 126 "" 127 "" 128 "" 129 "" 130 "" 131 "" 132 "" 133 "" 134 "" 135 "" 136 "" 137 "" 138 "" 139 "" 140 "" 141 "" 142 "" 143 "" 144 "" 145 "" 146 "" 147 "" 148 "" 149 "" 150 "" 151 "" 152 "" 153 "" 154 "" 155 "" 156 "" 157 "" 158 "" 159 "" 160 "" 161 "" 162 "" 163 "" 164 "" 165 "" 166 "" 167 "" 168 "" 169 "" 170 "" 171 "" 172 "" 173 "" 174 "" 175 "" 176 "" 177 "" 178 "" 179 "" 180 "" 181 "" 182 "" 183 "" 184 "" 185 "" 186 "" 187 "" 188 "" 189 "" 190 "" 191 "" 192 "" 193 "" 194 "" 195 "" 196 "" 197 "" 198 "" 199 "" 200 "" 201 "" 202 "" 203 "" 204 "" 205 "" 206 "" 207 "" 208 "" 209 "" 210 "" 211 "" 212 "" 213 "" 214 "" 215 "" 216 "" 217 "" 218 "" 219 "" 220 "" 221 "" 222 "" 223 "" 224 "" 225 "" 226 "" 227 "" 228 "" 229 "" 230 "" 231 "" 232 "" 233 "" 234 "" 235 "" 236 "" 237 "" 238 "" 239 "" 240 "" 241 "" 242 "" 243 "" 244 "" 245 "" 246 "" 247 "" 248 "" 249 "" 250 "" 251 "" 252 "" 253 "" 254 "" 255 "";
VAL_ 1393 RPA_Switch_Request 0 "No switch request" 1 "Enter" 2 "Exit" 3 "Reserve";
VAL_ 1393 RPA_Button_Request 0 "no button request" 1 "parkin start" 2 "parkin pause" 3 "parkin resume" 4 "parkin stop" 5 "parkout start" 6 "parkout pause" 7 "parkout resume" 8 "parkout stop" 9 "RPA Ahead" 10 "RPA Back" 11 "Parkin/out Entrance" 12 "Straight Entrance" 13 "reserve" 14 "reserve" 15 "reserve";
VAL_ 1393 RPA_ControlButton_Valid 0 "invalid" 1 "valid";
VAL_ 1393 RPA_parkoutDir_Select 0 "Front left" 1 "Front straight" 2 "Front right" 3 "Rear left" 4 "Rear straight" 5 "Rear right" 6 "reserve" 7 "reserve" 8 "reserve" 9 "reserve" 10 "reserve" 11 "reserve" 12 "reserve" 13 "reserve" 14 "reserve" 15 "invalid";
VAL_ 1393 RPA_PopUP_Response 0 "No response" 1 "Confirm" 2 "Exit/Cancel" 3 "reserve";
VAL_ 1393 RPA_BLE_Status 0 "no fail" 1 "failed";
VAL_ 1393 RPA_BLE_Connect_Status 0 "No connect" 1 "Connected" 2 "connecting" 3 "reserve";
VAL_ 1393 RPA_BLE_Control_Active 0 "no active" 1 "active";
VAL_ 1393 RPA_BLE_Mode_Valid 0 "no valid" 1 "valid";
VAL_ 1393 RPA_BLE_Control_Request 0 "No Request" 1 "Request APA Control" 2 "controled" 3 "Invalid";
VAL_ 1228 PEBS_INFO 0 "OFF" 1 "Standby" 2 "Active" 3 "Reserved" 4 "PERM FAULT" 5 "Blindness" 6 "Reserved";
VAL_ 1228 ACC_INFO 0 "OFF" 1 "Standby" 2 "Active" 3 "Reserved" 4 "Reserved" 5 "Blindness" 6 "Passive" 7 "Override";
VAL_ 1647 FrHeatWire_Status 0 "close" 1 "open";
VAL_ 1647 FrHeatWireCircuit_Status 0 "normal" 1 "short-circuit" 2 "Open circuit" 3 "Invalid";
VAL_ 1647 VoltageSupply_BCM 0 "0-30V" 1 "0-30V" 2 "0-30V" 3 "0-30V" 4 "0-30V" 5 "0-30V" 6 "0-30V" 7 "0-30V" 8 "0-30V" 9 "0-30V" 10 "0-30V" 11 "0-30V" 12 "0-30V" 13 "0-30V" 14 "0-30V" 15 "0-30V" 16 "0-30V" 17 "0-30V" 18 "0-30V" 19 "0-30V" 20 "0-30V" 21 "0-30V" 22 "0-30V" 23 "0-30V" 24 "0-30V" 25 "0-30V" 26 "0-30V" 27 "0-30V" 28 "0-30V" 29 "0-30V" 31 "Invalid";
VAL_ 1032 GNSS_status 0 "normal" 1 "abnormal";
VAL_ 1032 GNSS_position_type 0 "nofix" 1 "SPPfix";
VAL_ 1032 GNSS_tSync_status 0 "sync normal" 1 "sync abnormal";
VAL_ 1493 DMS_STA 0 "OFF" 1 "Failure" 2 "Passive" 3 "Standby" 4 "Active" 5 "Not used" 6 "Not used" 7 "Invalid";
VAL_ 1493 DMS_E_FAILURE 0 "Camera occlusion not due to steering wheel" 1 "Camera occlusion due to steering wheel" 2 "No occlusion" 3 "Invalid";
VAL_ 1493 DMS_S_FAILURE 0 "Image overexposure" 1 "Image overdimming" 2 "Frame freeze" 3 "Frame tear" 4 "Dynamic calibration failure" 5 "Camera hardware failure" 6 "CAN communication failure" 7 "VCM sensor failure" 8 "IBCM sensor failure" 9 "No failure" 10 "Not used" 11 "Not used" 12 "Not used" 13 "Not used" 14 "Not used" 15 "Invalid";
VAL_ 1493 DD_SW_RESP 0 "ON" 1 "OFF" 2 "Not used" 3 "Invalid";
VAL_ 1493 DA_SW_RESP 0 "ON" 1 "OFF" 2 "Not used" 3 "Invalid";
VAL_ 1493 DD_SENSITIVITY_SW_RESP 0 "Low" 1 "High" 2 "Not used" 3 "Invalid";
VAL_ 1493 DMS_HEAD_DETECT 0 "Head exist" 1 "Head not exist" 2 "Not used" 3 "Invalid";
VAL_ 1493 DMS_FACE_DETECT 0 "Face not occluded" 1 "Face occluded" 2 "Not used" 3 "Invalid";
VAL_ 1493 DROWNINESS_LV 0 "Awaked" 1 "Level 1" 2 "Level 2" 3 "Driver unresponsive" 4 "Not used" 5 "Not used" 6 "Not used" 7 "Invalid";
VAL_ 1493 DISTRACTION_LV 0 "Focused" 1 "Level 1" 2 "Level 2" 3 "Driver unresponsive" 4 "Not used" 5 "Not used" 6 "Not used" 7 "Invalid";
VAL_ 1493 DANGEROUS_ACT 0 "No dangerous behavior" 1 "Smoking" 2 "Calling" 3 "Invalid";
VAL_ 1493 Driver_X 0 "" 1 "";
VAL_ 1493 Driver_Y 0 "" 1 "" 2 "" 3 "" 4 "" 5 "" 6 "" 7 "";
VAL_ 1493 Driver_Z 0 "" 1 "" 2 "" 3 "" 4 "" 5 "" 6 "" 7 "" 8 "" 9 "" 10 "" 11 "" 12 "" 13 "" 14 "" 15 "" 16 "" 17 "" 18 "" 19 "" 20 "" 21 "" 22 "" 23 "" 24 "" 25 "" 26 "" 27 "" 28 "" 29 "" 30 "" 31 "" 32 "" 33 "" 34 "" 35 "" 36 "" 37 "" 38 "" 39 "" 40 "" 41 "" 42 "" 43 "" 44 "" 45 "" 46 "" 47 "" 48 "" 49 "" 50 "" 51 "" 52 "" 53 "" 54 "" 55 "" 56 "" 57 "" 58 "" 59 "" 60 "" 61 "" 62 "" 63 "" 64 "" 65 "" 66 "" 67 "" 68 "" 69 "" 70 "" 71 "" 72 "" 73 "" 74 "" 75 "" 76 "" 77 "" 78 "" 79 "" 80 "" 81 "" 82 "" 83 "" 84 "" 85 "" 86 "" 87 "" 88 "" 89 "" 90 "" 91 "" 92 "" 93 "" 94 "" 95 "" 96 "" 97 "" 98 "" 99 "" 100 "" 101 "" 102 "" 103 "" 104 "" 105 "" 106 "" 107 "" 108 "" 109 "" 110 "" 111 "" 112 "" 113 "" 114 "" 115 "" 116 "" 117 "" 118 "" 119 "" 120 "" 121 "" 122 "" 123 "" 124 "" 125 "" 126 "" 127 "";
